VERSION "dbc-export 1 2025.20.8"

NS_ :

BS_:

BU_: APP BMS CC CMP CMPD CP DAS DI DIF DIR EPBL EPBR EVSE FC GTW HCML HCMR HVP ICR PCS PM PMF PMR PTC SCCM SCM SCS SDCR TAS UMC VC VCFRONT VCLEFT VCRIGHT VCSEC

BO_ 1444 PM_alertLog: 8 PM
 SG_ PM_alertID M : 0|7@1+ (1,0) [0|127] "" Vector__XXX
 SG_ PM_alertState : 15|1@1+ (1,0) [0|1] "" Vector__XXX
 SG_ PM_a001_w0 m1 : 16|16@1+ (1,0) [0|65535] "" Vector__XXX
 SG_ PM_a001_w1 m1 : 32|16@1+ (1,0) [0|65535] "" Vector__XXX
 SG_ PM_a001_w2 m1 : 48|16@1+ (1,0) [0|65535] "" Vector__XXX
 SG_ PM_a002_torqueAverage m2 : 16|1@1+ (1,0) [0|1] "" Vector__XXX
 SG_ PM_a002_torqueWindow m2 : 17|1@1+ (1,0) [0|1] "" Vector__XXX
 SG_ PM_a002_torqueMeasured m2 : 18|13@1- (2,0) [-8192|8190] "Nm" Vector__XXX
 SG_ PM_a002_torqueAccelAverage m2 : 32|13@1- (2,0) [-8192|8190] "Nm" Vector__XXX
 SG_ PM_a002_torqueAccelWindow m2 : 48|13@1- (2,0) [-8192|8190] "Nm" Vector__XXX
 SG_ PM_a003_reverseGear m3 : 16|1@1+ (1,0) [0|1] "" Vector__XXX
 SG_ PM_a003_pedalPos m3 : 24|8@1+ (0.4,0) [0|102] "%" Vector__XXX
 SG_ PM_a003_zeroPointPedal m3 : 32|8@1+ (0.4,0) [0|102] "%" Vector__XXX
 SG_ PM_a004_torqueAverage m4 : 16|1@1+ (1,0) [0|1] "" Vector__XXX
 SG_ PM_a004_torqueWindow m4 : 17|1@1+ (1,0) [0|1] "" Vector__XXX
 SG_ PM_a004_torqueMeasured m4 : 18|13@1- (2,0) [-8192|8190] "Nm" Vector__XXX
 SG_ PM_a004_torqueDecelAverage m4 : 32|13@1- (2,0) [-8192|8190] "Nm" Vector__XXX
 SG_ PM_a004_torqueDecelWindow m4 : 48|13@1- (2,0) [-8192|8190] "Nm" Vector__XXX
 SG_ PM_a005_torqueReason m5 : 16|2@1+ (1,0) [0|3] "" Vector__XXX
 SG_ PM_a005_torqueMeasured m5 : 18|13@1- (2,0) [-8192|8190] "Nm" Vector__XXX
 SG_ PM_a005_iDQmagnitude m5 : 32|16@1- (0.0939,0) [-3076.9152|3076.8213] "A" Vector__XXX
 SG_ PM_a006_unknownGearAllowed m6 : 16|1@1+ (1,0) [0|1] "" Vector__XXX
 SG_ PM_a006_parkGearAllowed m6 : 17|1@1+ (1,0) [0|1] "" Vector__XXX
 SG_ PM_a006_reverseGearAllowed m6 : 18|1@1+ (1,0) [0|1] "" Vector__XXX
 SG_ PM_a006_neutralGearAllowed m6 : 19|1@1+ (1,0) [0|1] "" Vector__XXX
 SG_ PM_a006_driveGearAllowed m6 : 20|1@1+ (1,0) [0|1] "" Vector__XXX
 SG_ PM_a006_shiftState m6 : 21|3@1+ (1,0) [0|6] "" Vector__XXX
 SG_ PM_a006_brakePedalPress m6 : 24|1@1+ (1,0) [0|1] "" Vector__XXX
 SG_ PM_a006_accelPedalBelowLimit m6 : 25|1@1+ (1,0) [0|1] "" Vector__XXX
 SG_ PM_a006_allowReverseShiftSpeed m6 : 26|1@1+ (1,0) [0|1] "" Vector__XXX
 SG_ PM_a006_allowDriveShiftSpeed m6 : 27|1@1+ (1,0) [0|1] "" Vector__XXX
 SG_ PM_a006_requireAccelPedalCheckSp m6 : 28|1@1+ (1,0) [0|1] "" Vector__XXX
 SG_ PM_a006_requireParkSpeed m6 : 29|1@1+ (1,0) [0|1] "" Vector__XXX
 SG_ PM_a006_stalkCommandP m6 : 30|1@1+ (1,0) [0|1] "" Vector__XXX
 SG_ PM_a006_stalkCommandR m6 : 31|1@1+ (1,0) [0|1] "" Vector__XXX
 SG_ PM_a006_stalkCommandN m6 : 32|1@1+ (1,0) [0|1] "" Vector__XXX
 SG_ PM_a006_stalkCommandD m6 : 33|1@1+ (1,0) [0|1] "" Vector__XXX
 SG_ PM_a006_unsecuredNeutralRequest m6 : 34|1@1+ (1,0) [0|1] "" Vector__XXX
 SG_ PM_a006_recentGearChange m6 : 35|1@1+ (1,0) [0|1] "" Vector__XXX
 SG_ PM_a006_smartShiftCommandD m6 : 36|1@1+ (1,0) [0|1] "" Vector__XXX
 SG_ PM_a006_smartShiftCommandR m6 : 37|1@1+ (1,0) [0|1] "" Vector__XXX
 SG_ PM_a006_driverSeatbeltBuckled m6 : 38|1@1+ (1,0) [0|1] "" Vector__XXX
 SG_ PM_a006_secGearSelRisingEdgeR m6 : 39|1@1+ (1,0) [0|1] "" Vector__XXX
 SG_ PM_a006_secGearSelRisingEdgeN m6 : 40|1@1+ (1,0) [0|1] "" Vector__XXX
 SG_ PM_a006_secGearSelRisingEdgeD m6 : 41|1@1+ (1,0) [0|1] "" Vector__XXX
 SG_ PM_a007_IBST_party1 m7 : 16|1@1+ (1,0) [0|1] "" Vector__XXX
 SG_ PM_a007_BUS1_IBST_status m7 : 17|1@1+ (1,0) [0|1] "" Vector__XXX
 SG_ PM_a007_BUS2_IBST_status m7 : 18|1@1+ (1,0) [0|1] "" Vector__XXX
 SG_ PM_a009_ESP_brakeTorque m9 : 16|1@1+ (1,0) [0|1] "" Vector__XXX
 SG_ PM_a009_ESP_motorLimits m9 : 17|1@1+ (1,0) [0|1] "" Vector__XXX
 SG_ PM_a009_ESP_offsets m9 : 18|1@1+ (1,0) [0|1] "" Vector__XXX
 SG_ PM_a009_ESP_party3 m9 : 19|1@1+ (1,0) [0|1] "" Vector__XXX
 SG_ PM_a009_ESP_status m9 : 20|1@1+ (1,0) [0|1] "" Vector__XXX
 SG_ PM_a009_ESP_wheelSpeeds m9 : 21|1@1+ (1,0) [0|1] "" Vector__XXX
 SG_ PM_a010_messageId m10 : 16|16@1+ (1,0) [0|65535] "" Vector__XXX
 SG_ PM_a010_DI_status m10 : 32|1@1+ (1,0) [0|1] "" Vector__XXX
 SG_ PM_a010_DI_torque m10 : 33|1@1+ (1,0) [0|1] "" Vector__XXX
 SG_ PM_a010_DI_slaveCommand m10 : 34|1@1+ (1,0) [0|1] "" Vector__XXX
 SG_ PM_a010_DI_locStatus m10 : 35|1@1+ (1,0) [0|1] "" Vector__XXX
 SG_ PM_a010_DI_speed m10 : 36|1@1+ (1,0) [0|1] "" Vector__XXX
 SG_ PM_a010_DI_systemStatus m10 : 37|1@1+ (1,0) [0|1] "" Vector__XXX
 SG_ PM_a010_DI_chassisControl m10 : 38|1@1+ (1,0) [0|1] "" Vector__XXX
 SG_ PM_a010_DI_chassisControl2 m10 : 39|1@1+ (1,0) [0|1] "" Vector__XXX
 SG_ PM_a010_vdcLeft m10 : 40|1@1+ (1,0) [0|1] "" Vector__XXX
 SG_ PM_a010_vdcRight m10 : 41|1@1+ (1,0) [0|1] "" Vector__XXX
 SG_ PM_a010_DI_vehicleEstimates m10 : 42|1@1+ (1,0) [0|1] "" Vector__XXX
 SG_ PM_a010_DI_brakeCommand m10 : 43|1@1+ (1,0) [0|1] "" Vector__XXX
 SG_ PM_a010_DI_difCommand m10 : 44|1@1+ (1,0) [0|1] "" Vector__XXX
 SG_ PM_a010_DI_dirCommand m10 : 45|1@1+ (1,0) [0|1] "" Vector__XXX
 SG_ PM_a010_DI_dirVehicle m10 : 46|1@1+ (1,0) [0|1] "" Vector__XXX
 SG_ PM_a010_DI_locStatus2 m10 : 47|1@1+ (1,0) [0|1] "" Vector__XXX
 SG_ PM_a010_stalklessInterfaces m10 : 48|1@1+ (1,0) [0|1] "" Vector__XXX
 SG_ PM_a011_pmfHvilStatus m11 : 16|2@1+ (1,0) [0|2] "" Vector__XXX
 SG_ PM_a011_pmfStatusValid m11 : 18|1@1+ (1,0) [0|1] "" Vector__XXX
 SG_ PM_a011_pmrHvilStatus m11 : 19|2@1+ (1,0) [0|2] "" Vector__XXX
 SG_ PM_a011_pmrStatusValid m11 : 21|1@1+ (1,0) [0|1] "" Vector__XXX
 SG_ PM_a011_vehiclePowerState m11 : 22|2@1+ (1,0) [0|3] "" Vector__XXX
 SG_ PM_a011_hvilSystemStatus m11 : 24|2@1+ (1,0) [0|2] "" Vector__XXX
 SG_ PM_a012_canID m12 : 16|12@1+ (1,0) [0|4095] "" Vector__XXX
 SG_ PM_a012_errorType m12 : 28|3@1+ (1,0) [0|7] "" Vector__XXX
 SG_ PM_a012_badValue1 m12 : 32|16@1+ (1,0) [0|65535] "" Vector__XXX
 SG_ PM_a012_badValue2 m12 : 48|16@1+ (1,0) [0|65535] "" Vector__XXX
 SG_ PM_a013_mailboxID m13 : 16|16@1+ (1,0) [0|65535] "" Vector__XXX
 SG_ PM_a013_canID m13 : 32|16@1+ (1,0) [0|65535] "" Vector__XXX
 SG_ PM_a013_errorType m13 : 48|3@1+ (1,0) [0|7] "" Vector__XXX
 SG_ PM_a014_track1Voltage m14 : 16|16@1+ (0.001,0) [0|65.535] "V" Vector__XXX
 SG_ PM_a014_track2Voltage m14 : 32|16@1+ (0.001,0) [0|65.535] "V" Vector__XXX
 SG_ PM_a014_accelErrorType m14 : 48|2@1+ (1,0) [1|3] "" Vector__XXX
 SG_ PM_a015_SCCM_rightStalk m15 : 16|1@1+ (1,0) [0|1] "" Vector__XXX
 SG_ PM_a016_BB_status m16 : 16|1@1+ (1,0) [0|1] "" Vector__XXX
 SG_ PM_a016_BB_brakeActuation m16 : 17|1@1+ (1,0) [0|1] "" Vector__XXX
 SG_ PM_a017_EPBL_status m17 : 16|1@1+ (1,0) [0|1] "" Vector__XXX
 SG_ PM_a017_EPBR_status m17 : 17|1@1+ (1,0) [0|1] "" Vector__XXX
 SG_ PM_a021_torque m21 : 16|1@1+ (1,0) [0|1] "" Vector__XXX
 SG_ PM_a021_capability m21 : 17|1@1+ (1,0) [0|1] "" Vector__XXX
 SG_ PM_a021_status m21 : 18|1@1+ (1,0) [0|1] "" Vector__XXX
 SG_ PM_a021_capability2 m21 : 19|1@1+ (1,0) [0|1] "" Vector__XXX
 SG_ PM_a021_power m21 : 20|1@1+ (1,0) [0|1] "" Vector__XXX
 SG_ PM_a022_torque m22 : 16|1@1+ (1,0) [0|1] "" Vector__XXX
 SG_ PM_a022_capability m22 : 17|1@1+ (1,0) [0|1] "" Vector__XXX
 SG_ PM_a022_status m22 : 18|1@1+ (1,0) [0|1] "" Vector__XXX
 SG_ PM_a022_capability2 m22 : 19|1@1+ (1,0) [0|1] "" Vector__XXX
 SG_ PM_a022_power m22 : 20|1@1+ (1,0) [0|1] "" Vector__XXX
 SG_ PM_a023_diCrsState m23 : 16|3@1+ (1,0) [0|7] "" Vector__XXX
 SG_ PM_a023_pmCrsState m23 : 19|3@1+ (1,0) [0|7] "" Vector__XXX
 SG_ PM_a023_crsFaultReason m23 : 24|5@1+ (1,0) [0|31] "" Vector__XXX
 SG_ PM_a023_crsCancelReason m23 : 29|4@1+ (1,0) [0|15] "" Vector__XXX
 SG_ PM_a023_cruiseTorquePed m23 : 33|11@1- (1,0) [-1024|1023] "Nm" Vector__XXX
 SG_ PM_a023_wheelSpdEstimateAbs m23 : 44|10@1+ (0.25,0) [0|255.75] "kph" Vector__XXX
 SG_ PM_a023_accelEstimateDis m23 : 54|10@1- (0.05,-4.7) [-30.3|20.85] "m/s^2" Vector__XXX
 SG_ PM_a025_powerOnReset m25 : 16|1@1+ (1,0) [0|1] "" Vector__XXX
 SG_ PM_a025_watchdogTimer0 m25 : 17|1@1+ (1,0) [0|1] "" Vector__XXX
 SG_ PM_a025_watchdogTimer1 m25 : 18|1@1+ (1,0) [0|1] "" Vector__XXX
 SG_ PM_a025_watchdogTimer2 m25 : 19|1@1+ (1,0) [0|1] "" Vector__XXX
 SG_ PM_a025_watchdogTimer3 m25 : 20|1@1+ (1,0) [0|1] "" Vector__XXX
 SG_ PM_a025_warmResetReq m25 : 21|1@1+ (1,0) [0|1] "" Vector__XXX
 SG_ PM_a025_externalPadReset m25 : 22|1@1+ (1,0) [0|1] "" Vector__XXX
 SG_ PM_a025_hwSecModuleWatchdogTimer m25 : 23|1@1+ (1,0) [0|1] "" Vector__XXX
 SG_ PM_a025_debugReset m25 : 24|1@1+ (1,0) [0|1] "" Vector__XXX
 SG_ PM_a025_tempSense0 m25 : 25|1@1+ (1,0) [0|1] "" Vector__XXX
 SG_ PM_a025_tempSense1 m25 : 26|1@1+ (1,0) [0|1] "" Vector__XXX
 SG_ PM_a026_reason m26 : 16|1@1+ (1,0) [0|1] "" Vector__XXX
 SG_ PM_a026_isrCount20kHz m26 : 17|5@1+ (1,0) [0|31] "" Vector__XXX
 SG_ PM_a026_isrCount1kHz m26 : 22|4@1+ (1,0) [0|15] "" Vector__XXX
 SG_ PM_a026_switchingActive m26 : 26|1@1+ (1,0) [0|1] "" Vector__XXX
 SG_ PM_a026_systemStackOvf m26 : 27|1@1+ (1,0) [0|1] "" Vector__XXX
 SG_ PM_a026_controlStackOvf m26 : 28|1@1+ (1,0) [0|1] "" Vector__XXX
 SG_ PM_a026_idleStackOvf m26 : 29|1@1+ (1,0) [0|1] "" Vector__XXX
 SG_ PM_a026_eepStackOvf m26 : 30|1@1+ (1,0) [0|1] "" Vector__XXX
 SG_ PM_a026_immStackOvf m26 : 31|1@1+ (1,0) [0|1] "" Vector__XXX
 SG_ PM_a026_xdcErrorIdMSW m26 : 32|10@1+ (1,0) [0|1023] "" Vector__XXX
 SG_ PM_a026_xdcErrorArg1 m26 : 42|22@1- (1,0) [-2097152|2097151] "" Vector__XXX
 SG_ PM_a030_diAebState m30 : 16|3@1+ (1,0) [0|6] "" Vector__XXX
 SG_ PM_a030_pmAebState m30 : 19|3@1+ (1,0) [0|6] "" Vector__XXX
 SG_ PM_a030_dasAebEvent m30 : 22|2@1+ (1,0) [0|2] "" Vector__XXX
 SG_ PM_a030_aebFaultReason m30 : 24|3@1+ (1,0) [0|7] "" Vector__XXX
 SG_ PM_a030_aebUnavailableReason m30 : 27|4@1+ (1,0) [0|15] "" Vector__XXX
 SG_ PM_a030_aebCancelReason m30 : 32|2@1+ (1,0) [0|3] "" Vector__XXX
 SG_ PM_a030_diBrakeTorqueCommand m30 : 34|13@1+ (2,0) [0|16382] "Nm" Vector__XXX
 SG_ PM_a032_w0 m32 : 16|16@1+ (1,0) [0|65535] "" Vector__XXX
 SG_ PM_a032_w1 m32 : 32|16@1+ (1,0) [0|65535] "" Vector__XXX
 SG_ PM_a032_w2 m32 : 48|16@1+ (1,0) [0|65535] "" Vector__XXX
 SG_ PM_a036_timeSinceTxHWI m36 : 16|6@1+ (64,0) [0|4032] "us" Vector__XXX
 SG_ PM_a036_timeSinceRxHWI m36 : 22|6@1+ (64,0) [0|4032] "us" Vector__XXX
 SG_ PM_a036_timeSince100HzTxSWI m36 : 28|6@1+ (0.32,0) [0|20.16] "ms" Vector__XXX
 SG_ PM_a036_timeSince1kHzCLK m36 : 34|6@1+ (32,0) [0|2016] "us" Vector__XXX
 SG_ PM_a036_timeSince1kHzSWI m36 : 40|6@1+ (32,0) [0|2016] "us" Vector__XXX
 SG_ PM_a036_timeSinceIdle m36 : 46|6@1+ (0.16,0) [0|10.08] "ms" Vector__XXX
 SG_ PM_a036_ovfStackId m36 : 52|4@1+ (1,0) [0|14] "" Vector__XXX
 SG_ PM_a036_inTxISR m36 : 56|1@1+ (1,0) [0|1] "" Vector__XXX
 SG_ PM_a036_inTxHWI m36 : 57|1@1+ (1,0) [0|1] "" Vector__XXX
 SG_ PM_a036_inRxHWI m36 : 58|1@1+ (1,0) [0|1] "" Vector__XXX
 SG_ PM_a036_in1kHzSWI m36 : 59|1@1+ (1,0) [0|1] "" Vector__XXX
 SG_ PM_a036_in1kHzCLK m36 : 60|1@1+ (1,0) [0|1] "" Vector__XXX
 SG_ PM_a036_in100HzCLK m36 : 61|1@1+ (1,0) [0|1] "" Vector__XXX
 SG_ PM_a036_in10HzCLK m36 : 62|1@1+ (1,0) [0|1] "" Vector__XXX
 SG_ PM_a036_in1HzCLK m36 : 63|1@1+ (1,0) [0|1] "" Vector__XXX
 SG_ PM_a038_masterTorque m38 : 16|13@1- (0.4,0) [-1638.4|1638] "Nm" Vector__XXX
 SG_ PM_a038_slaveTorque m38 : 32|13@1- (0.4,0) [-1638.4|1638] "Nm" Vector__XXX
 SG_ PM_a038_pedalPos m38 : 48|8@1- (0.4,50.4) [-0.8|101.2] "%" Vector__XXX
 SG_ PM_a039_DIS_status m39 : 16|1@1+ (1,0) [0|1] "" Vector__XXX
 SG_ PM_a039_DIS_torque m39 : 17|1@1+ (1,0) [0|1] "" Vector__XXX
 SG_ PM_a039_messageId m39 : 24|16@1+ (1,0) [0|65535] "" Vector__XXX
 SG_ PM_a041_DAS_control m41 : 16|1@1+ (1,0) [0|1] "" Vector__XXX
 SG_ PM_a041_DAS_longControl m41 : 17|1@1+ (1,0) [0|1] "" Vector__XXX
 SG_ PM_a041_DAS_longControlTuningPar m41 : 18|1@1+ (1,0) [0|1] "" Vector__XXX
 SG_ PM_a041_DAS_status m41 : 19|1@1+ (1,0) [0|1] "" Vector__XXX
 SG_ PM_a041_DAS_status2 m41 : 20|1@1+ (1,0) [0|1] "" Vector__XXX
 SG_ PM_a041_DAS_smartShift m41 : 21|1@1+ (1,0) [0|1] "" Vector__XXX
 SG_ PM_a042_GTW_carConfig m42 : 16|1@1+ (1,0) [0|1] "" Vector__XXX
 SG_ PM_a042_GTW_time m42 : 17|1@1+ (1,0) [0|1] "" Vector__XXX
 SG_ PM_a042_GTW_drivetrainType m42 : 18|2@1+ (1,0) [0|3] "" Vector__XXX
 SG_ PM_a042_expectedPerformanceCfg m42 : 20|2@1+ (1,0) [0|3] "" Vector__XXX
 SG_ PM_a042_gearControl m42 : 22|1@1+ (1,0) [0|1] "" Vector__XXX
 SG_ PM_a043_configInconsistent m43 : 16|1@1+ (1,0) [0|1] "" Vector__XXX
 SG_ PM_a043_GTW_autopilot m43 : 17|1@1+ (1,0) [0|1] "" Vector__XXX
 SG_ PM_a043_expectedAutopilot m43 : 18|1@1+ (1,0) [0|1] "" Vector__XXX
 SG_ PM_a043_GTW_drivetrainType m43 : 19|2@1+ (1,0) [0|3] "" Vector__XXX
 SG_ PM_a043_expectedDrivetrainType m43 : 21|2@1+ (1,0) [0|3] "" Vector__XXX
 SG_ PM_a043_GTW_chassisType m43 : 24|2@1+ (1,0) [0|3] "" Vector__XXX
 SG_ PM_a043_expectedChassisType m43 : 26|2@1+ (1,0) [0|3] "" Vector__XXX
 SG_ PM_a043_packEnergy m43 : 28|1@1+ (1,0) [0|1] "" Vector__XXX
 SG_ PM_a043_packPerformanceDeviation m43 : 29|1@1+ (1,0) [0|1] "" Vector__XXX
 SG_ PM_a043_performancePackage m43 : 30|1@1+ (1,0) [0|1] "" Vector__XXX
 SG_ PM_a043_GTW_vdcType m43 : 31|1@1+ (1,0) [0|1] "" Vector__XXX
 SG_ PM_a043_expectedVdcType m43 : 32|1@1+ (1,0) [0|1] "" Vector__XXX
 SG_ PM_a043_brakeHWType m43 : 33|1@1+ (1,0) [0|1] "" Vector__XXX
 SG_ PM_a043_cabinPTCHeaterType m43 : 34|1@1+ (1,0) [0|1] "" Vector__XXX
 SG_ PM_a043_softPerformanceLimit m43 : 35|1@1+ (1,0) [0|1] "" Vector__XXX
 SG_ PM_a043_GTW_dasHw m43 : 36|1@1+ (1,0) [0|1] "" Vector__XXX
 SG_ PM_a044_pmCruiseState m44 : 16|3@1+ (1,0) [0|7] "" Vector__XXX
 SG_ PM_a044_diCruiseState m44 : 19|3@1+ (1,0) [0|7] "" Vector__XXX
 SG_ PM_a044_pmAebState m44 : 24|3@1+ (1,0) [0|6] "" Vector__XXX
 SG_ PM_a044_diAebState m44 : 27|3@1+ (1,0) [0|6] "" Vector__XXX
 SG_ PM_a044_diBrakeTorqueCommand m44 : 30|13@1+ (2,0) [0|16382] "Nm" Vector__XXX
 SG_ PM_a044_pmBfillTorqueAllowed m44 : 43|13@1+ (2,0) [0|16382] "Nm" Vector__XXX
 SG_ PM_a044_pmVehicleHoldState m44 : 56|3@1+ (1,0) [0|7] "" Vector__XXX
 SG_ PM_a044_diVehicleHoldState m44 : 59|3@1+ (1,0) [0|7] "" Vector__XXX
 SG_ PM_a044_regenBackfillPmState m44 : 62|2@1+ (1,0) [0|3] "" Vector__XXX
 SG_ PM_a045_regenBackfillPmState m45 : 16|2@1+ (1,0) [0|3] "" Vector__XXX
 SG_ PM_a045_regenBackfillDiState m45 : 18|2@1+ (1,0) [0|3] "" Vector__XXX
 SG_ PM_a045_unavailableReason m45 : 24|5@1+ (1,0) [0|31] "" Vector__XXX
 SG_ PM_a045_diBrakeTorqueCommand m45 : 32|13@1+ (2,0) [0|16382] "Nm" Vector__XXX
 SG_ PM_a045_pmBrakeTorqueAllowed m45 : 48|13@1+ (2,0) [0|16382] "Nm" Vector__XXX
 SG_ PM_a046_diVhldState m46 : 16|3@1+ (1,0) [0|7] "" Vector__XXX
 SG_ PM_a046_pmVhldState m46 : 19|3@1+ (1,0) [0|7] "" Vector__XXX
 SG_ PM_a046_vhldFaultReason m46 : 24|3@1+ (1,0) [0|7] "" Vector__XXX
 SG_ PM_a046_vhldUnavailableReason m46 : 27|4@1+ (1,0) [0|15] "" Vector__XXX
 SG_ PM_a046_diBrakeTorqueCommand m46 : 32|13@1+ (2,0) [0|16382] "Nm" Vector__XXX
 SG_ PM_a046_diBrakeCommandType m46 : 45|3@1+ (1,0) [0|7] "" Vector__XXX
 SG_ PM_a047_pmAutoparkState m47 : 16|4@1+ (1,0) [0|14] "" Vector__XXX
 SG_ PM_a047_diAutoparkState m47 : 20|4@1+ (1,0) [0|14] "" Vector__XXX
 SG_ PM_a047_autoparkCancelReason m47 : 24|2@1+ (1,0) [0|3] "" Vector__XXX
 SG_ PM_a048_vdcFaultReason m48 : 16|4@1+ (1,0) [0|15] "" Vector__XXX
 SG_ PM_a053_LVPowerState m53 : 16|1@1+ (1,0) [0|1] "" Vector__XXX
 SG_ PM_a053_coolant m53 : 17|1@1+ (1,0) [0|1] "" Vector__XXX
 SG_ PM_a053_vcleftSwitchStatus m53 : 18|1@1+ (1,0) [0|1] "" Vector__XXX
 SG_ PM_a053_restraintStatus m53 : 19|1@1+ (1,0) [0|1] "" Vector__XXX
 SG_ PM_a053_sensors m53 : 20|1@1+ (1,0) [0|1] "" Vector__XXX
 SG_ PM_a054_uiPowertrainControl m54 : 16|1@1+ (1,0) [0|1] "" Vector__XXX
 SG_ PM_a054_uiChassisControl m54 : 17|1@1+ (1,0) [0|1] "" Vector__XXX
 SG_ PM_a054_uiCruiseControl m54 : 18|1@1+ (1,0) [0|1] "" Vector__XXX
 SG_ PM_a054_uiTrackModeSettings m54 : 19|1@1+ (1,0) [0|1] "" Vector__XXX
 SG_ PM_a054_uiTPMSRCPSetting m54 : 20|1@1+ (1,0) [0|1] "" Vector__XXX
 SG_ PM_a056_mailboxID m56 : 16|16@1+ (1,0) [0|65535] "" Vector__XXX
 SG_ PM_a056_canID m56 : 32|16@1+ (1,0) [0|65535] "" Vector__XXX
 SG_ PM_a056_errorType m56 : 48|3@1+ (1,0) [0|7] "" Vector__XXX
 SG_ PM_a057_canID m57 : 16|12@1+ (1,0) [0|4095] "" Vector__XXX
 SG_ PM_a057_errorType m57 : 28|3@1+ (1,0) [0|7] "" Vector__XXX
 SG_ PM_a057_badValue1 m57 : 32|16@1+ (1,0) [0|65535] "" Vector__XXX
 SG_ PM_a057_badValue2 m57 : 48|16@1+ (1,0) [0|65535] "" Vector__XXX
 SG_ PM_a058_CMP_HVStatus m58 : 16|1@1+ (1,0) [0|1] "" Vector__XXX
 SG_ PM_a058_CMPD_state m58 : 17|1@1+ (1,0) [0|1] "" Vector__XXX
 SG_ PM_a059_PTC_feedbackStatus m59 : 16|1@1+ (1,0) [0|1] "" Vector__XXX
 SG_ PM_a060_TorqueAccelWindow m60 : 16|16@1- (0.05,0) [-1638.4|1638.35] "NmS" Vector__XXX
 SG_ PM_a060_TorqueDecelWindow m60 : 32|16@1- (0.05,0) [-1638.4|1638.35] "NmS" Vector__XXX
 SG_ PM_a060_TorqueReversalWindow m60 : 48|16@1- (0.05,0) [-1638.4|1638.35] "NmS" Vector__XXX
 SG_ PM_a061_diIpcVersion m61 : 16|8@1+ (1,0) [0|255] "" Vector__XXX
 SG_ PM_a061_pmIpcVersion m61 : 24|8@1+ (1,0) [0|255] "" Vector__XXX
 SG_ PM_a062_address m62 : 16|32@1+ (1,0) [0|4294967295] "" Vector__XXX
 SG_ PM_a062_errorType m62 : 48|4@1+ (1,0) [0|15] "" Vector__XXX
 SG_ PM_a063_totalSystemTorqueCommand m63 : 16|13@1- (0.4,0) [-1638.4|1638] "Nm" Vector__XXX
 SG_ PM_a063_totalSystemTorqueMeasure m63 : 32|13@1- (0.4,0) [-1638.4|1638] "Nm" Vector__XXX
 SG_ PM_a064_interventionType m64 : 16|4@1+ (1,0) [0|15] "" Vector__XXX
 SG_ PM_a064_torqueCmdState m64 : 20|4@1+ (1,0) [1|15] "" Vector__XXX
 SG_ PM_a064_shortDetectedByDI m64 : 24|1@1+ (1,0) [0|1] "" Vector__XXX
 SG_ PM_a064_UI_stoppingMode m64 : 25|2@1+ (1,0) [0|3] "" Vector__XXX
 SG_ PM_a064_diCrsState m64 : 27|3@1+ (1,0) [0|7] "" Vector__XXX
 SG_ PM_a064_pmCrsState m64 : 32|3@1+ (1,0) [0|7] "" Vector__XXX
 SG_ PM_a066_state4 m66 : 16|1@1+ (1,0) [0|1] "" Vector__XXX
 SG_ PM_a067_state4 m67 : 16|1@1+ (1,0) [0|1] "" Vector__XXX
 SG_ PM_a073_canID m73 : 16|12@1+ (1,0) [0|4095] "" Vector__XXX
 SG_ PM_a073_errorType m73 : 28|3@1+ (1,0) [0|7] "" Vector__XXX
 SG_ PM_a073_badValue1 m73 : 32|16@1+ (1,0) [0|65535] "" Vector__XXX
 SG_ PM_a073_badValue2 m73 : 48|16@1+ (1,0) [0|65535] "" Vector__XXX
 SG_ PM_a074_mailboxID m74 : 16|16@1+ (1,0) [0|65535] "" Vector__XXX
 SG_ PM_a074_canID m74 : 32|16@1+ (1,0) [0|65535] "" Vector__XXX
 SG_ PM_a074_errorType m74 : 48|3@1+ (1,0) [0|7] "" Vector__XXX
 SG_ PM_a075_canID m75 : 16|12@1+ (1,0) [0|4095] "" Vector__XXX
 SG_ PM_a075_errorType m75 : 28|3@1+ (1,0) [0|7] "" Vector__XXX
 SG_ PM_a075_badValue1 m75 : 32|16@1+ (1,0) [0|65535] "" Vector__XXX
 SG_ PM_a075_badValue2 m75 : 48|16@1+ (1,0) [0|65535] "" Vector__XXX
 SG_ PM_a076_mailboxID m76 : 16|16@1+ (1,0) [0|65535] "" Vector__XXX
 SG_ PM_a076_canID m76 : 32|16@1+ (1,0) [0|65535] "" Vector__XXX
 SG_ PM_a076_errorType m76 : 48|3@1+ (1,0) [0|7] "" Vector__XXX
 SG_ PM_a077_canID m77 : 16|12@1+ (1,0) [0|4095] "" Vector__XXX
 SG_ PM_a077_errorType m77 : 28|3@1+ (1,0) [0|7] "" Vector__XXX
 SG_ PM_a077_badValue1 m77 : 32|16@1+ (1,0) [0|65535] "" Vector__XXX
 SG_ PM_a077_badValue2 m77 : 48|16@1+ (1,0) [0|65535] "" Vector__XXX
 SG_ PM_a078_mailboxID m78 : 16|16@1+ (1,0) [0|65535] "" Vector__XXX
 SG_ PM_a078_canID m78 : 32|16@1+ (1,0) [0|65535] "" Vector__XXX
 SG_ PM_a078_errorType m78 : 48|3@1+ (1,0) [0|7] "" Vector__XXX
 SG_ PM_a079_VEH_RCU_actuation m79 : 16|1@1+ (1,0) [0|1] "" Vector__XXX
 SG_ PM_a079_PARTY_RCU_actuation m79 : 17|1@1+ (1,0) [0|1] "" Vector__XXX
 SG_ PM_a082_faultAddress m82 : 16|32@1+ (1,0) [0|4294967295] "" Vector__XXX
 SG_ PM_a082_isWriteNotRead m82 : 48|1@1+ (1,0) [0|1] "" Vector__XXX
 SG_ PM_a084_faultAddress m84 : 16|32@1+ (1,0) [0|4294967295] "" Vector__XXX
 SG_ PM_a084_firewallId m84 : 48|5@1+ (1,0) [0|31] "" Vector__XXX
 SG_ PM_a084_privId m84 : 56|4@1+ (1,0) [0|15] "" Vector__XXX
 SG_ PM_a084_ns m84 : 60|1@1+ (1,0) [0|1] "" Vector__XXX
 SG_ PM_a084_faultType m84 : 61|3@1+ (1,0) [0|7] "" Vector__XXX
 SG_ PM_a085_DPB_actuator3 m85 : 16|1@1+ (1,0) [0|1] "" Vector__XXX
 SG_ PM_a087_mailboxID m87 : 16|16@1+ (1,0) [0|65535] "" Vector__XXX
 SG_ PM_a087_canID m87 : 32|16@1+ (1,0) [0|65535] "" Vector__XXX
 SG_ PM_a087_errorType m87 : 48|3@1+ (1,0) [0|7] "" Vector__XXX
 SG_ PM_a092_pllClockSource m92 : 16|2@1+ (1,0) [0|3] "" Vector__XXX
 SG_ PM_a100_index1kHzPeriodic m100 : 16|8@1+ (1,0) [0|255] "" Vector__XXX
 SG_ PM_a100_index100HzPeriodic m100 : 24|8@1+ (1,0) [0|255] "" Vector__XXX
 SG_ PM_a100_index10HzPeriodic m100 : 32|8@1+ (1,0) [0|255] "" Vector__XXX
 SG_ PM_a100_indexSWI m100 : 40|8@1+ (1,0) [0|255] "" Vector__XXX
 SG_ PM_a100_eepEvent m100 : 48|8@1+ (1,0) [0|255] "" Vector__XXX
 SG_ PM_a100_module500HzActive m100 : 56|1@1+ (1,0) [0|1] "" Vector__XXX
 SG_ PM_a100_module50HzActive m100 : 57|1@1+ (1,0) [0|1] "" Vector__XXX
 SG_ PM_a100_module1HzActive m100 : 58|1@1+ (1,0) [0|1] "" Vector__XXX
 SG_ PM_a100_task10HzActive m100 : 59|1@1+ (1,0) [0|1] "" Vector__XXX
 SG_ PM_a100_taskUdsActive m100 : 60|1@1+ (1,0) [0|1] "" Vector__XXX

BO_ 1551 PM_info: 8 PM
 SG_ PM_infoIndex M : 0|8@1+ (1,0) [0|255] "" Vector__XXX
 SG_ PM_buildType m10 : 8|8@1+ (1,0) [0|255] "" Vector__XXX
 SG_ PM_buildConfigurationId m10 : 16|16@1+ (1,0) [0|65535] "" Vector__XXX
 SG_ PM_hardwareId m10 : 32|8@1+ (1,0) [0|252] "" Vector__XXX
 SG_ PM_deviceFused m10 : 40|1@1+ (1,0) [0|1] "" Vector__XXX
 SG_ PM_componentId m10 : 48|16@1+ (1,0) [0|65535] "" Vector__XXX
 SG_ PM_pcbaId m11 : 16|8@1+ (1,0) [0|255] "" Vector__XXX
 SG_ PM_assemblyId m11 : 24|8@1+ (1,0) [0|255] "" Vector__XXX
 SG_ PM_usageId m11 : 32|16@1+ (1,0) [0|65535] "" Vector__XXX
 SG_ PM_subUsageId m11 : 48|16@1+ (1,0) [0|65535] "" Vector__XXX
 SG_ PM_applicationCrc m13 : 32|32@1+ (1,0) [0|4294967295] "" Vector__XXX
 SG_ PM_bootGitHash m18 : 8|56@1+ (1,0) [0|7.20575940379e+16] "" Vector__XXX

BO_ 1766 PNCD_IsoTpPipeToCp: 8 GTW
 SG_ PNCD_isoTpToCpData : 0|64@1+ (1,0) [0|1.84467440737e+19] "" Vector__XXX

BO_ 837 PTC_info: 8 PTC
 SG_ PTC_infoIndex M : 0|8@1+ (1,0) [0|255] "" Vector__XXX
 SG_ PTC_infoBuildType m10 : 8|3@1+ (1,0) [0|7] "" Vector__XXX
 SG_ PTC_infoBuildConfigId m10 : 16|16@1+ (1,0) [0|65535] "" Vector__XXX
 SG_ PTC_infoHardwareId m10 : 32|16@1+ (1,0) [0|65535] "" Vector__XXX
 SG_ PTC_infoComponentId m10 : 48|16@1+ (1,0) [0|65535] "" Vector__XXX
 SG_ PTC_infoPcbaId m11 : 16|8@1+ (1,0) [0|255] "" Vector__XXX
 SG_ PTC_infoAssemblyId m11 : 24|8@1+ (1,0) [0|254] "" Vector__XXX
 SG_ PTC_infoUsageId m11 : 32|16@1+ (1,0) [0|65535] "" Vector__XXX
 SG_ PTC_infoSubUsageId m11 : 48|16@1+ (1,0) [0|65535] "" Vector__XXX
 SG_ PTC_infoPlatformType m13 : 8|8@1+ (1,0) [0|255] "" Vector__XXX
 SG_ PTC_infoAppCrc m13 : 32|32@1+ (1,0) [0|4294967295] "" Vector__XXX
 SG_ PTC_infoBootUdsProtoVersion m20 : 8|8@1+ (1,0) [0|255] "" Vector__XXX
 SG_ PTC_infoBootCrc m20 : 32|32@1+ (1,0) [0|4294967295] "" Vector__XXX

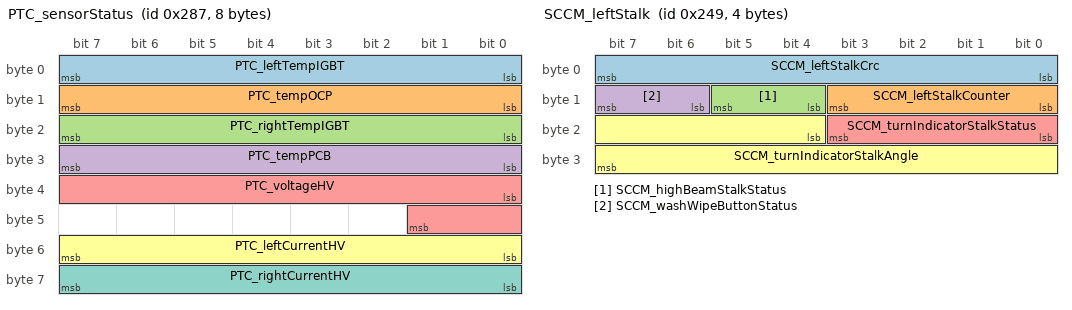
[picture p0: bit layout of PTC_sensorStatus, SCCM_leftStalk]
BO_ 647 PTC_sensorStatus: 8 PTC
 SG_ PTC_leftTempIGBT : 0|8@1+ (1,-40) [-40|200] "degC" Vector__XXX
 SG_ PTC_tempOCP : 8|8@1+ (1,-40) [-40|200] "degC" Vector__XXX
 SG_ PTC_rightTempIGBT : 16|8@1+ (1,-40) [-40|200] "degC" Vector__XXX
 SG_ PTC_tempPCB : 24|8@1+ (1,-40) [-40|200] "degC" Vector__XXX
 SG_ PTC_voltageHV : 32|10@1+ (0.5,0) [0|511.5] "V" Vector__XXX
 SG_ PTC_leftCurrentHV : 48|8@1+ (0.2,0) [0|50] "A" Vector__XXX
 SG_ PTC_rightCurrentHV : 56|8@1+ (0.2,0) [0|50] "A" Vector__XXX

BO_ 1344 SCCM_alertLog: 8 SCCM
 SG_ SCCM_alertID M : 0|15@1+ (1,0) [0|32767] "" Vector__XXX
 SG_ SCCM_alertState : 15|1@1+ (1,0) [0|1] "" Vector__XXX
 SG_ SCCM_a003_debouncePosition m3 : 16|8@1+ (1,0) [0|255] "-" Vector__XXX
 SG_ SCCM_a003_rawPosition m3 : 24|8@1+ (1,0) [0|255] "-" Vector__XXX
 SG_ SCCM_a003_errorPosition m3 : 32|8@1+ (1,0) [0|255] "-" Vector__XXX
 SG_ SCCM_a003_adcValue m3 : 40|8@1+ (1,0) [0|255] "-" Vector__XXX
 SG_ SCCM_a004_debouncePosition m4 : 16|8@1+ (1,0) [0|255] "-" Vector__XXX
 SG_ SCCM_a004_rawPosition m4 : 24|8@1+ (1,0) [0|255] "-" Vector__XXX
 SG_ SCCM_a004_errorPosition m4 : 32|8@1+ (1,0) [0|255] "-" Vector__XXX
 SG_ SCCM_a004_adcValue m4 : 40|8@1+ (1,0) [0|255] "-" Vector__XXX
 SG_ SCCM_a005_debouncePosition m5 : 16|8@1+ (1,0) [0|255] "-" Vector__XXX
 SG_ SCCM_a005_rawPosition m5 : 24|8@1+ (1,0) [0|255] "-" Vector__XXX
 SG_ SCCM_a005_errorPosition m5 : 32|8@1+ (1,0) [0|255] "-" Vector__XXX
 SG_ SCCM_a005_adcValue m5 : 40|8@1+ (1,0) [0|255] "-" Vector__XXX
 SG_ SCCM_a006_debouncePosition m6 : 16|8@1+ (1,0) [0|255] "-" Vector__XXX
 SG_ SCCM_a006_rawPosition m6 : 24|8@1+ (1,0) [0|255] "-" Vector__XXX
 SG_ SCCM_a006_errorPosition m6 : 32|8@1+ (1,0) [0|255] "-" Vector__XXX
 SG_ SCCM_a006_adcValue m6 : 40|8@1+ (1,0) [0|255] "-" Vector__XXX
 SG_ SCCM_a007_debouncePosition m7 : 16|8@1+ (1,0) [0|255] "-" Vector__XXX
 SG_ SCCM_a007_rawPosition m7 : 24|8@1+ (1,0) [0|255] "-" Vector__XXX
 SG_ SCCM_a007_errorPosition m7 : 32|8@1+ (1,0) [0|255] "-" Vector__XXX
 SG_ SCCM_a007_adcValue1 m7 : 40|8@1+ (1,0) [0|255] "-" Vector__XXX
 SG_ SCCM_a007_adcValue2 m7 : 48|8@1+ (1,0) [0|255] "-" Vector__XXX
 SG_ SCCM_a008_debouncePosition m8 : 16|8@1+ (1,0) [0|255] "-" Vector__XXX
 SG_ SCCM_a008_rawPosition m8 : 24|8@1+ (1,0) [0|255] "-" Vector__XXX
 SG_ SCCM_a008_errorPosition m8 : 32|8@1+ (1,0) [0|255] "-" Vector__XXX
 SG_ SCCM_a008_adcValue1 m8 : 40|8@1+ (1,0) [0|255] "-" Vector__XXX
 SG_ SCCM_a008_adcValue2 m8 : 48|8@1+ (1,0) [0|255] "-" Vector__XXX
 SG_ SCCM_a009_debouncePosition m9 : 16|8@1+ (1,0) [0|255] "-" Vector__XXX
 SG_ SCCM_a009_rawPosition m9 : 24|8@1+ (1,0) [0|255] "-" Vector__XXX
 SG_ SCCM_a009_errorPosition m9 : 32|8@1+ (1,0) [0|255] "-" Vector__XXX
 SG_ SCCM_a009_adcValue1 m9 : 40|8@1+ (1,0) [0|255] "-" Vector__XXX
 SG_ SCCM_a009_adcValue2 m9 : 48|8@1+ (1,0) [0|255] "-" Vector__XXX
 SG_ SCCM_a010_debouncePosition m10 : 16|8@1+ (1,0) [0|255] "-" Vector__XXX
 SG_ SCCM_a010_rawPosition m10 : 24|8@1+ (1,0) [0|255] "-" Vector__XXX
 SG_ SCCM_a010_errorPosition m10 : 32|8@1+ (1,0) [0|255] "-" Vector__XXX
 SG_ SCCM_a010_adcValue1 m10 : 40|8@1+ (1,0) [0|255] "-" Vector__XXX
 SG_ SCCM_a010_adcValue2 m10 : 48|8@1+ (1,0) [0|255] "-" Vector__XXX
 SG_ SCCM_a011_debouncePosition m11 : 16|8@1+ (1,0) [0|255] "-" Vector__XXX
 SG_ SCCM_a011_rawPosition m11 : 24|8@1+ (1,0) [0|255] "-" Vector__XXX
 SG_ SCCM_a011_errorPosition m11 : 32|8@1+ (1,0) [0|255] "-" Vector__XXX
 SG_ SCCM_a011_adcValue1 m11 : 40|8@1+ (1,0) [0|255] "-" Vector__XXX
 SG_ SCCM_a011_adcValue2 m11 : 48|8@1+ (1,0) [0|255] "-" Vector__XXX
 SG_ SCCM_a012_debouncePosition m12 : 16|8@1+ (1,0) [0|255] "-" Vector__XXX
 SG_ SCCM_a012_rawPosition m12 : 24|8@1+ (1,0) [0|255] "-" Vector__XXX
 SG_ SCCM_a012_errorPosition m12 : 32|8@1+ (1,0) [0|255] "-" Vector__XXX
 SG_ SCCM_a012_adcValue1 m12 : 40|8@1+ (1,0) [0|255] "-" Vector__XXX
 SG_ SCCM_a012_adcValue2 m12 : 48|8@1+ (1,0) [0|255] "-" Vector__XXX
 SG_ SCCM_a013_voltage m13 : 16|8@1+ (1,0) [0|255] "-" Vector__XXX
 SG_ SCCM_a014_voltage m14 : 16|8@1+ (1,0) [0|255] "-" Vector__XXX
 SG_ SCCM_a015_intMainIndex m15 : 16|8@1+ (1,0) [0|255] "-" Vector__XXX
 SG_ SCCM_a015_intSubIndex m15 : 24|8@1+ (1,0) [0|255] "-" Vector__XXX
 SG_ SCCM_a015_intMemIndex m15 : 32|8@1+ (1,0) [0|255] "-" Vector__XXX
 SG_ SCCM_a016_mainAdcTest m16 : 16|4@1+ (1,0) [0|15] "-" Vector__XXX
 SG_ SCCM_a016_mainCpuTest m16 : 20|4@1+ (1,0) [0|15] "-" Vector__XXX
 SG_ SCCM_a016_wdtTest m16 : 24|4@1+ (1,0) [0|15] "-" Vector__XXX
 SG_ SCCM_a016_subCpuTest m16 : 28|4@1+ (1,0) [0|15] "-" Vector__XXX
 SG_ SCCM_a016_subAdcTest m16 : 32|4@1+ (1,0) [0|15] "-" Vector__XXX
 SG_ SCCM_a017_mainRamTest m17 : 16|4@1+ (1,0) [0|15] "-" Vector__XXX
 SG_ SCCM_a017_mainRomTest m17 : 20|4@1+ (1,0) [0|15] "-" Vector__XXX
 SG_ SCCM_a017_stackHardLimitTest m17 : 24|4@1+ (1,0) [0|15] "-" Vector__XXX
 SG_ SCCM_a017_mainDataFlashTest m17 : 28|4@1+ (1,0) [0|15] "-" Vector__XXX
 SG_ SCCM_a017_subRamTest m17 : 32|4@1+ (1,0) [0|15] "-" Vector__XXX
 SG_ SCCM_a017_subRomTest m17 : 36|4@1+ (1,0) [0|15] "-" Vector__XXX
 SG_ SCCM_a017_subStackHardLimitTest m17 : 40|4@1+ (1,0) [0|15] "-" Vector__XXX
 SG_ SCCM_a017_svError m17 : 44|16@1+ (1,0) [0|65535] "-" Vector__XXX
 SG_ SCCM_a018_internalSASState m18 : 16|8@1+ (1,0) [0|255] "-" Vector__XXX
 SG_ SCCM_a019_internalSASState m19 : 16|8@1+ (1,0) [0|255] "-" Vector__XXX
 SG_ SCCM_a020_internalSASState m20 : 16|8@1+ (1,0) [0|255] "-" Vector__XXX
 SG_ SCCM_a021_adcValue1 m21 : 16|8@1+ (1,0) [0|255] "-" Vector__XXX
 SG_ SCCM_a021_adcValue2 m21 : 24|8@1+ (1,0) [0|255] "-" Vector__XXX
 SG_ SCCM_a021_adcValue3 m21 : 32|8@1+ (1,0) [0|255] "-" Vector__XXX
 SG_ SCCM_a021_adcValue4 m21 : 40|8@1+ (1,0) [0|255] "-" Vector__XXX
 SG_ SCCM_a021_adcValue5 m21 : 48|8@1+ (1,0) [0|255] "-" Vector__XXX
 SG_ SCCM_a021_adcValue6 m21 : 56|8@1+ (1,0) [0|255] "-" Vector__XXX
 SG_ SCCM_a022_adcValue1 m22 : 16|8@1+ (1,0) [0|255] "-" Vector__XXX
 SG_ SCCM_a022_adcValue2 m22 : 24|8@1+ (1,0) [0|255] "-" Vector__XXX
 SG_ SCCM_a022_adcValue3 m22 : 32|8@1+ (1,0) [0|255] "-" Vector__XXX
 SG_ SCCM_a022_adcValue4 m22 : 40|8@1+ (1,0) [0|255] "-" Vector__XXX
 SG_ SCCM_a022_adcValue5 m22 : 48|8@1+ (1,0) [0|255] "-" Vector__XXX
 SG_ SCCM_a022_adcValue6 m22 : 56|8@1+ (1,0) [0|255] "-" Vector__XXX
 SG_ SCCM_a023_adcValue1 m23 : 16|8@1+ (1,0) [0|255] "-" Vector__XXX
 SG_ SCCM_a023_adcValue2 m23 : 24|8@1+ (1,0) [0|255] "-" Vector__XXX
 SG_ SCCM_a023_adcValue3 m23 : 32|8@1+ (1,0) [0|255] "-" Vector__XXX
 SG_ SCCM_a023_adcValue4 m23 : 40|8@1+ (1,0) [0|255] "-" Vector__XXX
 SG_ SCCM_a023_adcValue5 m23 : 48|8@1+ (1,0) [0|255] "-" Vector__XXX
 SG_ SCCM_a023_adcValue6 m23 : 56|8@1+ (1,0) [0|255] "-" Vector__XXX
 SG_ SCCM_a024_adcValue1 m24 : 16|8@1+ (1,0) [0|255] "-" Vector__XXX
 SG_ SCCM_a024_adcValue2 m24 : 24|8@1+ (1,0) [0|255] "-" Vector__XXX
 SG_ SCCM_a024_adcValue3 m24 : 32|8@1+ (1,0) [0|255] "-" Vector__XXX
 SG_ SCCM_a024_adcValue4 m24 : 40|8@1+ (1,0) [0|255] "-" Vector__XXX
 SG_ SCCM_a024_adcValue5 m24 : 48|8@1+ (1,0) [0|255] "-" Vector__XXX
 SG_ SCCM_a024_adcValue6 m24 : 56|8@1+ (1,0) [0|255] "-" Vector__XXX
 SG_ SCCM_a025_taskState m25 : 16|16@1+ (1,0) [0|65535] "-" Vector__XXX
 SG_ SCCM_a026_debouncePosition m26 : 16|8@1+ (1,0) [0|255] "-" Vector__XXX
 SG_ SCCM_a026_rawPosition m26 : 24|8@1+ (1,0) [0|255] "-" Vector__XXX
 SG_ SCCM_a026_errorPosition m26 : 32|8@1+ (1,0) [0|255] "-" Vector__XXX
 SG_ SCCM_a026_adcValue1 m26 : 40|8@1+ (1,0) [0|255] "-" Vector__XXX
 SG_ SCCM_a026_adcValue2 m26 : 48|8@1+ (1,0) [0|255] "-" Vector__XXX
 SG_ SCCM_a027_debouncePosition m27 : 16|8@1+ (1,0) [0|255] "-" Vector__XXX
 SG_ SCCM_a027_rawPosition m27 : 24|8@1+ (1,0) [0|255] "-" Vector__XXX
 SG_ SCCM_a027_errorPosition m27 : 32|8@1+ (1,0) [0|255] "-" Vector__XXX
 SG_ SCCM_a027_adcValue1 m27 : 40|8@1+ (1,0) [0|255] "-" Vector__XXX
 SG_ SCCM_a027_adcValue2 m27 : 48|8@1+ (1,0) [0|255] "-" Vector__XXX
 SG_ SCCM_a028_debouncePosition m28 : 16|8@1+ (1,0) [0|255] "-" Vector__XXX
 SG_ SCCM_a028_rawPosition m28 : 24|8@1+ (1,0) [0|255] "-" Vector__XXX
 SG_ SCCM_a028_errorPosition m28 : 32|8@1+ (1,0) [0|255] "-" Vector__XXX
 SG_ SCCM_a028_adcValue1 m28 : 40|8@1+ (1,0) [0|255] "-" Vector__XXX
 SG_ SCCM_a028_adcValue2 m28 : 48|8@1+ (1,0) [0|255] "-" Vector__XXX
 SG_ SCCM_a029_debouncePosition m29 : 16|8@1+ (1,0) [0|255] "-" Vector__XXX
 SG_ SCCM_a029_rawPosition m29 : 24|8@1+ (1,0) [0|255] "-" Vector__XXX
 SG_ SCCM_a029_errorPosition m29 : 32|8@1+ (1,0) [0|255] "-" Vector__XXX
 SG_ SCCM_a029_adcValue1 m29 : 40|8@1+ (1,0) [0|255] "-" Vector__XXX
 SG_ SCCM_a029_adcValue2 m29 : 48|8@1+ (1,0) [0|255] "-" Vector__XXX
 SG_ SCCM_a061_voltage m61 : 16|8@1+ (0.1,0) [0|25.5] "V" Vector__XXX
 SG_ SCCM_a062_voltage m62 : 16|8@1+ (0.1,0) [0|25.5] "V" Vector__XXX
 SG_ SCCM_a063_UntrimmedAngle m63 : 16|16@1+ (0.1,-819.2) [-819.2|5734.3] "deg" Vector__XXX
 SG_ SCCM_a064_Speed m64 : 16|16@1+ (0.5,-4096) [-4096|28671.5] "deg/s" Vector__XXX
 SG_ SCCM_a065_M1RawAngleCurrent m65 : 16|12@1+ (0.08791209,0) [0|360.00000855] "deg" Vector__XXX
 SG_ SCCM_a065_M1RawAnglePrevious m65 : 28|12@1+ (0.08791209,0) [0|360.00000855] "deg" Vector__XXX
 SG_ SCCM_a065_M2RawAngleCurrent m65 : 40|12@1+ (0.08791209,0) [0|360.00000855] "deg" Vector__XXX
 SG_ SCCM_a065_M2RawAnglePrevious m65 : 52|12@1+ (0.08791209,0) [0|360.00000855] "deg" Vector__XXX
 SG_ SCCM_a066_M1RawAngleCurrent m66 : 16|12@1+ (0.08791209,0) [0|360.00000855] "deg" Vector__XXX
 SG_ SCCM_a066_M1RawAnglePrevious m66 : 28|12@1+ (0.08791209,0) [0|360.00000855] "deg" Vector__XXX
 SG_ SCCM_a066_M2RawAngleCurrent m66 : 40|12@1+ (0.08791209,0) [0|360.00000855] "deg" Vector__XXX
 SG_ SCCM_a066_M2RawAnglePrevious m66 : 52|12@1+ (0.08791209,0) [0|360.00000855] "deg" Vector__XXX
 SG_ SCCM_a071_M1LogicBISTFailed m71 : 16|1@1+ (1,0) [0|1] "" Vector__XXX
 SG_ SCCM_a071_M1PowerOnReset m71 : 17|1@1+ (1,0) [0|1] "" Vector__XXX
 SG_ SCCM_a071_M1UnderVoltage m71 : 18|1@1+ (1,0) [0|1] "" Vector__XXX
 SG_ SCCM_a071_M1OverVoltage m71 : 19|1@1+ (1,0) [0|1] "" Vector__XXX
 SG_ SCCM_a071_M1DualBitError m71 : 20|1@1+ (1,0) [0|1] "" Vector__XXX
 SG_ SCCM_a071_M1RefVoltageOutOfRange m71 : 21|1@1+ (1,0) [0|1] "" Vector__XXX
 SG_ SCCM_a071_M1RegisterParityError m71 : 22|1@1+ (1,0) [0|1] "" Vector__XXX
 SG_ SCCM_a071_M1OscillatorFreqError m71 : 23|1@1+ (1,0) [0|1] "" Vector__XXX
 SG_ SCCM_a071_M1SignalOutOfRange m71 : 24|1@1+ (1,0) [0|1] "" Vector__XXX
 SG_ SCCM_a071_M1TempOutOfRange m71 : 25|1@1+ (1,0) [0|1] "" Vector__XXX
 SG_ SCCM_a071_M1AngleMismatch m71 : 26|1@1+ (1,0) [0|1] "" Vector__XXX
 SG_ SCCM_a071_M1RadiusOutOfRange m71 : 27|1@1+ (1,0) [0|1] "" Vector__XXX
 SG_ SCCM_a071_M2LogicBISTFailed m71 : 28|1@1+ (1,0) [0|1] "" Vector__XXX
 SG_ SCCM_a071_M2PowerOnReset m71 : 29|1@1+ (1,0) [0|1] "" Vector__XXX
 SG_ SCCM_a071_M2UnderVoltage m71 : 30|1@1+ (1,0) [0|1] "" Vector__XXX
 SG_ SCCM_a071_M2OverVoltage m71 : 31|1@1+ (1,0) [0|1] "" Vector__XXX
 SG_ SCCM_a071_M2DualBitError m71 : 32|1@1+ (1,0) [0|1] "" Vector__XXX
 SG_ SCCM_a071_M2RefVoltageOutOfRange m71 : 33|1@1+ (1,0) [0|1] "" Vector__XXX
 SG_ SCCM_a071_M2RegisterParityError m71 : 34|1@1+ (1,0) [0|1] "" Vector__XXX
 SG_ SCCM_a071_M2OscillatorFreqError m71 : 35|1@1+ (1,0) [0|1] "" Vector__XXX
 SG_ SCCM_a071_M2SignalOutOfRange m71 : 36|1@1+ (1,0) [0|1] "" Vector__XXX
 SG_ SCCM_a071_M2TempOutOfRange m71 : 37|1@1+ (1,0) [0|1] "" Vector__XXX
 SG_ SCCM_a071_M2AngleMismatch m71 : 38|1@1+ (1,0) [0|1] "" Vector__XXX
 SG_ SCCM_a071_M2RadiusOutOfRange m71 : 39|1@1+ (1,0) [0|1] "" Vector__XXX
 SG_ SCCM_a071_M1ProcessLogicFailed m71 : 40|1@1+ (1,0) [0|1] "" Vector__XXX
 SG_ SCCM_a071_M2ProcessLogicFailed m71 : 41|1@1+ (1,0) [0|1] "" Vector__XXX
 SG_ SCCM_a071_TSOSCHighFreqError m71 : 42|1@1+ (1,0) [0|1] "" Vector__XXX
 SG_ SCCM_a071_TSOSCLowFreqError m71 : 43|1@1+ (1,0) [0|1] "" Vector__XXX
 SG_ SCCM_a071_TSOPRStatMismatch m71 : 44|1@1+ (1,0) [0|1] "" Vector__XXX
 SG_ SCCM_a071_TSCRCStatError m71 : 45|1@1+ (1,0) [0|1] "" Vector__XXX
 SG_ SCCM_a071_TSFrameStatError m71 : 46|1@1+ (1,0) [0|1] "" Vector__XXX
 SG_ SCCM_a071_TSOverVoltage m71 : 47|1@1+ (1,0) [0|1] "" Vector__XXX
 SG_ SCCM_a071_TSUnderVoltage m71 : 48|1@1+ (1,0) [0|1] "" Vector__XXX
 SG_ SCCM_a071_TSPowerOnReset m71 : 49|1@1+ (1,0) [0|1] "" Vector__XXX
 SG_ SCCM_a071_TSLDOStatError m71 : 50|1@1+ (1,0) [0|1] "" Vector__XXX
 SG_ SCCM_a071_TSTempOutOfRange m71 : 51|1@1+ (1,0) [0|1] "" Vector__XXX
 SG_ SCCM_a071_TSAlertIntegrityCheck m71 : 52|1@1+ (1,0) [0|1] "" Vector__XXX
 SG_ SCCM_a071_TSMemoryCRCError m71 : 53|1@1+ (1,0) [0|1] "" Vector__XXX
 SG_ SCCM_a071_TSAFECheck m71 : 54|1@1+ (1,0) [0|1] "" Vector__XXX
 SG_ SCCM_a071_TSADCCheck m71 : 55|1@1+ (1,0) [0|1] "" Vector__XXX
 SG_ SCCM_a071_TSConfigFault m71 : 56|1@1+ (1,0) [0|1] "" Vector__XXX
 SG_ SCCM_a072_M1CRCCalculated m72 : 16|4@1+ (1,0) [0|15] "" Vector__XXX
 SG_ SCCM_a072_M1CRCReceived m72 : 20|4@1+ (1,0) [0|15] "" Vector__XXX
 SG_ SCCM_a072_M2CRCCalculated m72 : 24|4@1+ (1,0) [0|15] "" Vector__XXX
 SG_ SCCM_a072_M2CRCReceived m72 : 28|4@1+ (1,0) [0|15] "" Vector__XXX
 SG_ SCCM_a072_TSCRCCalculated m72 : 32|4@1+ (1,0) [0|15] "" Vector__XXX
 SG_ SCCM_a072_TSCRCReceived m72 : 36|4@1+ (1,0) [0|15] "" Vector__XXX
 SG_ SCCM_a075_ClockOutOfRange m75 : 16|1@1+ (1,0) [0|1] "" Vector__XXX
 SG_ SCCM_a075_ExtWatchdogTestFailed m75 : 17|1@1+ (1,0) [0|1] "" Vector__XXX
 SG_ SCCM_a075_InterruptMonitorError m75 : 18|1@1+ (1,0) [0|1] "" Vector__XXX
 SG_ SCCM_a076_RAMTestFailed m76 : 16|1@1+ (1,0) [0|1] "" Vector__XXX
 SG_ SCCM_a076_NVMTestFailed m76 : 17|1@1+ (1,0) [0|1] "" Vector__XXX
 SG_ SCCM_a077_M1ExpectAngleCurrent m77 : 16|12@1+ (0.08791209,0) [0|360.00000855] "deg" Vector__XXX
 SG_ SCCM_a077_M1ExpectAnglePrevious m77 : 28|12@1+ (0.08791209,0) [0|360.00000855] "deg" Vector__XXX
 SG_ SCCM_a077_M1AngleCurrent m77 : 40|12@1+ (0.08791209,0) [0|360.00000855] "deg" Vector__XXX
 SG_ SCCM_a077_M1AnglePrevious m77 : 52|12@1+ (0.08791209,0) [0|360.00000855] "deg" Vector__XXX
 SG_ SCCM_a079_ChipTemperature m79 : 16|11@1+ (0.1,-50) [-50|154.7] "degC" Vector__XXX
 SG_ SCCM_a081_StartupTestStatus m81 : 16|3@1+ (1,0) [0|7] "" Vector__XXX
 SG_ SCCM_a081_sCheckTestFailedData m81 : 19|8@1+ (1,0) [0|255] "" Vector__XXX
 SG_ SCCM_a081_sBootTestFailedData m81 : 27|16@1+ (1,0) [0|65535] "" Vector__XXX
 SG_ SCCM_a081_BISTTestFailedData m81 : 43|16@1+ (1,0) [0|65535] "" Vector__XXX
 SG_ SCCM_a082_RuntimeTestStatus m82 : 16|2@1+ (1,0) [0|3] "" Vector__XXX
 SG_ SCCM_a082_sCheckTestFailedData m82 : 18|8@1+ (1,0) [0|255] "" Vector__XXX
 SG_ SCCM_a082_ArrayIntegrFailedData m82 : 26|8@1+ (1,0) [0|255] "" Vector__XXX
 SG_ SCCM_a121_turnIndicatorStalkAngl m121 : 16|12@1+ (0.1,-180) [-180|229.5] "deg" Vector__XXX
 SG_ SCCM_a121_turnIndicatorHallAngle m121 : 28|12@1+ (0.1,-180) [-180|229.5] "deg" Vector__XXX
 SG_ SCCM_a122_turnIndicatorSpeed m122 : 16|12@1+ (0.02,-36) [-36|45.9] "deg/ms" Vector__XXX
 SG_ SCCM_a123_turnIndicatorStalkAngl m123 : 16|12@1+ (0.1,-180) [-180|229.5] "deg" Vector__XXX
 SG_ SCCM_a124_turnIndicatorStalkAngl m124 : 16|12@1+ (0.1,-180) [-180|229.5] "deg" Vector__XXX
 SG_ SCCM_a125_turnIndicatorHallAngle m125 : 16|12@1+ (0.1,-180) [-180|229.5] "deg" Vector__XXX
 SG_ SCCM_a125_turnIndicatorVectorAng m125 : 28|12@1+ (0.1,-180) [-180|229.5] "deg" Vector__XXX
 SG_ SCCM_a126_turnIndicatorXVectorOu m126 : 16|1@1+ (1,0) [0|1] "" Vector__XXX
 SG_ SCCM_a126_turnIndicatorYVectorOu m126 : 17|1@1+ (1,0) [0|1] "" Vector__XXX
 SG_ SCCM_a126_turnIndicatorZVectorOu m126 : 18|1@1+ (1,0) [0|1] "" Vector__XXX
 SG_ SCCM_a126_turnIndicatorResu_0001 m126 : 19|1@1+ (1,0) [0|1] "" Vector__XXX
 SG_ SCCM_a126_turnIndicatorXMagnitud m126 : 24|8@1+ (1,0) [0|255] "mT" Vector__XXX
 SG_ SCCM_a126_turnIndicatorYMagnitud m126 : 32|8@1+ (1,0) [0|255] "mT" Vector__XXX
 SG_ SCCM_a126_turnIndicatorZMagnitud m126 : 40|8@1+ (1,0) [0|255] "mT" Vector__XXX
 SG_ SCCM_a126_turnIndicatorResultant m126 : 48|8@1+ (1,0) [0|255] "mT" Vector__XXX

BO_ 1359 SCCM_alertMatrix: 8 SCCM
 SG_ SCCM_matrixIndex M : 0|4@1+ (1,0) [0|15] "" Vector__XXX
 SG_ SCCM_a001_CANBusOff m0 : 4|1@1+ (1,0) [0|1] "" Vector__XXX
 SG_ SCCM_a002_CANTOut m0 : 5|1@1+ (1,0) [0|1] "" Vector__XXX
 SG_ SCCM_a003_highBeamOpen m0 : 6|1@1+ (1,0) [0|1] "" Vector__XXX
 SG_ SCCM_a004_highBeamShortToGND m0 : 7|1@1+ (1,0) [0|1] "" Vector__XXX
 SG_ SCCM_a005_tipWipeOpen m0 : 8|1@1+ (1,0) [0|1] "" Vector__XXX
 SG_ SCCM_a006_tipWipeShortToGND m0 : 9|1@1+ (1,0) [0|1] "" Vector__XXX
 SG_ SCCM_a007_turnIndComInfo m0 : 10|1@1+ (1,0) [0|1] "" Vector__XXX
 SG_ SCCM_a008_turnIndInvalidTrans m0 : 11|1@1+ (1,0) [0|1] "" Vector__XXX
 SG_ SCCM_a009_turnIndOpen m0 : 12|1@1+ (1,0) [0|1] "" Vector__XXX
 SG_ SCCM_a010_turnIndShortToGnd m0 : 13|1@1+ (1,0) [0|1] "" Vector__XXX
 SG_ SCCM_a011_turnIndHWErr m0 : 14|1@1+ (1,0) [0|1] "" Vector__XXX
 SG_ SCCM_a012_turnGenErr m0 : 15|1@1+ (1,0) [0|1] "" Vector__XXX
 SG_ SCCM_a013_voltageHigh m0 : 16|1@1+ (1,0) [0|1] "" Vector__XXX
 SG_ SCCM_a014_voltageLow m0 : 17|1@1+ (1,0) [0|1] "" Vector__XXX
 SG_ SCCM_a015_softwareError m0 : 18|1@1+ (1,0) [0|1] "" Vector__XXX
 SG_ SCCM_a016_hardwareError m0 : 19|1@1+ (1,0) [0|1] "" Vector__XXX
 SG_ SCCM_a017_memoryError m0 : 20|1@1+ (1,0) [0|1] "" Vector__XXX
 SG_ SCCM_a018_angleSpeedOutOfRange m0 : 21|1@1+ (1,0) [0|1] "" Vector__XXX
 SG_ SCCM_a019_angleOutOfRange m0 : 22|1@1+ (1,0) [0|1] "" Vector__XXX
 SG_ SCCM_a020_angleInternalError m0 : 23|1@1+ (1,0) [0|1] "" Vector__XXX
 SG_ SCCM_a021_gearStalkSignalInvalid m0 : 24|1@1+ (1,0) [0|1] "" Vector__XXX
 SG_ SCCM_a022_gearStalkOpenCircuit m0 : 25|1@1+ (1,0) [0|1] "" Vector__XXX
 SG_ SCCM_a023_gearStalkShortCircuit m0 : 26|1@1+ (1,0) [0|1] "" Vector__XXX
 SG_ SCCM_a024_gearStalkGenErr m0 : 27|1@1+ (1,0) [0|1] "" Vector__XXX
 SG_ SCCM_a025_runTimeError m0 : 28|1@1+ (1,0) [0|1] "" Vector__XXX
 SG_ SCCM_a026_parkButtonInvalidSigna m0 : 29|1@1+ (1,0) [0|1] "" Vector__XXX
 SG_ SCCM_a027_parkButtonOpenCircuit m0 : 30|1@1+ (1,0) [0|1] "" Vector__XXX
 SG_ SCCM_a028_parkButtonShortToGroun m0 : 31|1@1+ (1,0) [0|1] "" Vector__XXX
 SG_ SCCM_a029_parkButtonMalfunction m0 : 32|1@1+ (1,0) [0|1] "" Vector__XXX
 SG_ SCCM_a061_voltageHigh_2 m1 : 4|1@1+ (1,0) [0|1] "" Vector__XXX
 SG_ SCCM_a062_voltageLow_2 m1 : 5|1@1+ (1,0) [0|1] "" Vector__XXX
 SG_ SCCM_a063_angleOutOfRange_2 m1 : 6|1@1+ (1,0) [0|1] "" Vector__XXX
 SG_ SCCM_a064_angleSpeedOutOfRange_2 m1 : 7|1@1+ (1,0) [0|1] "" Vector__XXX
 SG_ SCCM_a065_angleNotPlausible m1 : 8|1@1+ (1,0) [0|1] "" Vector__XXX
 SG_ SCCM_a066_angleSpeedNotPlausible m1 : 9|1@1+ (1,0) [0|1] "" Vector__XXX
 SG_ SCCM_a067_CANBusOff_2 m1 : 10|1@1+ (1,0) [0|1] "" Vector__XXX
 SG_ SCCM_a068_CANLVPowerState_LOC m1 : 11|1@1+ (1,0) [0|1] "" Vector__XXX
 SG_ SCCM_a069_calibrationMismatch m1 : 12|1@1+ (1,0) [0|1] "" Vector__XXX
 SG_ SCCM_a070_angleTrimMismatch m1 : 13|1@1+ (1,0) [0|1] "" Vector__XXX
 SG_ SCCM_a071_angleHallSensorError m1 : 14|1@1+ (1,0) [0|1] "" Vector__XXX
 SG_ SCCM_a072_spiBitErrors m1 : 15|1@1+ (1,0) [0|1] "" Vector__XXX
 SG_ SCCM_a073_watchdogReset m1 : 16|1@1+ (1,0) [0|1] "" Vector__XXX
 SG_ SCCM_a074_PLLLossOfLock m1 : 17|1@1+ (1,0) [0|1] "" Vector__XXX
 SG_ SCCM_a075_hardwareError_2 m1 : 18|1@1+ (1,0) [0|1] "" Vector__XXX
 SG_ SCCM_a076_memoryError_2 m1 : 19|1@1+ (1,0) [0|1] "" Vector__XXX
 SG_ SCCM_a077_gearAngleNotPlausible m1 : 20|1@1+ (1,0) [0|1] "" Vector__XXX
 SG_ SCCM_a078_ADCCalibrationError m1 : 21|1@1+ (1,0) [0|1] "" Vector__XXX
 SG_ SCCM_a079_chipTempOutOfRange m1 : 22|1@1+ (1,0) [0|1] "" Vector__XXX
 SG_ SCCM_a080_ADCSelfTestFailed m1 : 23|1@1+ (1,0) [0|1] "" Vector__XXX
 SG_ SCCM_a081_startupTestFailed m1 : 24|1@1+ (1,0) [0|1] "" Vector__XXX
 SG_ SCCM_a082_runtimeTestFailed m1 : 25|1@1+ (1,0) [0|1] "" Vector__XXX
 SG_ SCCM_a121_turnIndicatorAngleInva m2 : 4|1@1+ (1,0) [0|1] "" Vector__XXX
 SG_ SCCM_a122_turnIndicatorSpeedInva m2 : 5|1@1+ (1,0) [0|1] "" Vector__XXX
 SG_ SCCM_a123_turnIndicatorStuckActi m2 : 6|1@1+ (1,0) [0|1] "" Vector__XXX
 SG_ SCCM_a124_turnIndicatorIdleInval m2 : 7|1@1+ (1,0) [0|1] "" Vector__XXX
 SG_ SCCM_a125_turnIndicatorHallAngle m2 : 8|1@1+ (1,0) [0|1] "" Vector__XXX
 SG_ SCCM_a126_turnIndicatorHallMagOu m2 : 9|1@1+ (1,0) [0|1] "" Vector__XXX

BO_ 816 SCCM_info: 8 SCCM
 SG_ SCCM_infoIndex M : 0|8@1+ (1,0) [0|255] "" Vector__XXX
 SG_ SCCM_infoBuildType m10 : 8|8@1+ (1,0) [0|255] "" Vector__XXX
 SG_ SCCM_infoBuildConfigId m10 : 16|16@1+ (1,0) [0|65535] "" Vector__XXX
 SG_ SCCM_infoHardwareId m10 : 32|16@1+ (1,0) [0|65535] "" Vector__XXX
 SG_ SCCM_infoComponentId m10 : 48|16@1+ (1,0) [0|65535] "" Vector__XXX
 SG_ SCCM_infoPcbaId m11 : 16|8@1+ (1,0) [0|255] "" Vector__XXX
 SG_ SCCM_infoAssemblyId m11 : 24|8@1+ (1,0) [0|255] "" Vector__XXX
 SG_ SCCM_infoUsageId m11 : 32|16@1+ (1,0) [0|65535] "" Vector__XXX
 SG_ SCCM_infoSubUsageId m11 : 48|16@1+ (1,0) [0|65535] "" Vector__XXX
 SG_ SCCM_infoPlatformType m13 : 8|8@1+ (1,0) [0|255] "" Vector__XXX
 SG_ SCCM_infoAppCrc m13 : 39|32@0+ (1,0) [0|4294967295] "" Vector__XXX
 SG_ SCCM_infoBootSvnRev m14 : 8|24@1+ (1,0) [0|16777215] "" Vector__XXX
 SG_ SCCM_infoBootSvnUrlHash m14 : 32|32@1+ (1,0) [0|4294967295] "" Vector__XXX
 SG_ SCCM_infoSubcomponent1Version m16 : 16|32@1+ (1,0) [0|4294967295] "" Vector__XXX
 SG_ SCCM_infoAppSvnHash m17 : 8|56@1+ (1,0) [0|7.20575940379e+16] "" Vector__XXX
 SG_ SCCM_infoBootSvnHash m18 : 8|56@1+ (1,0) [0|7.20575940379e+16] "" Vector__XXX
 SG_ SCCM_infoUdsProtoVersion m20 : 8|8@1+ (1,0) [0|255] "" Vector__XXX
 SG_ SCCM_infoBootCrc m20 : 32|32@1+ (1,0) [0|4294967295] "" Vector__XXX

BO_ 585 SCCM_leftStalk: 4 SCCM
 SG_ SCCM_leftStalkCrc : 0|8@1+ (1,0) [0|255] "" Vector__XXX
 SG_ SCCM_leftStalkCounter : 8|4@1+ (1,0) [0|15] "" Vector__XXX
 SG_ SCCM_highBeamStalkStatus : 12|2@1+ (1,0) [0|2] "" Vector__XXX
 SG_ SCCM_washWipeButtonStatus : 14|2@1+ (1,0) [0|2] "" Vector__XXX
 SG_ SCCM_turnIndicatorStalkStatus : 16|4@1+ (1,0) [0|15] "" Vector__XXX
 SG_ SCCM_turnIndicatorStalkAngle : 20|12@1+ (0.1,-180) [-180|180] "deg" Vector__XXX

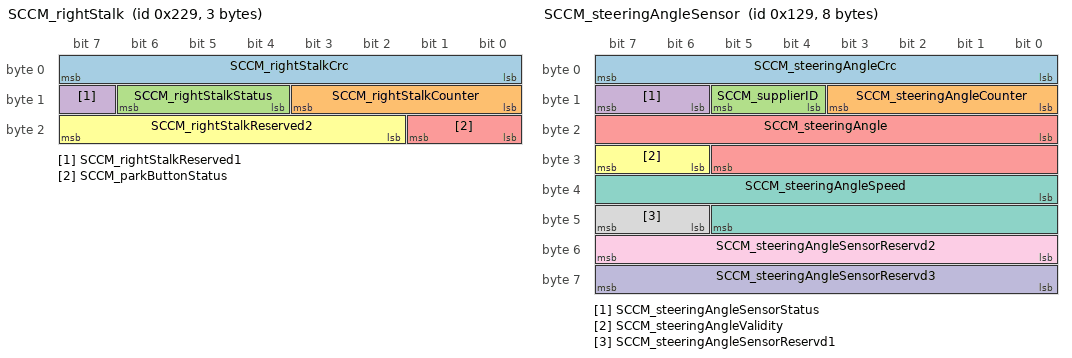
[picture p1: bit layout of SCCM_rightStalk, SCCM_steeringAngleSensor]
BO_ 553 SCCM_rightStalk: 3 SCCM
 SG_ SCCM_rightStalkCrc : 0|8@1+ (1,0) [0|255] "" Vector__XXX
 SG_ SCCM_rightStalkCounter : 8|4@1+ (1,0) [0|15] "" Vector__XXX
 SG_ SCCM_rightStalkStatus : 12|3@1+ (1,0) [0|7] "" Vector__XXX
 SG_ SCCM_rightStalkReserved1 : 15|1@1+ (1,0) [0|1] "" Vector__XXX
 SG_ SCCM_parkButtonStatus : 16|2@1+ (1,0) [0|2] "" Vector__XXX
 SG_ SCCM_rightStalkReserved2 : 18|6@1+ (1,0) [0|63] "" Vector__XXX

BO_ 297 SCCM_steeringAngleSensor: 8 SCCM
 SG_ SCCM_steeringAngleCrc : 0|8@1+ (1,0) [0|255] "" Vector__XXX
 SG_ SCCM_steeringAngleCounter : 8|4@1+ (1,0) [0|15] "" Vector__XXX
 SG_ SCCM_supplierID : 12|2@1+ (1,0) [0|3] "" Vector__XXX
 SG_ SCCM_steeringAngleSensorStatus : 14|2@1+ (1,0) [0|3] "" Vector__XXX
 SG_ SCCM_steeringAngle : 16|14@1+ (0.1,-819.2) [-819.2|819] "deg" Vector__XXX
 SG_ SCCM_steeringAngleValidity : 30|2@1+ (1,0) [0|2] "" Vector__XXX
 SG_ SCCM_steeringAngleSpeed : 32|14@1+ (0.5,-4096) [-4096|4095.5] "deg/s" Vector__XXX
 SG_ SCCM_steeringAngleSensorReservd1 : 46|2@1+ (1,0) [0|3] "" Vector__XXX
 SG_ SCCM_steeringAngleSensorReservd2 : 48|8@1+ (1,0) [0|255] "" Vector__XXX
 SG_ SCCM_steeringAngleSensorReservd3 : 56|8@1+ (1,0) [0|255] "" Vector__XXX

BO_ 1356 SCM_alertLog: 8 SCM
 SG_ SCM_alertID M : 0|15@1+ (1,0) [0|32767] "" Vector__XXX
 SG_ SCM_alertType : 15|1@1+ (1,0) [0|1] "" Vector__XXX
 SG_ SCM_a074_voltageWithRo m74 : 16|12@1+ (1,0) [0|4095] "" Vector__XXX
 SG_ SCM_a074_voltageWithoutRo m74 : 28|12@1+ (1,0) [0|4095] "" Vector__XXX

BO_ 815 SCM_alertMatrix1: 8 SCM
 SG_ SCM_a027_externalIsolationLow : 26|1@1+ (1,0) [0|1] "" Vector__XXX
 SG_ SCM_a044_proximityRationality : 43|1@1+ (1,0) [0|1] "" Vector__XXX

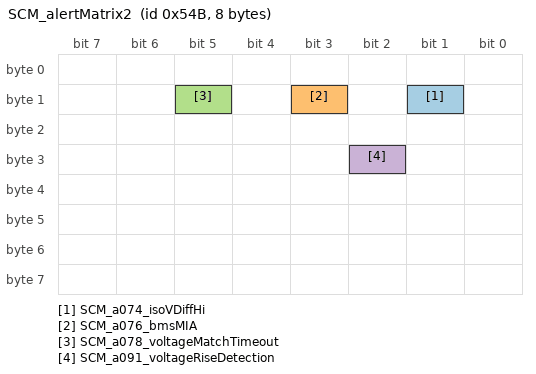
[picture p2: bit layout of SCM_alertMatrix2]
BO_ 1355 SCM_alertMatrix2: 8 SCM
 SG_ SCM_a074_isoVDiffHi : 9|1@1+ (1,0) [0|1] "" Vector__XXX
 SG_ SCM_a076_bmsMIA : 11|1@1+ (1,0) [0|1] "" Vector__XXX
 SG_ SCM_a078_voltageMatchTimeout : 13|1@1+ (1,0) [0|1] "" Vector__XXX
 SG_ SCM_a091_voltageRiseDetection : 26|1@1+ (1,0) [0|1] "" Vector__XXX

BO_ 1354 SCS_alertLog: 8 SCS
 SG_ SCS_alertID M : 0|15@1+ (1,0) [0|32767] "" Vector__XXX
 SG_ SCS_alertType : 15|1@1+ (1,0) [0|1] "" Vector__XXX
 SG_ SCS_a044_proximityV m44 : 16|16@1+ (0.0001,0) [0|6.5535] "V" Vector__XXX
 SG_ SCS_a074_voltageWithRo m74 : 16|12@1+ (0.146520152688,0) [0|600.000025257] "V" Vector__XXX
 SG_ SCS_a074_voltageWithoutRo m74 : 28|12@1+ (0.146520152688,0) [0|600.000025257] "V" Vector__XXX

BO_ 869 SCS_alertMatrix1: 8 SCS
 SG_ SCS_a001_hwDSPfault : 0|1@1+ (1,0) [0|1] "" Vector__XXX
 SG_ SCS_a002_hwIbatOC : 1|1@1+ (1,0) [0|1] "" Vector__XXX
 SG_ SCS_a003_hwCordOT : 2|1@1+ (1,0) [0|1] "" Vector__XXX
 SG_ SCS_a004_hwVbusOV : 3|1@1+ (1,0) [0|1] "" Vector__XXX
 SG_ SCS_a005_hwHVIL : 4|1@1+ (1,0) [0|1] "" Vector__XXX
 SG_ SCS_a006_hwWeld_V1 : 5|1@1+ (1,0) [0|1] "" Vector__XXX
 SG_ SCS_a007_hwWeld_V2 : 6|1@1+ (1,0) [0|1] "" Vector__XXX
 SG_ SCS_a008_hwIllegalCntrShoot : 7|1@1+ (1,0) [0|1] "" Vector__XXX
 SG_ SCS_a009_hwOpen_V1 : 8|1@1+ (1,0) [0|1] "" Vector__XXX
 SG_ SCS_a010_hwOpen_V2 : 9|1@1+ (1,0) [0|1] "" Vector__XXX
 SG_ SCS_a011_hwIllegalCntrCmdV1 : 10|1@1+ (1,0) [0|1] "" Vector__XXX
 SG_ SCS_a012_hwIllegalCntrCmdV2 : 11|1@1+ (1,0) [0|1] "" Vector__XXX
 SG_ SCS_a013_cordTempHiFoldBk : 12|1@1+ (1,0) [0|1] "" Vector__XXX
 SG_ SCS_a014_coolantTempHiFoldBk : 13|1@1+ (1,0) [0|1] "" Vector__XXX
 SG_ SCS_a015_cpldRationality : 14|1@1+ (1,0) [0|1] "" Vector__XXX
 SG_ SCS_a016_unusedHW16 : 15|1@1+ (1,0) [0|1] "" Vector__XXX
 SG_ SCS_a017_unusedHW17 : 16|1@1+ (1,0) [0|1] "" Vector__XXX
 SG_ SCS_a018_unusedHW18 : 17|1@1+ (1,0) [0|1] "" Vector__XXX
 SG_ SCS_a019_unusedHW19 : 18|1@1+ (1,0) [0|1] "" Vector__XXX
 SG_ SCS_a020_unusedHW20 : 19|1@1+ (1,0) [0|1] "" Vector__XXX
 SG_ SCS_a021_unusedHW21 : 20|1@1+ (1,0) [0|1] "" Vector__XXX
 SG_ SCS_a024_emergencyShutdown : 23|1@1+ (1,0) [0|1] "" Vector__XXX
 SG_ SCS_a025_internalIsolationFault : 24|1@1+ (1,0) [0|1] "" Vector__XXX
 SG_ SCS_a026_internalIsolationLow : 25|1@1+ (1,0) [0|1] "" Vector__XXX
 SG_ SCS_a027_externalIsolationLow : 26|1@1+ (1,0) [0|1] "" Vector__XXX
 SG_ SCS_a028_isolationRationality : 27|1@1+ (1,0) [0|1] "" Vector__XXX
 SG_ SCS_a029_VbatOV : 28|1@1+ (1,0) [0|1] "" Vector__XXX
 SG_ SCS_a030_VbusOV : 29|1@1+ (1,0) [0|1] "" Vector__XXX
 SG_ SCS_a031_IbatOC : 30|1@1+ (1,0) [0|1] "" Vector__XXX
 SG_ SCS_a032_VBatRationality : 31|1@1+ (1,0) [0|1] "" Vector__XXX
 SG_ SCS_a033_VBusRationality : 32|1@1+ (1,0) [0|1] "" Vector__XXX
 SG_ SCS_a034_IBatRationality : 33|1@1+ (1,0) [0|1] "" Vector__XXX
 SG_ SCS_a035_unexpectedVbusBehavior : 34|1@1+ (1,0) [0|1] "" Vector__XXX
 SG_ SCS_a036_internalContactorWelded : 35|1@1+ (1,0) [0|1] "" Vector__XXX
 SG_ SCS_a037_outputContactorWelded : 36|1@1+ (1,0) [0|1] "" Vector__XXX
 SG_ SCS_a038_contactorFailedOpen : 37|1@1+ (1,0) [0|1] "" Vector__XXX
 SG_ SCS_a039_ibatRegulation : 38|1@1+ (1,0) [0|1] "" Vector__XXX
 SG_ SCS_a040_plus12VOutOfRange : 39|1@1+ (1,0) [0|1] "" Vector__XXX
 SG_ SCS_a041_minus12VOutOfRange : 40|1@1+ (1,0) [0|1] "" Vector__XXX
 SG_ SCS_a042_pilotOutOfRange : 41|1@1+ (1,0) [0|1] "" Vector__XXX
 SG_ SCS_a043_pilotRationality : 42|1@1+ (1,0) [0|1] "" Vector__XXX
 SG_ SCS_a044_proximityRationality : 43|1@1+ (1,0) [0|1] "" Vector__XXX
 SG_ SCS_a045_pcbaOT : 44|1@1+ (1,0) [0|1] "" Vector__XXX
 SG_ SCS_a046_coolantOT : 45|1@1+ (1,0) [0|1] "" Vector__XXX
 SG_ SCS_a047_cordOT : 46|1@1+ (1,0) [0|1] "" Vector__XXX
 SG_ SCS_a048_ambientOT : 47|1@1+ (1,0) [0|1] "" Vector__XXX
 SG_ SCS_a049_pcbaTempRationality : 48|1@1+ (1,0) [0|1] "" Vector__XXX
 SG_ SCS_a050_coolantTempRationality : 49|1@1+ (1,0) [0|1] "" Vector__XXX
 SG_ SCS_a051_cordTempRationality : 50|1@1+ (1,0) [0|1] "" Vector__XXX
 SG_ SCS_a052_ambientTempRationality : 51|1@1+ (1,0) [0|1] "" Vector__XXX
 SG_ SCS_a053_unexpectedThermalBehavi : 52|1@1+ (1,0) [0|1] "" Vector__XXX
 SG_ SCS_a054_pumpRegulation : 53|1@1+ (1,0) [0|1] "" Vector__XXX
 SG_ SCS_a055_coolantLevelLow : 54|1@1+ (1,0) [0|1] "" Vector__XXX
 SG_ SCS_a056_stateTransitionDenied : 55|1@1+ (1,0) [0|1] "" Vector__XXX
 SG_ SCS_a057_watchdogReset : 56|1@1+ (1,0) [0|1] "" Vector__XXX
 SG_ SCS_a058_adcRef : 57|1@1+ (1,0) [0|1] "" Vector__XXX
 SG_ SCS_a059_memoryError : 58|1@1+ (1,0) [0|1] "" Vector__XXX
 SG_ SCS_a060_swHVIL : 59|1@1+ (1,0) [0|1] "" Vector__XXX
 SG_ SCS_a061_postOutOfService : 60|1@1+ (1,0) [0|1] "" Vector__XXX
 SG_ SCS_a062_unused : 61|1@1+ (1,0) [0|1] "" Vector__XXX
 SG_ SCS_a063_canRationality : 62|1@1+ (1,0) [0|1] "" Vector__XXX
 SG_ SCS_a064_vehicleCommandTimeout : 63|1@1+ (1,0) [0|1] "" Vector__XXX

BO_ 880 SCS_alertMatrix2: 8 SCS
 SG_ SCS_a065_vBatRationalityStage1 : 0|1@1+ (1,0) [0|1] "" Vector__XXX
 SG_ SCS_a066_vBatRationalityStage2 : 1|1@1+ (1,0) [0|1] "" Vector__XXX
 SG_ SCS_a067_vBatRationalityStage3 : 2|1@1+ (1,0) [0|1] "" Vector__XXX
 SG_ SCS_a068_vBatRationalityStage4 : 3|1@1+ (1,0) [0|1] "" Vector__XXX
 SG_ SCS_a069_vStageRationalityV1 : 4|1@1+ (1,0) [0|1] "" Vector__XXX
 SG_ SCS_a070_vStageRationalityV2 : 5|1@1+ (1,0) [0|1] "" Vector__XXX
 SG_ SCS_a071_chargerMIA : 6|1@1+ (1,0) [0|1] "" Vector__XXX
 SG_ SCS_a072_gtwMIA : 7|1@1+ (1,0) [0|1] "" Vector__XXX
 SG_ SCS_a073_lccMIA : 8|1@1+ (1,0) [0|1] "" Vector__XXX
 SG_ SCS_a074_isoVDiffHi : 9|1@1+ (1,0) [0|1] "" Vector__XXX
 SG_ SCS_a075_unused75 : 10|1@1+ (1,0) [0|1] "" Vector__XXX
 SG_ SCS_a076_bmsMIA : 11|1@1+ (1,0) [0|1] "" Vector__XXX
 SG_ SCS_a077_unexpectedVbatBehavior : 12|1@1+ (1,0) [0|1] "" Vector__XXX
 SG_ SCS_a078_voltageMatchTimeout : 13|1@1+ (1,0) [0|1] "" Vector__XXX
 SG_ SCS_a079_unexpectedVbat : 14|1@1+ (1,0) [0|1] "" Vector__XXX
 SG_ SCS_a080_lccFaulted : 15|1@1+ (1,0) [0|1] "" Vector__XXX
 SG_ SCS_a081_rmsInputVoltageHigh : 16|1@1+ (1,0) [0|1] "" Vector__XXX
 SG_ SCS_a082_VbatUV : 17|1@1+ (1,0) [0|1] "" Vector__XXX
 SG_ SCS_a083_chargeCurrentLimited : 18|1@1+ (1,0) [0|1] "" Vector__XXX
 SG_ SCS_a084_unused84 : 19|1@1+ (1,0) [0|1] "" Vector__XXX
 SG_ SCS_a085_unused85 : 20|1@1+ (1,0) [0|1] "" Vector__XXX
 SG_ SCS_a086_lccResetDetected : 21|1@1+ (1,0) [0|1] "" Vector__XXX
 SG_ SCS_a087_posCordTempRationality : 22|1@1+ (1,0) [0|1] "" Vector__XXX
 SG_ SCS_a088_negCordTempRationality : 23|1@1+ (1,0) [0|1] "" Vector__XXX
 SG_ SCS_a089_posCordOT : 24|1@1+ (1,0) [0|1] "" Vector__XXX
 SG_ SCS_a090_negCordOT : 25|1@1+ (1,0) [0|1] "" Vector__XXX
 SG_ SCS_a091_voltageRiseDetection : 26|1@1+ (1,0) [0|1] "" Vector__XXX
 SG_ SCS_a092_cabEnableDeasserted : 27|1@1+ (1,0) [0|1] "" Vector__XXX
 SG_ SCS_a093_unused93 : 28|1@1+ (1,0) [0|1] "" Vector__XXX
 SG_ SCS_a094_unused94 : 29|1@1+ (1,0) [0|1] "" Vector__XXX
 SG_ SCS_a095_unused95 : 30|1@1+ (1,0) [0|1] "" Vector__XXX
 SG_ SCS_a096_unused96 : 31|1@1+ (1,0) [0|1] "" Vector__XXX
 SG_ SCS_a097_unused97 : 32|1@1+ (1,0) [0|1] "" Vector__XXX
 SG_ SCS_a098_unused98 : 33|1@1+ (1,0) [0|1] "" Vector__XXX
 SG_ SCS_a099_unused99 : 34|1@1+ (1,0) [0|1] "" Vector__XXX
 SG_ SCS_a100_unused100 : 35|1@1+ (1,0) [0|1] "" Vector__XXX
 SG_ SCS_a101_unused101 : 36|1@1+ (1,0) [0|1] "" Vector__XXX
 SG_ SCS_a102_unused102 : 37|1@1+ (1,0) [0|1] "" Vector__XXX
 SG_ SCS_a103_unused103 : 38|1@1+ (1,0) [0|1] "" Vector__XXX
 SG_ SCS_a104_unused104 : 39|1@1+ (1,0) [0|1] "" Vector__XXX
 SG_ SCS_a105_unused105 : 40|1@1+ (1,0) [0|1] "" Vector__XXX
 SG_ SCS_a106_unused106 : 41|1@1+ (1,0) [0|1] "" Vector__XXX
 SG_ SCS_a107_unused107 : 42|1@1+ (1,0) [0|1] "" Vector__XXX
 SG_ SCS_a108_unused108 : 43|1@1+ (1,0) [0|1] "" Vector__XXX
 SG_ SCS_a109_unused109 : 44|1@1+ (1,0) [0|1] "" Vector__XXX
 SG_ SCS_a110_unused110 : 45|1@1+ (1,0) [0|1] "" Vector__XXX
 SG_ SCS_a111_unused111 : 46|1@1+ (1,0) [0|1] "" Vector__XXX
 SG_ SCS_a112_unused112 : 47|1@1+ (1,0) [0|1] "" Vector__XXX
 SG_ SCS_a113_unused113 : 48|1@1+ (1,0) [0|1] "" Vector__XXX
 SG_ SCS_a114_unused114 : 49|1@1+ (1,0) [0|1] "" Vector__XXX
 SG_ SCS_a115_unused115 : 50|1@1+ (1,0) [0|1] "" Vector__XXX
 SG_ SCS_a116_unused116 : 51|1@1+ (1,0) [0|1] "" Vector__XXX
 SG_ SCS_a117_unused117 : 52|1@1+ (1,0) [0|1] "" Vector__XXX
 SG_ SCS_a118_unused118 : 53|1@1+ (1,0) [0|1] "" Vector__XXX
 SG_ SCS_a119_unused119 : 54|1@1+ (1,0) [0|1] "" Vector__XXX
 SG_ SCS_a120_unused120 : 55|1@1+ (1,0) [0|1] "" Vector__XXX
 SG_ SCS_a121_unused121 : 56|1@1+ (1,0) [0|1] "" Vector__XXX
 SG_ SCS_a122_unused122 : 57|1@1+ (1,0) [0|1] "" Vector__XXX
 SG_ SCS_a123_unused123 : 58|1@1+ (1,0) [0|1] "" Vector__XXX
 SG_ SCS_a124_unused124 : 59|1@1+ (1,0) [0|1] "" Vector__XXX
 SG_ SCS_a125_unused125 : 60|1@1+ (1,0) [0|1] "" Vector__XXX
 SG_ SCS_a126_unused126 : 61|1@1+ (1,0) [0|1] "" Vector__XXX
 SG_ SCS_a127_unused127 : 62|1@1+ (1,0) [0|1] "" Vector__XXX
 SG_ SCS_a128_unused128 : 63|1@1+ (1,0) [0|1] "" Vector__XXX

BO_ 1531 SDCR_alertLog: 8 SDCR
 SG_ SDCR_alertID M : 0|6@1+ (1,0) [0|63] "" Vector__XXX
 SG_ SDCR_alertState : 15|1@1+ (1,0) [0|1] "" Vector__XXX
 SG_ SDCR_a001_pyroSenseV m1 : 16|8@1+ (0.02,0) [0|5.1] "V" Vector__XXX
 SG_ SDCR_a001_HVBackupSupplyV m1 : 24|8@1+ (0.15,0) [0|38.25] "V" Vector__XXX
 SG_ SDCR_a001_boostRailV m1 : 32|8@1+ (0.15,0) [0|38.25] "V" Vector__XXX
 SG_ SDCR_a001_expectedPyroV_max m1 : 40|8@1+ (0.02,0) [0|5.1] "V" Vector__XXX
 SG_ SDCR_a001_expectedPyroV_min m1 : 48|8@1+ (0.02,0) [0|5.1] "V" Vector__XXX
 SG_ SDCR_a001_fromState m1 : 56|3@1+ (1,0) [0|7] "" Vector__XXX
 SG_ SDCR_a004_HVBackupSupplyV m4 : 16|8@1+ (0.15,0) [0|38.25] "V" Vector__XXX
 SG_ SDCR_a004_boostRailV m4 : 24|8@1+ (0.15,0) [0|38.25] "V" Vector__XXX
 SG_ SDCR_a004_diPresent m4 : 32|1@1+ (1,0) [0|1] "" Vector__XXX
 SG_ SDCR_a004_pmRunningPin m4 : 33|1@1+ (1,0) [0|1] "" Vector__XXX
 SG_ SDCR_a006_pyroArmed m6 : 16|1@1+ (1,0) [0|1] "" Vector__XXX
 SG_ SDCR_a006_triggerReason_faultCur m6 : 17|1@1+ (1,0) [0|1] "" Vector__XXX
 SG_ SDCR_a006_triggerReason_hvBadAtS m6 : 18|1@1+ (1,0) [0|1] "" Vector__XXX
 SG_ SDCR_a006_triggerReason_highBack m6 : 19|1@1+ (1,0) [0|1] "" Vector__XXX
 SG_ SDCR_a006_faultCurrentsDetected m6 : 20|1@1+ (1,0) [0|1] "" Vector__XXX
 SG_ SDCR_a006_diUartMIA m6 : 21|1@1+ (1,0) [0|1] "" Vector__XXX
 SG_ SDCR_a006_pmRunningPin m6 : 22|1@1+ (1,0) [0|1] "" Vector__XXX
 SG_ SDCR_a006_hvPowerGood m6 : 23|1@1+ (1,0) [0|1] "" Vector__XXX
 SG_ SDCR_a006_hvbkupPGoodPin m6 : 24|1@1+ (1,0) [0|1] "" Vector__XXX
 SG_ SDCR_a006_hvPowerNotGoodQualifie m6 : 25|1@1+ (1,0) [0|1] "" Vector__XXX
 SG_ SDCR_a006_speedValid m6 : 26|1@1+ (1,0) [0|1] "" Vector__XXX
 SG_ SDCR_a006_speedFromVoltage m6 : 27|1@1+ (1,0) [0|1] "" Vector__XXX
 SG_ SDCR_a006_HVBackupSupplyV m6 : 28|7@1+ (0.3,0) [0|38.1] "V" Vector__XXX
 SG_ SDCR_a006_boostRailV m6 : 35|7@1+ (0.3,0) [0|38.1] "V" Vector__XXX
 SG_ SDCR_a006_maxAbsSpeed m6 : 42|12@1- (1,0) [-2048|2047] "Hz" Vector__XXX
 SG_ SDCR_a006_vBat m6 : 54|7@1+ (8,0) [0|1016] "V" Vector__XXX
 SG_ SDCR_a007_faultReason_faultCurre m7 : 16|1@1+ (1,0) [0|1] "" Vector__XXX
 SG_ SDCR_a007_faultReason_unmitigate m7 : 17|1@1+ (1,0) [0|1] "" Vector__XXX
 SG_ SDCR_a007_faultReason_propagatin m7 : 18|1@1+ (1,0) [0|1] "" Vector__XXX
 SG_ SDCR_a007_speedWasValid m7 : 19|1@1+ (1,0) [0|1] "" Vector__XXX
 SG_ SDCR_a007_imbalanceSeen m7 : 20|1@1+ (1,0) [0|1] "" Vector__XXX
 SG_ SDCR_a007_ucrSeen m7 : 21|1@1+ (1,0) [0|1] "" Vector__XXX
 SG_ SDCR_a007_phaseVoltagePresent m7 : 22|1@1+ (1,0) [0|1] "" Vector__XXX
 SG_ SDCR_a007_speedFromVoltage m7 : 23|1@1+ (1,0) [0|1] "" Vector__XXX
 SG_ SDCR_a007_transientHandling m7 : 24|2@1+ (1,0) [0|3] "" Vector__XXX
 SG_ SDCR_a007_maxAbsElcSpeed m7 : 26|9@1+ (4,0) [0|2044] "Hz" Vector__XXX
 SG_ SDCR_a007_avgIa m7 : 35|10@1- (4,0) [-2048|2044] "A" Vector__XXX
 SG_ SDCR_a007_avgIb m7 : 45|10@1- (4,0) [-2048|2044] "A" Vector__XXX
 SG_ SDCR_a007_maxAbsCurrents m7 : 55|9@1+ (4,0) [0|2044] "A" Vector__XXX
 SG_ SDCR_a008_dcLinkInfo m8 : 16|1@1+ (1,0) [0|1] "" Vector__XXX
 SG_ SDCR_a009_diVersion m9 : 16|2@1+ (1,0) [0|3] "" Vector__XXX
 SG_ SDCR_a009_sdcVersion m9 : 18|2@1+ (1,0) [0|3] "" Vector__XXX
 SG_ SDCR_a010_pgood m10 : 16|1@1+ (1,0) [0|1] "" Vector__XXX
 SG_ SDCR_a010_boostRailV m10 : 24|8@1+ (0.15,0) [0|38.25] "V" Vector__XXX
 SG_ SDCR_a010_Vref m10 : 32|8@1+ (0.02,0) [0|5.1] "V" Vector__XXX
 SG_ SDCR_a011_IaAvg m11 : 16|16@1- (0.1,0) [-3276.8|3276.7] "A" Vector__XXX
 SG_ SDCR_a011_IbAvg m11 : 32|16@1- (0.1,0) [-3276.8|3276.7] "A" Vector__XXX
 SG_ SDCR_a012_boostRailV m12 : 16|8@1+ (0.15,0) [0|38.25] "V" Vector__XXX
 SG_ SDCR_a012_HVBackupSupplyV m12 : 24|8@1+ (0.15,0) [0|38.25] "V" Vector__XXX
 SG_ SDCR_a012_vBat m12 : 32|10@1+ (2,0) [0|2046] "V" Vector__XXX
 SG_ SDCR_a012_vbkupGoodFdbk m12 : 42|1@1+ (1,0) [0|1] "" Vector__XXX
 SG_ SDCR_a013_boostRailV m13 : 16|8@1+ (0.15,0) [0|38.25] "V" Vector__XXX
 SG_ SDCR_a013_HVBackupSupplyV m13 : 24|8@1+ (0.15,0) [0|38.25] "V" Vector__XXX
 SG_ SDCR_a013_vBat m13 : 32|10@1+ (2,0) [0|2046] "V" Vector__XXX
 SG_ SDCR_a013_vbkupGoodFdbk m13 : 42|1@1+ (1,0) [0|1] "" Vector__XXX
 SG_ SDCR_a014_reason_vBusShortedLow m14 : 16|1@1+ (1,0) [0|1] "" Vector__XXX
 SG_ SDCR_a014_reason_vBusShortedHigh m14 : 17|1@1+ (1,0) [0|1] "" Vector__XXX
 SG_ SDCR_a014_boostRailV m14 : 24|8@1+ (0.15,0) [0|38.25] "V" Vector__XXX
 SG_ SDCR_a014_HVBackupSupplyV m14 : 32|8@1+ (0.15,0) [0|38.25] "V" Vector__XXX
 SG_ SDCR_a014_vBat m14 : 40|10@1+ (2,0) [0|2046] "V" Vector__XXX
 SG_ SDCR_a014_vbkupGoodFdbk m14 : 50|1@1+ (1,0) [0|1] "" Vector__XXX
 SG_ SDCR_a015_reason_vPhaseShortedLo m15 : 16|1@1+ (1,0) [0|1] "" Vector__XXX
 SG_ SDCR_a015_reason_vPhaseShortedHi m15 : 17|1@1+ (1,0) [0|1] "" Vector__XXX
 SG_ SDCR_a015_diSwitchingPin m15 : 18|1@1+ (1,0) [0|1] "" Vector__XXX
 SG_ SDCR_a015_vBat m15 : 19|10@1+ (2,0) [0|2046] "V" Vector__XXX
 SG_ SDCR_a015_va m15 : 29|10@1+ (2,0) [0|2046] "V" Vector__XXX
 SG_ SDCR_a015_vb m15 : 40|10@1+ (2,0) [0|2046] "V" Vector__XXX
 SG_ SDCR_a015_vc m15 : 50|10@1+ (2,0) [0|2046] "V" Vector__XXX
 SG_ SDCR_a017_expectedConfigWord m17 : 16|16@1+ (1,0) [0|65535] "" Vector__XXX
 SG_ SDCR_a017_receivedConfigWord m17 : 32|16@1+ (1,0) [0|65535] "" Vector__XXX
 SG_ SDCR_a018_pyroArmed m18 : 16|1@1+ (1,0) [0|1] "" Vector__XXX
 SG_ SDCR_a018_triggerReason_faultCur m18 : 17|1@1+ (1,0) [0|1] "" Vector__XXX
 SG_ SDCR_a018_triggerReason_hvBadAtS m18 : 18|1@1+ (1,0) [0|1] "" Vector__XXX
 SG_ SDCR_a018_triggerReason_highBack m18 : 19|1@1+ (1,0) [0|1] "" Vector__XXX
 SG_ SDCR_a018_faultCurrentsDetected m18 : 20|1@1+ (1,0) [0|1] "" Vector__XXX
 SG_ SDCR_a018_diUartMIA m18 : 21|1@1+ (1,0) [0|1] "" Vector__XXX
 SG_ SDCR_a018_pmRunningPin m18 : 22|1@1+ (1,0) [0|1] "" Vector__XXX
 SG_ SDCR_a018_hvPowerGood m18 : 23|1@1+ (1,0) [0|1] "" Vector__XXX
 SG_ SDCR_a018_hvbkupPGoodPin m18 : 24|1@1+ (1,0) [0|1] "" Vector__XXX
 SG_ SDCR_a018_hvPowerNotGoodQualifie m18 : 25|1@1+ (1,0) [0|1] "" Vector__XXX
 SG_ SDCR_a018_speedValid m18 : 26|1@1+ (1,0) [0|1] "" Vector__XXX
 SG_ SDCR_a018_speedFromVoltage m18 : 27|1@1+ (1,0) [0|1] "" Vector__XXX
 SG_ SDCR_a018_HVBackupSupplyV m18 : 28|7@1+ (0.3,0) [0|38.1] "V" Vector__XXX
 SG_ SDCR_a018_boostRailV m18 : 35|7@1+ (0.3,0) [0|38.1] "V" Vector__XXX
 SG_ SDCR_a018_maxAbsSpeed m18 : 42|12@1- (1,0) [-2048|2047] "Hz" Vector__XXX
 SG_ SDCR_a018_vBat m18 : 54|7@1+ (8,0) [0|1016] "V" Vector__XXX
 SG_ SDCR_a019_faultReason_faultCurre m19 : 16|1@1+ (1,0) [0|1] "" Vector__XXX
 SG_ SDCR_a019_faultReason_unmitigate m19 : 17|1@1+ (1,0) [0|1] "" Vector__XXX
 SG_ SDCR_a019_faultReason_propagatin m19 : 18|1@1+ (1,0) [0|1] "" Vector__XXX
 SG_ SDCR_a019_speedWasValid m19 : 19|1@1+ (1,0) [0|1] "" Vector__XXX
 SG_ SDCR_a019_imbalanceSeen m19 : 20|1@1+ (1,0) [0|1] "" Vector__XXX
 SG_ SDCR_a019_ucrSeen m19 : 21|1@1+ (1,0) [0|1] "" Vector__XXX
 SG_ SDCR_a019_phaseVoltagePresent m19 : 22|1@1+ (1,0) [0|1] "" Vector__XXX
 SG_ SDCR_a019_speedFromVoltage m19 : 23|1@1+ (1,0) [0|1] "" Vector__XXX
 SG_ SDCR_a019_transientHandling m19 : 24|2@1+ (1,0) [0|3] "" Vector__XXX
 SG_ SDCR_a019_maxAbsElcSpeed m19 : 26|9@1+ (4,0) [0|2044] "Hz" Vector__XXX
 SG_ SDCR_a019_avgIa m19 : 35|10@1- (4,0) [-2048|2044] "A" Vector__XXX
 SG_ SDCR_a019_avgIb m19 : 45|10@1- (4,0) [-2048|2044] "A" Vector__XXX
 SG_ SDCR_a019_maxAbsCurrents m19 : 55|9@1+ (4,0) [0|2044] "A" Vector__XXX
 SG_ SDCR_a020_errorCode m20 : 16|8@1+ (1,0) [0|255] "" Vector__XXX
 SG_ SDCR_a020_rxData0 m20 : 24|8@1+ (1,0) [0|255] "" Vector__XXX
 SG_ SDCR_a020_rxData1 m20 : 32|8@1+ (1,0) [0|255] "" Vector__XXX
 SG_ SDCR_a020_rxData2 m20 : 40|8@1+ (1,0) [0|255] "" Vector__XXX
 SG_ SDCR_a020_rxData3 m20 : 48|8@1+ (1,0) [0|255] "" Vector__XXX
 SG_ SDCR_a020_rxData4 m20 : 56|8@1+ (1,0) [0|255] "" Vector__XXX
 SG_ SDCR_a021_busBarTempC m21 : 16|8@1+ (1,-40) [-39|215] "DegC" Vector__XXX
 SG_ SDCR_a021_busBarTempA m21 : 24|8@1+ (1,-40) [-39|215] "DegC" Vector__XXX
 SG_ SDCR_a021_tempCVoltage m21 : 32|8@1+ (0.02,0) [0|5.1] "V" Vector__XXX
 SG_ SDCR_a021_tempAVoltage m21 : 40|8@1+ (0.02,0) [0|5.1] "V" Vector__XXX
 SG_ SDCR_a024_time m24 : 16|1@1+ (1,0) [0|1] "" Vector__XXX
 SG_ SDCR_a025_diSwitchingFromUart m25 : 16|1@1+ (1,0) [0|1] "" Vector__XXX
 SG_ SDCR_a025_diSwitchingPin m25 : 17|1@1+ (1,0) [0|1] "" Vector__XXX
 SG_ SDCR_a025_pmRunningPin m25 : 18|1@1+ (1,0) [0|1] "" Vector__XXX
 SG_ SDCR_a025_diUartMIA m25 : 19|1@1+ (1,0) [0|1] "" Vector__XXX
 SG_ SDCR_a025_HVBackupSupplyV m25 : 24|8@1+ (0.15,0) [0|38.25] "V" Vector__XXX
 SG_ SDCR_a025_boostRailV m25 : 32|8@1+ (0.15,0) [0|38.25] "V" Vector__XXX
 SG_ SDCR_a028_LVPowerState m28 : 16|1@1+ (1,0) [0|1] "" Vector__XXX
 SG_ SDCR_a029_uartCommsMissing m29 : 16|1@1+ (1,0) [0|1] "" Vector__XXX
 SG_ SDCR_a029_canCommsMissing m29 : 17|1@1+ (1,0) [0|1] "" Vector__XXX
 SG_ SDCR_a029_lvState m29 : 18|2@1+ (1,0) [0|3] "" Vector__XXX
 SG_ SDCR_a034_Ia m34 : 16|16@1- (0.1,0) [-3276.8|3276.7] "A" Vector__XXX
 SG_ SDCR_a034_Ib m34 : 32|16@1- (0.1,0) [-3276.8|3276.7] "A" Vector__XXX

BO_ 1467 SDCR_alertMatrix: 8 SDCR
 SG_ SDCR_matrixIndex M : 0|4@1+ (1,0) [0|15] "" Vector__XXX
 SG_ SDCR_a001_powerOnSelfTestFailed m0 : 4|1@1+ (1,0) [0|1] "" Vector__XXX
 SG_ SDCR_a002_diPstSkipped m0 : 5|1@1+ (1,0) [0|1] "" Vector__XXX
 SG_ SDCR_a003_diUartMIA m0 : 6|1@1+ (1,0) [0|1] "" Vector__XXX
 SG_ SDCR_a004_pmRunningFdbkIrrationa m0 : 7|1@1+ (1,0) [0|1] "" Vector__XXX
 SG_ SDCR_a005_motorSpeedIrrational m0 : 8|1@1+ (1,0) [0|1] "" Vector__XXX
 SG_ SDCR_a006_pyroTriggered m0 : 9|1@1+ (1,0) [0|1] "" Vector__XXX
 SG_ SDCR_a007_faultCurrentsDetected m0 : 10|1@1+ (1,0) [0|1] "" Vector__XXX
 SG_ SDCR_a008_hvlinkMIA m0 : 11|1@1+ (1,0) [0|1] "" Vector__XXX
 SG_ SDCR_a009_uartVersionMismatch m0 : 12|1@1+ (1,0) [0|1] "" Vector__XXX
 SG_ SDCR_a010_vrefIrrational m0 : 13|1@1+ (1,0) [0|1] "" Vector__XXX
 SG_ SDCR_a011_phaseCurrentOffset m0 : 14|1@1+ (1,0) [0|1] "" Vector__XXX
 SG_ SDCR_a012_vBoostSecIrrational m0 : 15|1@1+ (1,0) [0|1] "" Vector__XXX
 SG_ SDCR_a013_vBkupIrrational m0 : 16|1@1+ (1,0) [0|1] "" Vector__XXX
 SG_ SDCR_a014_vBusIrrational m0 : 17|1@1+ (1,0) [0|1] "" Vector__XXX
 SG_ SDCR_a015_phaseVIrrational m0 : 18|1@1+ (1,0) [0|1] "" Vector__XXX
 SG_ SDCR_a016_systemReset m0 : 19|1@1+ (1,0) [0|1] "" Vector__XXX
 SG_ SDCR_a017_adcSPIError m0 : 20|1@1+ (1,0) [0|1] "" Vector__XXX
 SG_ SDCR_a018_historicalPyroTrigger m0 : 21|1@1+ (1,0) [0|1] "" Vector__XXX
 SG_ SDCR_a019_historicalFaultCurrent m0 : 22|1@1+ (1,0) [0|1] "" Vector__XXX
 SG_ SDCR_a020_eepromSPIError m0 : 23|1@1+ (1,0) [0|1] "" Vector__XXX
 SG_ SDCR_a021_busBarTempIrrational m0 : 24|1@1+ (1,0) [0|1] "" Vector__XXX
 SG_ SDCR_a022_TaskInitError m0 : 25|1@1+ (1,0) [0|1] "" Vector__XXX
 SG_ SDCR_a023_ecuLogAvailable m0 : 26|1@1+ (1,0) [0|1] "" Vector__XXX
 SG_ SDCR_a024_gtwMIA m0 : 27|1@1+ (1,0) [0|1] "" Vector__XXX
 SG_ SDCR_a025_diSwitchingFdbkIrratio m0 : 28|1@1+ (1,0) [0|1] "" Vector__XXX
 SG_ SDCR_a026_faultCurrentMonitoring m0 : 29|1@1+ (1,0) [0|1] "" Vector__XXX
 SG_ SDCR_a027_diCanMIA m0 : 30|1@1+ (1,0) [0|1] "" Vector__XXX
 SG_ SDCR_a028_vcLVStateMIA m0 : 31|1@1+ (1,0) [0|1] "" Vector__XXX
 SG_ SDCR_a029_diMIA m0 : 32|1@1+ (1,0) [0|1] "" Vector__XXX
 SG_ SDCR_a030_placeholder30 m0 : 33|1@1+ (1,0) [0|1] "" Vector__XXX
 SG_ SDCR_a031_placeholder31 m0 : 34|1@1+ (1,0) [0|1] "" Vector__XXX
 SG_ SDCR_a032_placeholder32 m0 : 35|1@1+ (1,0) [0|1] "" Vector__XXX
 SG_ SDCR_a033_placeholder33 m0 : 36|1@1+ (1,0) [0|1] "" Vector__XXX
 SG_ SDCR_a034_phaseCurrentIrrational m0 : 37|1@1+ (1,0) [0|1] "" Vector__XXX

BO_ 1597 SDCR_info: 8 SDCR
 SG_ SDCR_infoIndex M : 0|8@1+ (1,0) [0|255] "" Vector__XXX
 SG_ SDCR_infoBuildType m10 : 13|3@1+ (1,0) [0|7] "" Vector__XXX
 SG_ SDCR_infoBuildConfigId m10 : 16|16@1+ (1,0) [0|65535] "" Vector__XXX
 SG_ SDCR_infoHardwareId m10 : 32|16@1+ (1,0) [0|65535] "" Vector__XXX
 SG_ SDCR_infoComponentId m10 : 55|16@0+ (1,0) [0|65535] "" Vector__XXX
 SG_ SDCR_infoPcbaId m11 : 8|8@1+ (1,0) [0|255] "" Vector__XXX
 SG_ SDCR_infoAssemblyId m11 : 16|8@1+ (1,0) [0|255] "" Vector__XXX
 SG_ SDCR_infoUsageId m11 : 31|16@0+ (1,0) [0|65535] "" Vector__XXX
 SG_ SDCR_infoSubUsageId m11 : 40|16@1+ (1,0) [0|65535] "" Vector__XXX
 SG_ SDCR_infoAppCrc m13 : 15|32@0+ (1,0) [0|4294967295] "" Vector__XXX
 SG_ SDCR_infoBootGitHash m18 : 8|56@1+ (1,0) [0|7.20575940379e+16] "" Vector__XXX

BO_TX_BU_ 1444 : PM;
BO_TX_BU_ 1551 : PM;
BO_TX_BU_ 1766 : GTW;
BO_TX_BU_ 837 : PTC;
BO_TX_BU_ 647 : PTC;
BO_TX_BU_ 1344 : SCCM;
BO_TX_BU_ 1359 : SCCM;
BO_TX_BU_ 816 : SCCM;
BO_TX_BU_ 585 : SCCM;
BO_TX_BU_ 553 : SCCM;
BO_TX_BU_ 297 : SCCM;
BO_TX_BU_ 1356 : SCM;
BO_TX_BU_ 815 : SCM;
BO_TX_BU_ 1355 : SCM;
BO_TX_BU_ 1354 : SCS;
BO_TX_BU_ 869 : SCS;
BO_TX_BU_ 880 : SCS;
BO_TX_BU_ 1531 : SDCR;
BO_TX_BU_ 1467 : SDCR;
BO_TX_BU_ 1597 : SDCR;
CM_ BO_ 1444 "PM ECU message: alert log";
CM_ SG_ 1444 PM_alertID "PM ECU: alert ID";
CM_ SG_ 1444 PM_alertState "PM ECU: alert state";
CM_ SG_ 1444 PM_a001_w0 "PM ECU: a001 w0";
CM_ SG_ 1444 PM_a001_w1 "PM ECU: a001 w1";
CM_ SG_ 1444 PM_a001_w2 "PM ECU: a001 w2";
CM_ SG_ 1444 PM_a002_torqueAverage "PM ECU: a002 torque average";
CM_ SG_ 1444 PM_a002_torqueWindow "PM ECU: a002 torque window";
CM_ SG_ 1444 PM_a002_torqueMeasured "PM ECU: a002 torque measured; raw 4096 = signal not available (SNA)";
CM_ SG_ 1444 PM_a002_torqueAccelAverage "PM ECU: a002 torque accel average; raw 4096 = signal not available (SNA)";
CM_ SG_ 1444 PM_a002_torqueAccelWindow "PM ECU: a002 torque accel window; raw 4096 = signal not available (SNA)";
CM_ SG_ 1444 PM_a003_reverseGear "PM ECU: a003 reverse gear";
CM_ SG_ 1444 PM_a003_pedalPos "PM ECU: a003 pedal pos";
CM_ SG_ 1444 PM_a003_zeroPointPedal "PM ECU: a003 zero point pedal";
CM_ SG_ 1444 PM_a004_torqueAverage "PM ECU: a004 torque average";
CM_ SG_ 1444 PM_a004_torqueWindow "PM ECU: a004 torque window";
CM_ SG_ 1444 PM_a004_torqueMeasured "PM ECU: a004 torque measured; raw 4096 = signal not available (SNA)";
CM_ SG_ 1444 PM_a004_torqueDecelAverage "PM ECU: a004 torque decel average; raw 4096 = signal not available (SNA)";
CM_ SG_ 1444 PM_a004_torqueDecelWindow "PM ECU: a004 torque decel window; raw 4096 = signal not available (SNA)";
CM_ SG_ 1444 PM_a005_torqueReason "PM ECU: a005 torque reason";
CM_ SG_ 1444 PM_a005_torqueMeasured "PM ECU: a005 torque measured; raw 4096 = signal not available (SNA)";
CM_ SG_ 1444 PM_a005_iDQmagnitude "PM ECU: a005 i d qmagnitude";
CM_ SG_ 1444 PM_a006_unknownGearAllowed "PM ECU: a006 unknown gear allowed";
CM_ SG_ 1444 PM_a006_parkGearAllowed "PM ECU: a006 park gear allowed";
CM_ SG_ 1444 PM_a006_reverseGearAllowed "PM ECU: a006 reverse gear allowed";
CM_ SG_ 1444 PM_a006_neutralGearAllowed "PM ECU: a006 neutral gear allowed";
CM_ SG_ 1444 PM_a006_driveGearAllowed "PM ECU: a006 drive gear allowed";
CM_ SG_ 1444 PM_a006_shiftState "PM ECU: a006 shift state; raw 7 = signal not available (SNA)";
CM_ SG_ 1444 PM_a006_brakePedalPress "PM ECU: a006 brake pedal press";
CM_ SG_ 1444 PM_a006_accelPedalBelowLimit "PM ECU: a006 accel pedal below limit";
CM_ SG_ 1444 PM_a006_allowReverseShiftSpeed "PM ECU: a006 allow reverse shift speed";
CM_ SG_ 1444 PM_a006_allowDriveShiftSpeed "PM ECU: a006 allow drive shift speed";
CM_ SG_ 1444 PM_a006_requireAccelPedalCheckSp "PM ECU: a006 require accel pedal check speed";
CM_ SG_ 1444 PM_a006_requireParkSpeed "PM ECU: a006 require park speed";
CM_ SG_ 1444 PM_a006_stalkCommandP "PM ECU: a006 stalk command p";
CM_ SG_ 1444 PM_a006_stalkCommandR "PM ECU: a006 stalk command r";
CM_ SG_ 1444 PM_a006_stalkCommandN "PM ECU: a006 stalk command n";
CM_ SG_ 1444 PM_a006_stalkCommandD "PM ECU: a006 stalk command d";
CM_ SG_ 1444 PM_a006_unsecuredNeutralRequest "PM ECU: a006 unsecured neutral request";
CM_ SG_ 1444 PM_a006_recentGearChange "PM ECU: a006 recent gear change";
CM_ SG_ 1444 PM_a006_smartShiftCommandD "PM ECU: a006 smart shift command d";
CM_ SG_ 1444 PM_a006_smartShiftCommandR "PM ECU: a006 smart shift command r";
CM_ SG_ 1444 PM_a006_driverSeatbeltBuckled "PM ECU: a006 driver seatbelt buckled";
CM_ SG_ 1444 PM_a006_secGearSelRisingEdgeR "PM ECU: a006 sec gear sel rising edge r";
CM_ SG_ 1444 PM_a006_secGearSelRisingEdgeN "PM ECU: a006 sec gear sel rising edge n";
CM_ SG_ 1444 PM_a006_secGearSelRisingEdgeD "PM ECU: a006 sec gear sel rising edge d";
CM_ SG_ 1444 PM_a007_IBST_party1 "PM ECU: a007 IBST party1";
CM_ SG_ 1444 PM_a007_BUS1_IBST_status "PM ECU: a007 BUS1 IBST status";
CM_ SG_ 1444 PM_a007_BUS2_IBST_status "PM ECU: a007 BUS2 IBST status";
CM_ SG_ 1444 PM_a009_ESP_brakeTorque "PM ECU: a009 ESP brake torque";
CM_ SG_ 1444 PM_a009_ESP_motorLimits "PM ECU: a009 ESP motor limits";
CM_ SG_ 1444 PM_a009_ESP_offsets "PM ECU: a009 ESP offsets";
CM_ SG_ 1444 PM_a009_ESP_party3 "PM ECU: a009 ESP party3";
CM_ SG_ 1444 PM_a009_ESP_status "PM ECU: a009 ESP status";
CM_ SG_ 1444 PM_a009_ESP_wheelSpeeds "PM ECU: a009 ESP wheel speeds";
CM_ SG_ 1444 PM_a010_messageId "PM ECU: a010 message id";
CM_ SG_ 1444 PM_a010_DI_status "PM ECU: a010 DI status";
CM_ SG_ 1444 PM_a010_DI_torque "PM ECU: a010 DI torque";
CM_ SG_ 1444 PM_a010_DI_slaveCommand "PM ECU: a010 DI slave command";
CM_ SG_ 1444 PM_a010_DI_locStatus "PM ECU: a010 DI loc status";
CM_ SG_ 1444 PM_a010_DI_speed "PM ECU: a010 DI speed";
CM_ SG_ 1444 PM_a010_DI_systemStatus "PM ECU: a010 DI system status";
CM_ SG_ 1444 PM_a010_DI_chassisControl "PM ECU: a010 DI chassis control";
CM_ SG_ 1444 PM_a010_DI_chassisControl2 "PM ECU: a010 DI chassis control2";
CM_ SG_ 1444 PM_a010_vdcLeft "PM ECU: a010 vdc left";
CM_ SG_ 1444 PM_a010_vdcRight "PM ECU: a010 vdc right";
CM_ SG_ 1444 PM_a010_DI_vehicleEstimates "PM ECU: a010 DI vehicle estimates";
CM_ SG_ 1444 PM_a010_DI_brakeCommand "PM ECU: a010 DI brake command";
CM_ SG_ 1444 PM_a010_DI_difCommand "PM ECU: a010 DI dif command";
CM_ SG_ 1444 PM_a010_DI_dirCommand "PM ECU: a010 DI dir command";
CM_ SG_ 1444 PM_a010_DI_dirVehicle "PM ECU: a010 DI dir vehicle";
CM_ SG_ 1444 PM_a010_DI_locStatus2 "PM ECU: a010 DI loc status2";
CM_ SG_ 1444 PM_a010_stalklessInterfaces "PM ECU: a010 stalkless interfaces";
CM_ SG_ 1444 PM_a011_pmfHvilStatus "PM ECU: a011 pmf hvil status; raw 3 = signal not available (SNA)";
CM_ SG_ 1444 PM_a011_pmfStatusValid "PM ECU: a011 pmf status valid";
CM_ SG_ 1444 PM_a011_pmrHvilStatus "PM ECU: a011 pmr hvil status; raw 3 = signal not available (SNA)";
CM_ SG_ 1444 PM_a011_pmrStatusValid "PM ECU: a011 pmr status valid";
CM_ SG_ 1444 PM_a011_vehiclePowerState "PM ECU: a011 vehicle power state";
CM_ SG_ 1444 PM_a011_hvilSystemStatus "PM ECU: a011 hvil system status; raw 3 = signal not available (SNA)";
CM_ SG_ 1444 PM_a012_canID "PM ECU: a012 can ID";
CM_ SG_ 1444 PM_a012_errorType "PM ECU: a012 error type";
CM_ SG_ 1444 PM_a012_badValue1 "PM ECU: a012 bad value1";
CM_ SG_ 1444 PM_a012_badValue2 "PM ECU: a012 bad value2";
CM_ SG_ 1444 PM_a013_mailboxID "PM ECU: a013 mailbox ID";
CM_ SG_ 1444 PM_a013_canID "PM ECU: a013 can ID";
CM_ SG_ 1444 PM_a013_errorType "PM ECU: a013 error type";
CM_ SG_ 1444 PM_a014_track1Voltage "PM ECU: a014 track1 voltage";
CM_ SG_ 1444 PM_a014_track2Voltage "PM ECU: a014 track2 voltage";
CM_ SG_ 1444 PM_a014_accelErrorType "PM ECU: a014 accel error type; raw 0 = signal not available (SNA)";
CM_ SG_ 1444 PM_a015_SCCM_rightStalk "PM ECU: a015 SCCM right stalk";
CM_ SG_ 1444 PM_a016_BB_status "PM ECU: a016 BB status";
CM_ SG_ 1444 PM_a016_BB_brakeActuation "PM ECU: a016 BB brake actuation";
CM_ SG_ 1444 PM_a017_EPBL_status "PM ECU: a017 EPBL status";
CM_ SG_ 1444 PM_a017_EPBR_status "PM ECU: a017 EPBR status";
CM_ SG_ 1444 PM_a021_torque "PM ECU: a021 torque";
CM_ SG_ 1444 PM_a021_capability "PM ECU: a021 capability";
CM_ SG_ 1444 PM_a021_status "PM ECU: a021 status";
CM_ SG_ 1444 PM_a021_capability2 "PM ECU: a021 capability2";
CM_ SG_ 1444 PM_a021_power "PM ECU: a021 power";
CM_ SG_ 1444 PM_a022_torque "PM ECU: a022 torque";
CM_ SG_ 1444 PM_a022_capability "PM ECU: a022 capability";
CM_ SG_ 1444 PM_a022_status "PM ECU: a022 status";
CM_ SG_ 1444 PM_a022_capability2 "PM ECU: a022 capability2";
CM_ SG_ 1444 PM_a022_power "PM ECU: a022 power";
CM_ SG_ 1444 PM_a023_diCrsState "PM ECU: a023 di crs state";
CM_ SG_ 1444 PM_a023_pmCrsState "PM ECU: a023 pm crs state";
CM_ SG_ 1444 PM_a023_crsFaultReason "PM ECU: a023 crs fault reason";
CM_ SG_ 1444 PM_a023_crsCancelReason "PM ECU: a023 crs cancel reason";
CM_ SG_ 1444 PM_a023_cruiseTorquePed "PM ECU: a023 cruise torque ped";
CM_ SG_ 1444 PM_a023_wheelSpdEstimateAbs "PM ECU: a023 wheel spd estimate abs";
CM_ SG_ 1444 PM_a023_accelEstimateDis "PM ECU: a023 accel estimate dis";
CM_ SG_ 1444 PM_a025_powerOnReset "PM ECU: a025 power on reset";
CM_ SG_ 1444 PM_a025_watchdogTimer0 "PM ECU: a025 watchdog timer0";
CM_ SG_ 1444 PM_a025_watchdogTimer1 "PM ECU: a025 watchdog timer1";
CM_ SG_ 1444 PM_a025_watchdogTimer2 "PM ECU: a025 watchdog timer2";
CM_ SG_ 1444 PM_a025_watchdogTimer3 "PM ECU: a025 watchdog timer3";
CM_ SG_ 1444 PM_a025_warmResetReq "PM ECU: a025 warm reset req";
CM_ SG_ 1444 PM_a025_externalPadReset "PM ECU: a025 external pad reset";
CM_ SG_ 1444 PM_a025_hwSecModuleWatchdogTimer "PM ECU: a025 hw sec module watchdog timer";
CM_ SG_ 1444 PM_a025_debugReset "PM ECU: a025 debug reset";
CM_ SG_ 1444 PM_a025_tempSense0 "PM ECU: a025 temp sense0";
CM_ SG_ 1444 PM_a025_tempSense1 "PM ECU: a025 temp sense1";
CM_ SG_ 1444 PM_a026_reason "PM ECU: a026 reason";
CM_ SG_ 1444 PM_a026_isrCount20kHz "PM ECU: a026 isr count20k hz";
CM_ SG_ 1444 PM_a026_isrCount1kHz "PM ECU: a026 isr count1k hz";
CM_ SG_ 1444 PM_a026_switchingActive "PM ECU: a026 switching active";
CM_ SG_ 1444 PM_a026_systemStackOvf "PM ECU: a026 system stack ovf";
CM_ SG_ 1444 PM_a026_controlStackOvf "PM ECU: a026 control stack ovf";
CM_ SG_ 1444 PM_a026_idleStackOvf "PM ECU: a026 idle stack ovf";
CM_ SG_ 1444 PM_a026_eepStackOvf "PM ECU: a026 eep stack ovf";
CM_ SG_ 1444 PM_a026_immStackOvf "PM ECU: a026 imm stack ovf";
CM_ SG_ 1444 PM_a026_xdcErrorIdMSW "PM ECU: a026 xdc error id MSW";
CM_ SG_ 1444 PM_a026_xdcErrorArg1 "PM ECU: a026 xdc error arg1";
CM_ SG_ 1444 PM_a030_diAebState "PM ECU: a030 di aeb state; raw 7 = signal not available (SNA)";
CM_ SG_ 1444 PM_a030_pmAebState "PM ECU: a030 pm aeb state; raw 7 = signal not available (SNA)";
CM_ SG_ 1444 PM_a030_dasAebEvent "PM ECU: a030 das aeb event; raw 3 = signal not available (SNA)";
CM_ SG_ 1444 PM_a030_aebFaultReason "PM ECU: a030 aeb fault reason";
CM_ SG_ 1444 PM_a030_aebUnavailableReason "PM ECU: a030 aeb unavailable reason";
CM_ SG_ 1444 PM_a030_aebCancelReason "PM ECU: a030 aeb cancel reason";
CM_ SG_ 1444 PM_a030_diBrakeTorqueCommand "PM ECU: a030 di brake torque command";
CM_ SG_ 1444 PM_a032_w0 "PM ECU: a032 w0";
CM_ SG_ 1444 PM_a032_w1 "PM ECU: a032 w1";
CM_ SG_ 1444 PM_a032_w2 "PM ECU: a032 w2";
CM_ SG_ 1444 PM_a036_timeSinceTxHWI "PM ECU: a036 time since tx HWI";
CM_ SG_ 1444 PM_a036_timeSinceRxHWI "PM ECU: a036 time since rx HWI";
CM_ SG_ 1444 PM_a036_timeSince100HzTxSWI "PM ECU: a036 time since100 hz tx SWI";
CM_ SG_ 1444 PM_a036_timeSince1kHzCLK "PM ECU: a036 time since1k hz CLK";
CM_ SG_ 1444 PM_a036_timeSince1kHzSWI "PM ECU: a036 time since1k hz SWI";
CM_ SG_ 1444 PM_a036_timeSinceIdle "PM ECU: a036 time since idle";
CM_ SG_ 1444 PM_a036_ovfStackId "PM ECU: a036 ovf stack id; raw 15 = signal not available (SNA)";
CM_ SG_ 1444 PM_a036_inTxISR "PM ECU: a036 in tx ISR";
CM_ SG_ 1444 PM_a036_inTxHWI "PM ECU: a036 in tx HWI";
CM_ SG_ 1444 PM_a036_inRxHWI "PM ECU: a036 in rx HWI";
CM_ SG_ 1444 PM_a036_in1kHzSWI "PM ECU: a036 in1k hz SWI";
CM_ SG_ 1444 PM_a036_in1kHzCLK "PM ECU: a036 in1k hz CLK";
CM_ SG_ 1444 PM_a036_in100HzCLK "PM ECU: a036 in100 hz CLK";
CM_ SG_ 1444 PM_a036_in10HzCLK "PM ECU: a036 in10 hz CLK";
CM_ SG_ 1444 PM_a036_in1HzCLK "PM ECU: a036 in1 hz CLK";
CM_ SG_ 1444 PM_a038_masterTorque "PM ECU: a038 master torque";
CM_ SG_ 1444 PM_a038_slaveTorque "PM ECU: a038 slave torque";
CM_ SG_ 1444 PM_a038_pedalPos "PM ECU: a038 pedal pos";
CM_ SG_ 1444 PM_a039_DIS_status "PM ECU: a039 DIS status";
CM_ SG_ 1444 PM_a039_DIS_torque "PM ECU: a039 DIS torque";
CM_ SG_ 1444 PM_a039_messageId "PM ECU: a039 message id";
CM_ SG_ 1444 PM_a041_DAS_control "PM ECU: a041 DAS control";
CM_ SG_ 1444 PM_a041_DAS_longControl "PM ECU: a041 DAS long control";
CM_ SG_ 1444 PM_a041_DAS_longControlTuningPar "PM ECU: a041 DAS long control tuning parameters";
CM_ SG_ 1444 PM_a041_DAS_status "PM ECU: a041 DAS status";
CM_ SG_ 1444 PM_a041_DAS_status2 "PM ECU: a041 DAS status2";
CM_ SG_ 1444 PM_a041_DAS_smartShift "PM ECU: a041 DAS smart shift";
CM_ SG_ 1444 PM_a042_GTW_carConfig "PM ECU: a042 GTW car config";
CM_ SG_ 1444 PM_a042_GTW_time "PM ECU: a042 GTW time";
CM_ SG_ 1444 PM_a042_GTW_drivetrainType "PM ECU: a042 GTW drivetrain type";
CM_ SG_ 1444 PM_a042_expectedPerformanceCfg "PM ECU: a042 expected performance cfg";
CM_ SG_ 1444 PM_a042_gearControl "PM ECU: a042 gear control";
CM_ SG_ 1444 PM_a043_configInconsistent "PM ECU: a043 config inconsistent";
CM_ SG_ 1444 PM_a043_GTW_autopilot "PM ECU: a043 GTW autopilot";
CM_ SG_ 1444 PM_a043_expectedAutopilot "PM ECU: a043 expected autopilot";
CM_ SG_ 1444 PM_a043_GTW_drivetrainType "PM ECU: a043 GTW drivetrain type";
CM_ SG_ 1444 PM_a043_expectedDrivetrainType "PM ECU: a043 expected drivetrain type";
CM_ SG_ 1444 PM_a043_GTW_chassisType "PM ECU: a043 GTW chassis type";
CM_ SG_ 1444 PM_a043_expectedChassisType "PM ECU: a043 expected chassis type";
CM_ SG_ 1444 PM_a043_packEnergy "PM ECU: a043 pack energy";
CM_ SG_ 1444 PM_a043_packPerformanceDeviation "PM ECU: a043 pack performance deviation";
CM_ SG_ 1444 PM_a043_performancePackage "PM ECU: a043 performance package";
CM_ SG_ 1444 PM_a043_GTW_vdcType "PM ECU: a043 GTW vdc type";
CM_ SG_ 1444 PM_a043_expectedVdcType "PM ECU: a043 expected vdc type";
CM_ SG_ 1444 PM_a043_brakeHWType "PM ECU: a043 brake HW type";
CM_ SG_ 1444 PM_a043_cabinPTCHeaterType "PM ECU: a043 cabin PTC heater type";
CM_ SG_ 1444 PM_a043_softPerformanceLimit "PM ECU: a043 soft performance limit";
CM_ SG_ 1444 PM_a043_GTW_dasHw "PM ECU: a043 GTW das hw";
CM_ SG_ 1444 PM_a044_pmCruiseState "PM ECU: a044 pm cruise state";
CM_ SG_ 1444 PM_a044_diCruiseState "PM ECU: a044 di cruise state";
CM_ SG_ 1444 PM_a044_pmAebState "PM ECU: a044 pm aeb state; raw 7 = signal not available (SNA)";
CM_ SG_ 1444 PM_a044_diAebState "PM ECU: a044 di aeb state; raw 7 = signal not available (SNA)";
CM_ SG_ 1444 PM_a044_diBrakeTorqueCommand "PM ECU: a044 di brake torque command";
CM_ SG_ 1444 PM_a044_pmBfillTorqueAllowed "PM ECU: a044 pm bfill torque allowed";
CM_ SG_ 1444 PM_a044_pmVehicleHoldState "PM ECU: a044 pm vehicle hold state";
CM_ SG_ 1444 PM_a044_diVehicleHoldState "PM ECU: a044 di vehicle hold state";
CM_ SG_ 1444 PM_a044_regenBackfillPmState "PM ECU: a044 regen backfill pm state";
CM_ SG_ 1444 PM_a045_regenBackfillPmState "PM ECU: a045 regen backfill pm state";
CM_ SG_ 1444 PM_a045_regenBackfillDiState "PM ECU: a045 regen backfill di state";
CM_ SG_ 1444 PM_a045_unavailableReason "PM ECU: a045 unavailable reason";
CM_ SG_ 1444 PM_a045_diBrakeTorqueCommand "PM ECU: a045 di brake torque command";
CM_ SG_ 1444 PM_a045_pmBrakeTorqueAllowed "PM ECU: a045 pm brake torque allowed";
CM_ SG_ 1444 PM_a046_diVhldState "PM ECU: a046 di vhld state";
CM_ SG_ 1444 PM_a046_pmVhldState "PM ECU: a046 pm vhld state";
CM_ SG_ 1444 PM_a046_vhldFaultReason "PM ECU: a046 vhld fault reason";
CM_ SG_ 1444 PM_a046_vhldUnavailableReason "PM ECU: a046 vhld unavailable reason";
CM_ SG_ 1444 PM_a046_diBrakeTorqueCommand "PM ECU: a046 di brake torque command";
CM_ SG_ 1444 PM_a046_diBrakeCommandType "PM ECU: a046 di brake command type";
CM_ SG_ 1444 PM_a047_pmAutoparkState "PM ECU: a047 pm autopark state; raw 15 = signal not available (SNA)";
CM_ SG_ 1444 PM_a047_diAutoparkState "PM ECU: a047 di autopark state; raw 15 = signal not available (SNA)";
CM_ SG_ 1444 PM_a047_autoparkCancelReason "PM ECU: a047 autopark cancel reason";
CM_ SG_ 1444 PM_a048_vdcFaultReason "PM ECU: a048 vdc fault reason";
CM_ SG_ 1444 PM_a053_LVPowerState "PM ECU: a053 LV power state";
CM_ SG_ 1444 PM_a053_coolant "PM ECU: a053 coolant";
CM_ SG_ 1444 PM_a053_vcleftSwitchStatus "PM ECU: a053 vcleft switch status";
CM_ SG_ 1444 PM_a053_restraintStatus "PM ECU: a053 restraint status";
CM_ SG_ 1444 PM_a053_sensors "PM ECU: a053 sensors";
CM_ SG_ 1444 PM_a054_uiPowertrainControl "PM ECU: a054 ui powertrain control";
CM_ SG_ 1444 PM_a054_uiChassisControl "PM ECU: a054 ui chassis control";
CM_ SG_ 1444 PM_a054_uiCruiseControl "PM ECU: a054 ui cruise control";
CM_ SG_ 1444 PM_a054_uiTrackModeSettings "PM ECU: a054 ui track mode settings";
CM_ SG_ 1444 PM_a054_uiTPMSRCPSetting "PM ECU: a054 ui TPMSRCP setting";
CM_ SG_ 1444 PM_a056_mailboxID "PM ECU: a056 mailbox ID";
CM_ SG_ 1444 PM_a056_canID "PM ECU: a056 can ID";
CM_ SG_ 1444 PM_a056_errorType "PM ECU: a056 error type";
CM_ SG_ 1444 PM_a057_canID "PM ECU: a057 can ID";
CM_ SG_ 1444 PM_a057_errorType "PM ECU: a057 error type";
CM_ SG_ 1444 PM_a057_badValue1 "PM ECU: a057 bad value1";
CM_ SG_ 1444 PM_a057_badValue2 "PM ECU: a057 bad value2";
CM_ SG_ 1444 PM_a058_CMP_HVStatus "PM ECU: a058 CMP HV status";
CM_ SG_ 1444 PM_a058_CMPD_state "PM ECU: a058 CMPD state";
CM_ SG_ 1444 PM_a059_PTC_feedbackStatus "PM ECU: a059 PTC feedback status";
CM_ SG_ 1444 PM_a060_TorqueAccelWindow "PM ECU: a060 torque accel window";
CM_ SG_ 1444 PM_a060_TorqueDecelWindow "PM ECU: a060 torque decel window";
CM_ SG_ 1444 PM_a060_TorqueReversalWindow "PM ECU: a060 torque reversal window";
CM_ SG_ 1444 PM_a061_diIpcVersion "PM ECU: a061 di ipc version";
CM_ SG_ 1444 PM_a061_pmIpcVersion "PM ECU: a061 pm ipc version";
CM_ SG_ 1444 PM_a062_address "PM ECU: a062 address";
CM_ SG_ 1444 PM_a062_errorType "PM ECU: a062 error type";
CM_ SG_ 1444 PM_a063_totalSystemTorqueCommand "PM ECU: a063 total system torque command";
CM_ SG_ 1444 PM_a063_totalSystemTorqueMeasure "PM ECU: a063 total system torque measured";
CM_ SG_ 1444 PM_a064_interventionType "PM ECU: a064 intervention type";
CM_ SG_ 1444 PM_a064_torqueCmdState "PM ECU: a064 torque cmd state; raw 0 = signal not available (SNA)";
CM_ SG_ 1444 PM_a064_shortDetectedByDI "PM ECU: a064 short detected by DI";
CM_ SG_ 1444 PM_a064_UI_stoppingMode "PM ECU: a064 UI stopping mode";
CM_ SG_ 1444 PM_a064_diCrsState "PM ECU: a064 di crs state";
CM_ SG_ 1444 PM_a064_pmCrsState "PM ECU: a064 pm crs state";
CM_ SG_ 1444 PM_a066_state4 "PM ECU: a066 state4";
CM_ SG_ 1444 PM_a067_state4 "PM ECU: a067 state4";
CM_ SG_ 1444 PM_a073_canID "PM ECU: a073 can ID";
CM_ SG_ 1444 PM_a073_errorType "PM ECU: a073 error type";
CM_ SG_ 1444 PM_a073_badValue1 "PM ECU: a073 bad value1";
CM_ SG_ 1444 PM_a073_badValue2 "PM ECU: a073 bad value2";
CM_ SG_ 1444 PM_a074_mailboxID "PM ECU: a074 mailbox ID";
CM_ SG_ 1444 PM_a074_canID "PM ECU: a074 can ID";
CM_ SG_ 1444 PM_a074_errorType "PM ECU: a074 error type";
CM_ SG_ 1444 PM_a075_canID "PM ECU: a075 can ID";
CM_ SG_ 1444 PM_a075_errorType "PM ECU: a075 error type";
CM_ SG_ 1444 PM_a075_badValue1 "PM ECU: a075 bad value1";
CM_ SG_ 1444 PM_a075_badValue2 "PM ECU: a075 bad value2";
CM_ SG_ 1444 PM_a076_mailboxID "PM ECU: a076 mailbox ID";
CM_ SG_ 1444 PM_a076_canID "PM ECU: a076 can ID";
CM_ SG_ 1444 PM_a076_errorType "PM ECU: a076 error type";
CM_ SG_ 1444 PM_a077_canID "PM ECU: a077 can ID";
CM_ SG_ 1444 PM_a077_errorType "PM ECU: a077 error type";
CM_ SG_ 1444 PM_a077_badValue1 "PM ECU: a077 bad value1";
CM_ SG_ 1444 PM_a077_badValue2 "PM ECU: a077 bad value2";
CM_ SG_ 1444 PM_a078_mailboxID "PM ECU: a078 mailbox ID";
CM_ SG_ 1444 PM_a078_canID "PM ECU: a078 can ID";
CM_ SG_ 1444 PM_a078_errorType "PM ECU: a078 error type";
CM_ SG_ 1444 PM_a079_VEH_RCU_actuation "PM ECU: a079 VEH RCU actuation";
CM_ SG_ 1444 PM_a079_PARTY_RCU_actuation "PM ECU: a079 PARTY RCU actuation";
CM_ SG_ 1444 PM_a082_faultAddress "PM ECU: a082 fault address";
CM_ SG_ 1444 PM_a082_isWriteNotRead "PM ECU: a082 is write not read";
CM_ SG_ 1444 PM_a084_faultAddress "PM ECU: a084 fault address";
CM_ SG_ 1444 PM_a084_firewallId "PM ECU: a084 firewall id";
CM_ SG_ 1444 PM_a084_privId "PM ECU: a084 priv id";
CM_ SG_ 1444 PM_a084_ns "PM ECU: a084 ns";
CM_ SG_ 1444 PM_a084_faultType "PM ECU: a084 fault type";
CM_ SG_ 1444 PM_a085_DPB_actuator3 "PM ECU: a085 DPB actuator3";
CM_ SG_ 1444 PM_a087_mailboxID "PM ECU: a087 mailbox ID";
CM_ SG_ 1444 PM_a087_canID "PM ECU: a087 can ID";
CM_ SG_ 1444 PM_a087_errorType "PM ECU: a087 error type";
CM_ SG_ 1444 PM_a092_pllClockSource "PM ECU: a092 pll clock source";
CM_ SG_ 1444 PM_a100_index1kHzPeriodic "PM ECU: a100 index1k hz periodic";
CM_ SG_ 1444 PM_a100_index100HzPeriodic "PM ECU: a100 index100 hz periodic";
CM_ SG_ 1444 PM_a100_index10HzPeriodic "PM ECU: a100 index10 hz periodic";
CM_ SG_ 1444 PM_a100_indexSWI "PM ECU: a100 index SWI";
CM_ SG_ 1444 PM_a100_eepEvent "PM ECU: a100 eep event";
CM_ SG_ 1444 PM_a100_module500HzActive "PM ECU: a100 module500 hz active";
CM_ SG_ 1444 PM_a100_module50HzActive "PM ECU: a100 module50 hz active";
CM_ SG_ 1444 PM_a100_module1HzActive "PM ECU: a100 module1 hz active";
CM_ SG_ 1444 PM_a100_task10HzActive "PM ECU: a100 task10 hz active";
CM_ SG_ 1444 PM_a100_taskUdsActive "PM ECU: a100 task uds active";
CM_ BO_ 1551 "PM ECU message: info";
CM_ SG_ 1551 PM_infoIndex "PM ECU: info index";
CM_ SG_ 1551 PM_buildType "PM ECU: build type";
CM_ SG_ 1551 PM_buildConfigurationId "PM ECU: build configuration id";
CM_ SG_ 1551 PM_hardwareId "PM ECU: hardware id";
CM_ SG_ 1551 PM_deviceFused "PM ECU: device fused";
CM_ SG_ 1551 PM_componentId "PM ECU: component id";
CM_ SG_ 1551 PM_pcbaId "PM ECU: pcba id";
CM_ SG_ 1551 PM_assemblyId "PM ECU: assembly id";
CM_ SG_ 1551 PM_usageId "PM ECU: usage id";
CM_ SG_ 1551 PM_subUsageId "PM ECU: sub usage id";
CM_ SG_ 1551 PM_applicationCrc "PM ECU: application crc";
CM_ SG_ 1551 PM_bootGitHash "PM ECU: boot git hash";
CM_ BO_ 1766 "PNCD ECU message: iso tp pipe to cp; forwarded onto this bus by the gateway";
CM_ SG_ 1766 PNCD_isoTpToCpData "PNCD ECU: iso tp to cp data";
CM_ BO_ 837 "Cabin heater message: info";
CM_ SG_ 837 PTC_infoIndex "Cabin heater: info index";
CM_ SG_ 837 PTC_infoBuildType "Cabin heater: info build type";
CM_ SG_ 837 PTC_infoBuildConfigId "Cabin heater: info build config id";
CM_ SG_ 837 PTC_infoHardwareId "Cabin heater: info hardware id";
CM_ SG_ 837 PTC_infoComponentId "Cabin heater: info component id";
CM_ SG_ 837 PTC_infoPcbaId "Cabin heater: info pcba id";
CM_ SG_ 837 PTC_infoAssemblyId "Cabin heater: info assembly id; raw 255 = signal not available (SNA)";
CM_ SG_ 837 PTC_infoUsageId "Cabin heater: info usage id";
CM_ SG_ 837 PTC_infoSubUsageId "Cabin heater: info sub usage id";
CM_ SG_ 837 PTC_infoPlatformType "Cabin heater: info platform type";
CM_ SG_ 837 PTC_infoAppCrc "Cabin heater: info app crc";
CM_ SG_ 837 PTC_infoBootUdsProtoVersion "Cabin heater: info boot uds proto version";
CM_ SG_ 837 PTC_infoBootCrc "Cabin heater: info boot crc";
CM_ BO_ 647 "Cabin heater message: sensor status";
CM_ SG_ 647 PTC_leftTempIGBT "Heater left bank IGBT temperature";
CM_ SG_ 647 PTC_tempOCP "Temperature measured near the over current protection circuit";
CM_ SG_ 647 PTC_rightTempIGBT "Heater right bank IGBT temperature";
CM_ SG_ 647 PTC_tempPCB "Heater printed circuit board temperature";
CM_ SG_ 647 PTC_voltageHV "Heater high voltage input voltage";
CM_ SG_ 647 PTC_leftCurrentHV "Cabin heater: left current HV";
CM_ SG_ 647 PTC_rightCurrentHV "Cabin heater: right current HV";
CM_ BO_ 1344 "Steering column control module message: alert log";
CM_ SG_ 1344 SCCM_alertID "Steering column control module: alert ID";
CM_ SG_ 1344 SCCM_alertState "Steering column control module: alert state";
CM_ SG_ 1344 SCCM_a003_debouncePosition "Steering column control module: a003 debounce position";
CM_ SG_ 1344 SCCM_a003_rawPosition "Steering column control module: a003 raw position";
CM_ SG_ 1344 SCCM_a003_errorPosition "Steering column control module: a003 error position";
CM_ SG_ 1344 SCCM_a003_adcValue "Steering column control module: a003 adc value";
CM_ SG_ 1344 SCCM_a004_debouncePosition "Steering column control module: a004 debounce position";
CM_ SG_ 1344 SCCM_a004_rawPosition "Steering column control module: a004 raw position";
CM_ SG_ 1344 SCCM_a004_errorPosition "Steering column control module: a004 error position";
CM_ SG_ 1344 SCCM_a004_adcValue "Steering column control module: a004 adc value";
CM_ SG_ 1344 SCCM_a005_debouncePosition "Steering column control module: a005 debounce position";
CM_ SG_ 1344 SCCM_a005_rawPosition "Steering column control module: a005 raw position";
CM_ SG_ 1344 SCCM_a005_errorPosition "Steering column control module: a005 error position";
CM_ SG_ 1344 SCCM_a005_adcValue "Steering column control module: a005 adc value";
CM_ SG_ 1344 SCCM_a006_debouncePosition "Steering column control module: a006 debounce position";
CM_ SG_ 1344 SCCM_a006_rawPosition "Steering column control module: a006 raw position";
CM_ SG_ 1344 SCCM_a006_errorPosition "Steering column control module: a006 error position";
CM_ SG_ 1344 SCCM_a006_adcValue "Steering column control module: a006 adc value";
CM_ SG_ 1344 SCCM_a007_debouncePosition "Steering column control module: a007 debounce position";
CM_ SG_ 1344 SCCM_a007_rawPosition "Steering column control module: a007 raw position";
CM_ SG_ 1344 SCCM_a007_errorPosition "Steering column control module: a007 error position";
CM_ SG_ 1344 SCCM_a007_adcValue1 "Steering column control module: a007 adc value1";
CM_ SG_ 1344 SCCM_a007_adcValue2 "Steering column control module: a007 adc value2";
CM_ SG_ 1344 SCCM_a008_debouncePosition "Steering column control module: a008 debounce position";
CM_ SG_ 1344 SCCM_a008_rawPosition "Steering column control module: a008 raw position";
CM_ SG_ 1344 SCCM_a008_errorPosition "Steering column control module: a008 error position";
CM_ SG_ 1344 SCCM_a008_adcValue1 "Steering column control module: a008 adc value1";
CM_ SG_ 1344 SCCM_a008_adcValue2 "Steering column control module: a008 adc value2";
CM_ SG_ 1344 SCCM_a009_debouncePosition "Steering column control module: a009 debounce position";
CM_ SG_ 1344 SCCM_a009_rawPosition "Steering column control module: a009 raw position";
CM_ SG_ 1344 SCCM_a009_errorPosition "Steering column control module: a009 error position";
CM_ SG_ 1344 SCCM_a009_adcValue1 "Steering column control module: a009 adc value1";
CM_ SG_ 1344 SCCM_a009_adcValue2 "Steering column control module: a009 adc value2";
CM_ SG_ 1344 SCCM_a010_debouncePosition "Steering column control module: a010 debounce position";
CM_ SG_ 1344 SCCM_a010_rawPosition "Steering column control module: a010 raw position";
CM_ SG_ 1344 SCCM_a010_errorPosition "Steering column control module: a010 error position";
CM_ SG_ 1344 SCCM_a010_adcValue1 "Steering column control module: a010 adc value1";
CM_ SG_ 1344 SCCM_a010_adcValue2 "Steering column control module: a010 adc value2";
CM_ SG_ 1344 SCCM_a011_debouncePosition "Steering column control module: a011 debounce position";
CM_ SG_ 1344 SCCM_a011_rawPosition "Steering column control module: a011 raw position";
CM_ SG_ 1344 SCCM_a011_errorPosition "Steering column control module: a011 error position";
CM_ SG_ 1344 SCCM_a011_adcValue1 "Steering column control module: a011 adc value1";
CM_ SG_ 1344 SCCM_a011_adcValue2 "Steering column control module: a011 adc value2";
CM_ SG_ 1344 SCCM_a012_debouncePosition "Steering column control module: a012 debounce position";
CM_ SG_ 1344 SCCM_a012_rawPosition "Steering column control module: a012 raw position";
CM_ SG_ 1344 SCCM_a012_errorPosition "Steering column control module: a012 error position";
CM_ SG_ 1344 SCCM_a012_adcValue1 "Steering column control module: a012 adc value1";
CM_ SG_ 1344 SCCM_a012_adcValue2 "Steering column control module: a012 adc value2";
CM_ SG_ 1344 SCCM_a013_voltage "Steering column control module: a013 voltage";
CM_ SG_ 1344 SCCM_a014_voltage "Steering column control module: a014 voltage";
CM_ SG_ 1344 SCCM_a015_intMainIndex "Steering column control module: a015 int main index";
CM_ SG_ 1344 SCCM_a015_intSubIndex "Steering column control module: a015 int sub index";
CM_ SG_ 1344 SCCM_a015_intMemIndex "Steering column control module: a015 int mem index";
CM_ SG_ 1344 SCCM_a016_mainAdcTest "Steering column control module: a016 main adc test";
CM_ SG_ 1344 SCCM_a016_mainCpuTest "Steering column control module: a016 main cpu test";
CM_ SG_ 1344 SCCM_a016_wdtTest "Steering column control module: a016 wdt test";
CM_ SG_ 1344 SCCM_a016_subCpuTest "Steering column control module: a016 sub cpu test";
CM_ SG_ 1344 SCCM_a016_subAdcTest "Steering column control module: a016 sub adc test";
CM_ SG_ 1344 SCCM_a017_mainRamTest "Steering column control module: a017 main ram test";
CM_ SG_ 1344 SCCM_a017_mainRomTest "Steering column control module: a017 main rom test";
CM_ SG_ 1344 SCCM_a017_stackHardLimitTest "Steering column control module: a017 stack hard limit test";
CM_ SG_ 1344 SCCM_a017_mainDataFlashTest "Steering column control module: a017 main data flash test";
CM_ SG_ 1344 SCCM_a017_subRamTest "Steering column control module: a017 sub ram test";
CM_ SG_ 1344 SCCM_a017_subRomTest "Steering column control module: a017 sub rom test";
CM_ SG_ 1344 SCCM_a017_subStackHardLimitTest "Steering column control module: a017 sub stack hard limit test";
CM_ SG_ 1344 SCCM_a017_svError "Steering column control module: a017 sv error";
CM_ SG_ 1344 SCCM_a018_internalSASState "Steering column control module: a018 internal SAS state";
CM_ SG_ 1344 SCCM_a019_internalSASState "Steering column control module: a019 internal SAS state";
CM_ SG_ 1344 SCCM_a020_internalSASState "Steering column control module: a020 internal SAS state";
CM_ SG_ 1344 SCCM_a021_adcValue1 "Steering column control module: a021 adc value1";
CM_ SG_ 1344 SCCM_a021_adcValue2 "Steering column control module: a021 adc value2";
CM_ SG_ 1344 SCCM_a021_adcValue3 "Steering column control module: a021 adc value3";
CM_ SG_ 1344 SCCM_a021_adcValue4 "Steering column control module: a021 adc value4";
CM_ SG_ 1344 SCCM_a021_adcValue5 "Steering column control module: a021 adc value5";
CM_ SG_ 1344 SCCM_a021_adcValue6 "Steering column control module: a021 adc value6";
CM_ SG_ 1344 SCCM_a022_adcValue1 "Steering column control module: a022 adc value1";
CM_ SG_ 1344 SCCM_a022_adcValue2 "Steering column control module: a022 adc value2";
CM_ SG_ 1344 SCCM_a022_adcValue3 "Steering column control module: a022 adc value3";
CM_ SG_ 1344 SCCM_a022_adcValue4 "Steering column control module: a022 adc value4";
CM_ SG_ 1344 SCCM_a022_adcValue5 "Steering column control module: a022 adc value5";
CM_ SG_ 1344 SCCM_a022_adcValue6 "Steering column control module: a022 adc value6";
CM_ SG_ 1344 SCCM_a023_adcValue1 "Steering column control module: a023 adc value1";
CM_ SG_ 1344 SCCM_a023_adcValue2 "Steering column control module: a023 adc value2";
CM_ SG_ 1344 SCCM_a023_adcValue3 "Steering column control module: a023 adc value3";
CM_ SG_ 1344 SCCM_a023_adcValue4 "Steering column control module: a023 adc value4";
CM_ SG_ 1344 SCCM_a023_adcValue5 "Steering column control module: a023 adc value5";
CM_ SG_ 1344 SCCM_a023_adcValue6 "Steering column control module: a023 adc value6";
CM_ SG_ 1344 SCCM_a024_adcValue1 "Steering column control module: a024 adc value1";
CM_ SG_ 1344 SCCM_a024_adcValue2 "Steering column control module: a024 adc value2";
CM_ SG_ 1344 SCCM_a024_adcValue3 "Steering column control module: a024 adc value3";
CM_ SG_ 1344 SCCM_a024_adcValue4 "Steering column control module: a024 adc value4";
CM_ SG_ 1344 SCCM_a024_adcValue5 "Steering column control module: a024 adc value5";
CM_ SG_ 1344 SCCM_a024_adcValue6 "Steering column control module: a024 adc value6";
CM_ SG_ 1344 SCCM_a025_taskState "Steering column control module: a025 task state";
CM_ SG_ 1344 SCCM_a026_debouncePosition "Steering column control module: a026 debounce position";
CM_ SG_ 1344 SCCM_a026_rawPosition "Steering column control module: a026 raw position";
CM_ SG_ 1344 SCCM_a026_errorPosition "Steering column control module: a026 error position";
CM_ SG_ 1344 SCCM_a026_adcValue1 "Steering column control module: a026 adc value1";
CM_ SG_ 1344 SCCM_a026_adcValue2 "Steering column control module: a026 adc value2";
CM_ SG_ 1344 SCCM_a027_debouncePosition "Steering column control module: a027 debounce position";
CM_ SG_ 1344 SCCM_a027_rawPosition "Steering column control module: a027 raw position";
CM_ SG_ 1344 SCCM_a027_errorPosition "Steering column control module: a027 error position";
CM_ SG_ 1344 SCCM_a027_adcValue1 "Steering column control module: a027 adc value1";
CM_ SG_ 1344 SCCM_a027_adcValue2 "Steering column control module: a027 adc value2";
CM_ SG_ 1344 SCCM_a028_debouncePosition "Steering column control module: a028 debounce position";
CM_ SG_ 1344 SCCM_a028_rawPosition "Steering column control module: a028 raw position";
CM_ SG_ 1344 SCCM_a028_errorPosition "Steering column control module: a028 error position";
CM_ SG_ 1344 SCCM_a028_adcValue1 "Steering column control module: a028 adc value1";
CM_ SG_ 1344 SCCM_a028_adcValue2 "Steering column control module: a028 adc value2";
CM_ SG_ 1344 SCCM_a029_debouncePosition "Steering column control module: a029 debounce position";
CM_ SG_ 1344 SCCM_a029_rawPosition "Steering column control module: a029 raw position";
CM_ SG_ 1344 SCCM_a029_errorPosition "Steering column control module: a029 error position";
CM_ SG_ 1344 SCCM_a029_adcValue1 "Steering column control module: a029 adc value1";
CM_ SG_ 1344 SCCM_a029_adcValue2 "Steering column control module: a029 adc value2";
CM_ SG_ 1344 SCCM_a061_voltage "Steering column control module: a061 voltage";
CM_ SG_ 1344 SCCM_a062_voltage "Steering column control module: a062 voltage";
CM_ SG_ 1344 SCCM_a063_UntrimmedAngle "Steering column control module: a063 untrimmed angle; raw 16383 = signal not available (SNA)";
CM_ SG_ 1344 SCCM_a064_Speed "Steering column control module: a064 speed; raw 16383 = signal not available (SNA)";
CM_ SG_ 1344 SCCM_a065_M1RawAngleCurrent "Steering column control module: a065 M1 raw angle current";
CM_ SG_ 1344 SCCM_a065_M1RawAnglePrevious "Steering column control module: a065 M1 raw angle previous";
CM_ SG_ 1344 SCCM_a065_M2RawAngleCurrent "Steering column control module: a065 M2 raw angle current";
CM_ SG_ 1344 SCCM_a065_M2RawAnglePrevious "Steering column control module: a065 M2 raw angle previous";
CM_ SG_ 1344 SCCM_a066_M1RawAngleCurrent "Steering column control module: a066 M1 raw angle current";
CM_ SG_ 1344 SCCM_a066_M1RawAnglePrevious "Steering column control module: a066 M1 raw angle previous";
CM_ SG_ 1344 SCCM_a066_M2RawAngleCurrent "Steering column control module: a066 M2 raw angle current";
CM_ SG_ 1344 SCCM_a066_M2RawAnglePrevious "Steering column control module: a066 M2 raw angle previous";
CM_ SG_ 1344 SCCM_a071_M1LogicBISTFailed "Steering column control module: a071 M1 logic BIST failed";
CM_ SG_ 1344 SCCM_a071_M1PowerOnReset "Steering column control module: a071 M1 power on reset";
CM_ SG_ 1344 SCCM_a071_M1UnderVoltage "Steering column control module: a071 M1 under voltage";
CM_ SG_ 1344 SCCM_a071_M1OverVoltage "Steering column control module: a071 M1 over voltage";
CM_ SG_ 1344 SCCM_a071_M1DualBitError "Steering column control module: a071 M1 dual bit error";
CM_ SG_ 1344 SCCM_a071_M1RefVoltageOutOfRange "Steering column control module: a071 M1 ref voltage out of range";
CM_ SG_ 1344 SCCM_a071_M1RegisterParityError "Steering column control module: a071 M1 register parity error";
CM_ SG_ 1344 SCCM_a071_M1OscillatorFreqError "Steering column control module: a071 M1 oscillator freq error";
CM_ SG_ 1344 SCCM_a071_M1SignalOutOfRange "Steering column control module: a071 M1 signal out of range";
CM_ SG_ 1344 SCCM_a071_M1TempOutOfRange "Steering column control module: a071 M1 temp out of range";
CM_ SG_ 1344 SCCM_a071_M1AngleMismatch "Steering column control module: a071 M1 angle mismatch";
CM_ SG_ 1344 SCCM_a071_M1RadiusOutOfRange "Steering column control module: a071 M1 radius out of range";
CM_ SG_ 1344 SCCM_a071_M2LogicBISTFailed "Steering column control module: a071 M2 logic BIST failed";
CM_ SG_ 1344 SCCM_a071_M2PowerOnReset "Steering column control module: a071 M2 power on reset";
CM_ SG_ 1344 SCCM_a071_M2UnderVoltage "Steering column control module: a071 M2 under voltage";
CM_ SG_ 1344 SCCM_a071_M2OverVoltage "Steering column control module: a071 M2 over voltage";
CM_ SG_ 1344 SCCM_a071_M2DualBitError "Steering column control module: a071 M2 dual bit error";
CM_ SG_ 1344 SCCM_a071_M2RefVoltageOutOfRange "Steering column control module: a071 M2 ref voltage out of range";
CM_ SG_ 1344 SCCM_a071_M2RegisterParityError "Steering column control module: a071 M2 register parity error";
CM_ SG_ 1344 SCCM_a071_M2OscillatorFreqError "Steering column control module: a071 M2 oscillator freq error";
CM_ SG_ 1344 SCCM_a071_M2SignalOutOfRange "Steering column control module: a071 M2 signal out of range";
CM_ SG_ 1344 SCCM_a071_M2TempOutOfRange "Steering column control module: a071 M2 temp out of range";
CM_ SG_ 1344 SCCM_a071_M2AngleMismatch "Steering column control module: a071 M2 angle mismatch";
CM_ SG_ 1344 SCCM_a071_M2RadiusOutOfRange "Steering column control module: a071 M2 radius out of range";
CM_ SG_ 1344 SCCM_a071_M1ProcessLogicFailed "Steering column control module: a071 M1 process logic failed";
CM_ SG_ 1344 SCCM_a071_M2ProcessLogicFailed "Steering column control module: a071 M2 process logic failed";
CM_ SG_ 1344 SCCM_a071_TSOSCHighFreqError "Steering column control module: a071 TSOSC high freq error";
CM_ SG_ 1344 SCCM_a071_TSOSCLowFreqError "Steering column control module: a071 TSOSC low freq error";
CM_ SG_ 1344 SCCM_a071_TSOPRStatMismatch "Steering column control module: a071 TSOPR stat mismatch";
CM_ SG_ 1344 SCCM_a071_TSCRCStatError "Steering column control module: a071 TSCRC stat error";
CM_ SG_ 1344 SCCM_a071_TSFrameStatError "Steering column control module: a071 TS frame stat error";
CM_ SG_ 1344 SCCM_a071_TSOverVoltage "Steering column control module: a071 TS over voltage";
CM_ SG_ 1344 SCCM_a071_TSUnderVoltage "Steering column control module: a071 TS under voltage";
CM_ SG_ 1344 SCCM_a071_TSPowerOnReset "Steering column control module: a071 TS power on reset";
CM_ SG_ 1344 SCCM_a071_TSLDOStatError "Steering column control module: a071 TSLDO stat error";
CM_ SG_ 1344 SCCM_a071_TSTempOutOfRange "Steering column control module: a071 TS temp out of range";
CM_ SG_ 1344 SCCM_a071_TSAlertIntegrityCheck "Steering column control module: a071 TS alert integrity check";
CM_ SG_ 1344 SCCM_a071_TSMemoryCRCError "Steering column control module: a071 TS memory CRC error";
CM_ SG_ 1344 SCCM_a071_TSAFECheck "Steering column control module: a071 TSAFE check";
CM_ SG_ 1344 SCCM_a071_TSADCCheck "Steering column control module: a071 TSADC check";
CM_ SG_ 1344 SCCM_a071_TSConfigFault "Steering column control module: a071 TS config fault";
CM_ SG_ 1344 SCCM_a072_M1CRCCalculated "Steering column control module: a072 M1 CRC calculated";
CM_ SG_ 1344 SCCM_a072_M1CRCReceived "Steering column control module: a072 M1 CRC received";
CM_ SG_ 1344 SCCM_a072_M2CRCCalculated "Steering column control module: a072 M2 CRC calculated";
CM_ SG_ 1344 SCCM_a072_M2CRCReceived "Steering column control module: a072 M2 CRC received";
CM_ SG_ 1344 SCCM_a072_TSCRCCalculated "Steering column control module: a072 TSCRC calculated";
CM_ SG_ 1344 SCCM_a072_TSCRCReceived "Steering column control module: a072 TSCRC received";
CM_ SG_ 1344 SCCM_a075_ClockOutOfRange "Steering column control module: a075 clock out of range";
CM_ SG_ 1344 SCCM_a075_ExtWatchdogTestFailed "Steering column control module: a075 ext watchdog test failed";
CM_ SG_ 1344 SCCM_a075_InterruptMonitorError "Steering column control module: a075 interrupt monitor error";
CM_ SG_ 1344 SCCM_a076_RAMTestFailed "Steering column control module: a076 RAM test failed";
CM_ SG_ 1344 SCCM_a076_NVMTestFailed "Steering column control module: a076 NVM test failed";
CM_ SG_ 1344 SCCM_a077_M1ExpectAngleCurrent "Steering column control module: a077 M1 expect angle current";
CM_ SG_ 1344 SCCM_a077_M1ExpectAnglePrevious "Steering column control module: a077 M1 expect angle previous";
CM_ SG_ 1344 SCCM_a077_M1AngleCurrent "Steering column control module: a077 M1 angle current";
CM_ SG_ 1344 SCCM_a077_M1AnglePrevious "Steering column control module: a077 M1 angle previous";
CM_ SG_ 1344 SCCM_a079_ChipTemperature "Steering column control module: a079 chip temperature";
CM_ SG_ 1344 SCCM_a081_StartupTestStatus "Steering column control module: a081 startup test status";
CM_ SG_ 1344 SCCM_a081_sCheckTestFailedData "Steering column control module: a081 s check test failed data";
CM_ SG_ 1344 SCCM_a081_sBootTestFailedData "Steering column control module: a081 s boot test failed data";
CM_ SG_ 1344 SCCM_a081_BISTTestFailedData "Steering column control module: a081 BIST test failed data";
CM_ SG_ 1344 SCCM_a082_RuntimeTestStatus "Steering column control module: a082 runtime test status";
CM_ SG_ 1344 SCCM_a082_sCheckTestFailedData "Steering column control module: a082 s check test failed data";
CM_ SG_ 1344 SCCM_a082_ArrayIntegrFailedData "Steering column control module: a082 array integr failed data";
CM_ SG_ 1344 SCCM_a121_turnIndicatorStalkAngl "Steering column control module: a121 turn indicator stalk angle";
CM_ SG_ 1344 SCCM_a121_turnIndicatorHallAngle "Steering column control module: a121 turn indicator hall angle";
CM_ SG_ 1344 SCCM_a122_turnIndicatorSpeed "Steering column control module: a122 turn indicator speed";
CM_ SG_ 1344 SCCM_a123_turnIndicatorStalkAngl "Steering column control module: a123 turn indicator stalk angle";
CM_ SG_ 1344 SCCM_a124_turnIndicatorStalkAngl "Steering column control module: a124 turn indicator stalk angle";
CM_ SG_ 1344 SCCM_a125_turnIndicatorHallAngle "Steering column control module: a125 turn indicator hall angle";
CM_ SG_ 1344 SCCM_a125_turnIndicatorVectorAng "Steering column control module: a125 turn indicator vector angle";
CM_ SG_ 1344 SCCM_a126_turnIndicatorXVectorOu "Steering column control module: a126 turn indicator x vector out of range";
CM_ SG_ 1344 SCCM_a126_turnIndicatorYVectorOu "Steering column control module: a126 turn indicator y vector out of range";
CM_ SG_ 1344 SCCM_a126_turnIndicatorZVectorOu "Steering column control module: a126 turn indicator z vector out of range";
CM_ SG_ 1344 SCCM_a126_turnIndicatorResu_0001 "Steering column control module: a126 turn indicator resultant out of range";
CM_ SG_ 1344 SCCM_a126_turnIndicatorXMagnitud "Steering column control module: a126 turn indicator x magnitude";
CM_ SG_ 1344 SCCM_a126_turnIndicatorYMagnitud "Steering column control module: a126 turn indicator y magnitude";
CM_ SG_ 1344 SCCM_a126_turnIndicatorZMagnitud "Steering column control module: a126 turn indicator z magnitude";
CM_ SG_ 1344 SCCM_a126_turnIndicatorResultant "Steering column control module: a126 turn indicator resultant magnitude";
CM_ BO_ 1359 "Steering column control module message: alert matrix";
CM_ SG_ 1359 SCCM_matrixIndex "Steering column control module: matrix index";
CM_ SG_ 1359 SCCM_a001_CANBusOff "Steering column control module: a001 CAN bus off";
CM_ SG_ 1359 SCCM_a002_CANTOut "Steering column control module: a002 CANT out";
CM_ SG_ 1359 SCCM_a003_highBeamOpen "Steering column control module: a003 high beam open";
CM_ SG_ 1359 SCCM_a004_highBeamShortToGND "Steering column control module: a004 high beam short to GND";
CM_ SG_ 1359 SCCM_a005_tipWipeOpen "Steering column control module: a005 tip wipe open";
CM_ SG_ 1359 SCCM_a006_tipWipeShortToGND "Steering column control module: a006 tip wipe short to GND";
CM_ SG_ 1359 SCCM_a007_turnIndComInfo "Steering column control module: a007 turn ind com info";
CM_ SG_ 1359 SCCM_a008_turnIndInvalidTrans "Steering column control module: a008 turn ind invalid trans";
CM_ SG_ 1359 SCCM_a009_turnIndOpen "Steering column control module: a009 turn ind open";
CM_ SG_ 1359 SCCM_a010_turnIndShortToGnd "Steering column control module: a010 turn ind short to gnd";
CM_ SG_ 1359 SCCM_a011_turnIndHWErr "Steering column control module: a011 turn ind HW err";
CM_ SG_ 1359 SCCM_a012_turnGenErr "Steering column control module: a012 turn gen err";
CM_ SG_ 1359 SCCM_a013_voltageHigh "Steering column control module: a013 voltage high";
CM_ SG_ 1359 SCCM_a014_voltageLow "Steering column control module: a014 voltage low";
CM_ SG_ 1359 SCCM_a015_softwareError "Steering column control module: a015 software error";
CM_ SG_ 1359 SCCM_a016_hardwareError "Steering column control module: a016 hardware error";
CM_ SG_ 1359 SCCM_a017_memoryError "Steering column control module: a017 memory error";
CM_ SG_ 1359 SCCM_a018_angleSpeedOutOfRange "Steering column control module: a018 angle speed out of range";
CM_ SG_ 1359 SCCM_a019_angleOutOfRange "Steering column control module: a019 angle out of range";
CM_ SG_ 1359 SCCM_a020_angleInternalError "Steering column control module: a020 angle internal error";
CM_ SG_ 1359 SCCM_a021_gearStalkSignalInvalid "Steering column control module: a021 gear stalk signal invalid";
CM_ SG_ 1359 SCCM_a022_gearStalkOpenCircuit "Steering column control module: a022 gear stalk open circuit";
CM_ SG_ 1359 SCCM_a023_gearStalkShortCircuit "Steering column control module: a023 gear stalk short circuit";
CM_ SG_ 1359 SCCM_a024_gearStalkGenErr "Steering column control module: a024 gear stalk gen err";
CM_ SG_ 1359 SCCM_a025_runTimeError "Steering column control module: a025 run time error";
CM_ SG_ 1359 SCCM_a026_parkButtonInvalidSigna "Steering column control module: a026 park button invalid signal";
CM_ SG_ 1359 SCCM_a027_parkButtonOpenCircuit "Steering column control module: a027 park button open circuit";
CM_ SG_ 1359 SCCM_a028_parkButtonShortToGroun "Steering column control module: a028 park button short to ground";
CM_ SG_ 1359 SCCM_a029_parkButtonMalfunction "Steering column control module: a029 park button malfunction";
CM_ SG_ 1359 SCCM_a061_voltageHigh_2 "Steering column control module: a061 voltage high 2";
CM_ SG_ 1359 SCCM_a062_voltageLow_2 "Steering column control module: a062 voltage low 2";
CM_ SG_ 1359 SCCM_a063_angleOutOfRange_2 "Steering column control module: a063 angle out of range 2";
CM_ SG_ 1359 SCCM_a064_angleSpeedOutOfRange_2 "Steering column control module: a064 angle speed out of range 2";
CM_ SG_ 1359 SCCM_a065_angleNotPlausible "Steering column control module: a065 angle not plausible";
CM_ SG_ 1359 SCCM_a066_angleSpeedNotPlausible "Steering column control module: a066 angle speed not plausible";
CM_ SG_ 1359 SCCM_a067_CANBusOff_2 "Steering column control module: a067 CAN bus off 2";
CM_ SG_ 1359 SCCM_a068_CANLVPowerState_LOC "Steering column control module: a068 CANLV power state LOC";
CM_ SG_ 1359 SCCM_a069_calibrationMismatch "Steering column control module: a069 calibration mismatch";
CM_ SG_ 1359 SCCM_a070_angleTrimMismatch "Steering column control module: a070 angle trim mismatch";
CM_ SG_ 1359 SCCM_a071_angleHallSensorError "Steering column control module: a071 angle hall sensor error";
CM_ SG_ 1359 SCCM_a072_spiBitErrors "Steering column control module: a072 spi bit errors";
CM_ SG_ 1359 SCCM_a073_watchdogReset "Steering column control module: a073 watchdog reset";
CM_ SG_ 1359 SCCM_a074_PLLLossOfLock "Steering column control module: a074 PLL loss of lock";
CM_ SG_ 1359 SCCM_a075_hardwareError_2 "Steering column control module: a075 hardware error 2";
CM_ SG_ 1359 SCCM_a076_memoryError_2 "Steering column control module: a076 memory error 2";
CM_ SG_ 1359 SCCM_a077_gearAngleNotPlausible "Steering column control module: a077 gear angle not plausible";
CM_ SG_ 1359 SCCM_a078_ADCCalibrationError "Steering column control module: a078 ADC calibration error";
CM_ SG_ 1359 SCCM_a079_chipTempOutOfRange "Steering column control module: a079 chip temp out of range";
CM_ SG_ 1359 SCCM_a080_ADCSelfTestFailed "Steering column control module: a080 ADC self test failed";
CM_ SG_ 1359 SCCM_a081_startupTestFailed "Steering column control module: a081 startup test failed";
CM_ SG_ 1359 SCCM_a082_runtimeTestFailed "Steering column control module: a082 runtime test failed";
CM_ SG_ 1359 SCCM_a121_turnIndicatorAngleInva "Steering column control module: a121 turn indicator angle invalid";
CM_ SG_ 1359 SCCM_a122_turnIndicatorSpeedInva "Steering column control module: a122 turn indicator speed invalid";
CM_ SG_ 1359 SCCM_a123_turnIndicatorStuckActi "Steering column control module: a123 turn indicator stuck active";
CM_ SG_ 1359 SCCM_a124_turnIndicatorIdleInval "Steering column control module: a124 turn indicator idle invalid";
CM_ SG_ 1359 SCCM_a125_turnIndicatorHallAngle "Steering column control module: a125 turn indicator hall angle mismatch";
CM_ SG_ 1359 SCCM_a126_turnIndicatorHallMagOu "Steering column control module: a126 turn indicator hall mag out of range";
CM_ BO_ 816 "Steering column control module message: info";
CM_ SG_ 816 SCCM_infoIndex "Steering column control module: info index";
CM_ SG_ 816 SCCM_infoBuildType "Steering column control module: info build type";
CM_ SG_ 816 SCCM_infoBuildConfigId "Steering column control module: info build config id";
CM_ SG_ 816 SCCM_infoHardwareId "Steering column control module: info hardware id";
CM_ SG_ 816 SCCM_infoComponentId "Steering column control module: info component id";
CM_ SG_ 816 SCCM_infoPcbaId "Steering column control module: info pcba id";
CM_ SG_ 816 SCCM_infoAssemblyId "Steering column control module: info assembly id";
CM_ SG_ 816 SCCM_infoUsageId "Steering column control module: info usage id";
CM_ SG_ 816 SCCM_infoSubUsageId "Steering column control module: info sub usage id";
CM_ SG_ 816 SCCM_infoPlatformType "Steering column control module: info platform type";
CM_ SG_ 816 SCCM_infoAppCrc "Steering column control module: info app crc";
CM_ SG_ 816 SCCM_infoBootSvnRev "Steering column control module: info boot svn rev";
CM_ SG_ 816 SCCM_infoBootSvnUrlHash "Steering column control module: info boot svn url hash";
CM_ SG_ 816 SCCM_infoSubcomponent1Version "Steering column control module: info subcomponent1 version";
CM_ SG_ 816 SCCM_infoAppSvnHash "Steering column control module: info app svn hash";
CM_ SG_ 816 SCCM_infoBootSvnHash "Steering column control module: info boot svn hash";
CM_ SG_ 816 SCCM_infoUdsProtoVersion "Steering column control module: info uds proto version";
CM_ SG_ 816 SCCM_infoBootCrc "Steering column control module: info boot crc";
CM_ BO_ 585 "Steering column control module message: left stalk";
CM_ SG_ 585 SCCM_leftStalkCrc "Steering column control module: left stalk crc";
CM_ SG_ 585 SCCM_leftStalkCounter "Steering column control module: left stalk counter";
CM_ SG_ 585 SCCM_highBeamStalkStatus "Active state of high beam push/pull stalk position; raw 3 = signal not available (SNA)";
CM_ SG_ 585 SCCM_washWipeButtonStatus "Active state of wash/wipe button on the turn signal stalk; raw 3 = signal not available (SNA)";
CM_ SG_ 585 SCCM_turnIndicatorStalkStatus "Active state of turn indicator stalk position; raw 9 = signal not available (SNA)";
CM_ SG_ 585 SCCM_turnIndicatorStalkAngle "Measured angle of the turn signal stalk; raw 4095 = signal not available (SNA)";
CM_ BO_ 553 "Steering column control module message: right stalk";
CM_ SG_ 553 SCCM_rightStalkCrc "Steering column control module: right stalk crc";
CM_ SG_ 553 SCCM_rightStalkCounter "Steering column control module: right stalk counter";
CM_ SG_ 553 SCCM_rightStalkStatus "Active state of drive stalk position, does not indicate active drive gear; raw 6 = signal not available (SNA)";
CM_ SG_ 553 SCCM_rightStalkReserved1 "Steering column control module: right stalk reserved1";
CM_ SG_ 553 SCCM_parkButtonStatus "Active state of park button on the drive stalk; raw 3 = signal not available (SNA)";
CM_ SG_ 553 SCCM_rightStalkReserved2 "Steering column control module: right stalk reserved2";
CM_ BO_ 297 "Steering column control module message: steering angle sensor";
CM_ SG_ 297 SCCM_steeringAngleCrc "Steering column control module: steering angle crc";
CM_ SG_ 297 SCCM_steeringAngleCounter "Message counter";
CM_ SG_ 297 SCCM_supplierID "Steering column control module: supplier ID";
CM_ SG_ 297 SCCM_steeringAngleSensorStatus "Reports steering angle sensor status and validity based on bootup checks";
CM_ SG_ 297 SCCM_steeringAngle "Measured ASAS sensor angle; raw 16383 = signal not available (SNA)";
CM_ SG_ 297 SCCM_steeringAngleValidity "Transitions to VALID when rotation of over 4 deg has occurred; raw 3 = signal not available (SNA)";
CM_ SG_ 297 SCCM_steeringAngleSpeed "Speed of steering angle rotation";
CM_ SG_ 297 SCCM_steeringAngleSensorReservd1 "Steering column control module: steering angle sensor reservd1";
CM_ SG_ 297 SCCM_steeringAngleSensorReservd2 "Steering column control module: steering angle sensor reservd2";
CM_ SG_ 297 SCCM_steeringAngleSensorReservd3 "Steering column control module: steering angle sensor reservd3";
CM_ BO_ 1356 "SCM ECU message: alert log";
CM_ SG_ 1356 SCM_alertID "SCM ECU: alert ID";
CM_ SG_ 1356 SCM_alertType "SCM ECU: alert type";
CM_ SG_ 1356 SCM_a074_voltageWithRo "SCM ECU: a074 voltage with ro";
CM_ SG_ 1356 SCM_a074_voltageWithoutRo "SCM ECU: a074 voltage without ro";
CM_ BO_ 815 "SCM ECU message: alert matrix1";
CM_ SG_ 815 SCM_a027_externalIsolationLow "SCM ECU: a027 external isolation low";
CM_ SG_ 815 SCM_a044_proximityRationality "SCM ECU: a044 proximity rationality";
CM_ BO_ 1355 "SCM ECU message: alert matrix2";
CM_ SG_ 1355 SCM_a074_isoVDiffHi "SCM ECU: a074 iso v diff hi";
CM_ SG_ 1355 SCM_a076_bmsMIA "SCM ECU: a076 bms MIA";
CM_ SG_ 1355 SCM_a078_voltageMatchTimeout "SCM ECU: a078 voltage match timeout";
CM_ SG_ 1355 SCM_a091_voltageRiseDetection "SCM ECU: a091 voltage rise detection";
CM_ BO_ 1354 "SCS ECU message: alert log";
CM_ SG_ 1354 SCS_alertID "SCS ECU: alert ID";
CM_ SG_ 1354 SCS_alertType "SCS ECU: alert type";
CM_ SG_ 1354 SCS_a044_proximityV "SCS ECU: a044 proximity v";
CM_ SG_ 1354 SCS_a074_voltageWithRo "SCS ECU: a074 voltage with ro";
CM_ SG_ 1354 SCS_a074_voltageWithoutRo "SCS ECU: a074 voltage without ro";
CM_ BO_ 869 "SCS ECU message: alert matrix1";
CM_ SG_ 869 SCS_a001_hwDSPfault "SCS ECU: a001 hw DS pfault";
CM_ SG_ 869 SCS_a002_hwIbatOC "SCS ECU: a002 hw ibat OC";
CM_ SG_ 869 SCS_a003_hwCordOT "SCS ECU: a003 hw cord OT";
CM_ SG_ 869 SCS_a004_hwVbusOV "SCS ECU: a004 hw vbus OV";
CM_ SG_ 869 SCS_a005_hwHVIL "SCS ECU: a005 hw HVIL";
CM_ SG_ 869 SCS_a006_hwWeld_V1 "SCS ECU: a006 hw weld V1";
CM_ SG_ 869 SCS_a007_hwWeld_V2 "SCS ECU: a007 hw weld V2";
CM_ SG_ 869 SCS_a008_hwIllegalCntrShoot "SCS ECU: a008 hw illegal cntr shoot";
CM_ SG_ 869 SCS_a009_hwOpen_V1 "SCS ECU: a009 hw open V1";
CM_ SG_ 869 SCS_a010_hwOpen_V2 "SCS ECU: a010 hw open V2";
CM_ SG_ 869 SCS_a011_hwIllegalCntrCmdV1 "SCS ECU: a011 hw illegal cntr cmd V1";
CM_ SG_ 869 SCS_a012_hwIllegalCntrCmdV2 "SCS ECU: a012 hw illegal cntr cmd V2";
CM_ SG_ 869 SCS_a013_cordTempHiFoldBk "SCS ECU: a013 cord temp hi fold bk";
CM_ SG_ 869 SCS_a014_coolantTempHiFoldBk "SCS ECU: a014 coolant temp hi fold bk";
CM_ SG_ 869 SCS_a015_cpldRationality "SCS ECU: a015 cpld rationality";
CM_ SG_ 869 SCS_a016_unusedHW16 "SCS ECU: a016 unused HW16";
CM_ SG_ 869 SCS_a017_unusedHW17 "SCS ECU: a017 unused HW17";
CM_ SG_ 869 SCS_a018_unusedHW18 "SCS ECU: a018 unused HW18";
CM_ SG_ 869 SCS_a019_unusedHW19 "SCS ECU: a019 unused HW19";
CM_ SG_ 869 SCS_a020_unusedHW20 "SCS ECU: a020 unused HW20";
CM_ SG_ 869 SCS_a021_unusedHW21 "SCS ECU: a021 unused HW21";
CM_ SG_ 869 SCS_a024_emergencyShutdown "SCS ECU: a024 emergency shutdown";
CM_ SG_ 869 SCS_a025_internalIsolationFault "SCS ECU: a025 internal isolation fault";
CM_ SG_ 869 SCS_a026_internalIsolationLow "SCS ECU: a026 internal isolation low";
CM_ SG_ 869 SCS_a027_externalIsolationLow "SCS ECU: a027 external isolation low";
CM_ SG_ 869 SCS_a028_isolationRationality "SCS ECU: a028 isolation rationality";
CM_ SG_ 869 SCS_a029_VbatOV "SCS ECU: a029 vbat OV";
CM_ SG_ 869 SCS_a030_VbusOV "SCS ECU: a030 vbus OV";
CM_ SG_ 869 SCS_a031_IbatOC "SCS ECU: a031 ibat OC";
CM_ SG_ 869 SCS_a032_VBatRationality "SCS ECU: a032 v bat rationality";
CM_ SG_ 869 SCS_a033_VBusRationality "SCS ECU: a033 v bus rationality";
CM_ SG_ 869 SCS_a034_IBatRationality "SCS ECU: a034 i bat rationality";
CM_ SG_ 869 SCS_a035_unexpectedVbusBehavior "SCS ECU: a035 unexpected vbus behavior";
CM_ SG_ 869 SCS_a036_internalContactorWelded "SCS ECU: a036 internal contactor welded";
CM_ SG_ 869 SCS_a037_outputContactorWelded "SCS ECU: a037 output contactor welded";
CM_ SG_ 869 SCS_a038_contactorFailedOpen "SCS ECU: a038 contactor failed open";
CM_ SG_ 869 SCS_a039_ibatRegulation "SCS ECU: a039 ibat regulation";
CM_ SG_ 869 SCS_a040_plus12VOutOfRange "SCS ECU: a040 plus12 v out of range";
CM_ SG_ 869 SCS_a041_minus12VOutOfRange "SCS ECU: a041 minus12 v out of range";
CM_ SG_ 869 SCS_a042_pilotOutOfRange "SCS ECU: a042 pilot out of range";
CM_ SG_ 869 SCS_a043_pilotRationality "SCS ECU: a043 pilot rationality";
CM_ SG_ 869 SCS_a044_proximityRationality "SCS ECU: a044 proximity rationality";
CM_ SG_ 869 SCS_a045_pcbaOT "SCS ECU: a045 pcba OT";
CM_ SG_ 869 SCS_a046_coolantOT "SCS ECU: a046 coolant OT";
CM_ SG_ 869 SCS_a047_cordOT "SCS ECU: a047 cord OT";
CM_ SG_ 869 SCS_a048_ambientOT "SCS ECU: a048 ambient OT";
CM_ SG_ 869 SCS_a049_pcbaTempRationality "SCS ECU: a049 pcba temp rationality";
CM_ SG_ 869 SCS_a050_coolantTempRationality "SCS ECU: a050 coolant temp rationality";
CM_ SG_ 869 SCS_a051_cordTempRationality "SCS ECU: a051 cord temp rationality";
CM_ SG_ 869 SCS_a052_ambientTempRationality "SCS ECU: a052 ambient temp rationality";
CM_ SG_ 869 SCS_a053_unexpectedThermalBehavi "SCS ECU: a053 unexpected thermal behavi";
CM_ SG_ 869 SCS_a054_pumpRegulation "SCS ECU: a054 pump regulation";
CM_ SG_ 869 SCS_a055_coolantLevelLow "SCS ECU: a055 coolant level low";
CM_ SG_ 869 SCS_a056_stateTransitionDenied "SCS ECU: a056 state transition denied";
CM_ SG_ 869 SCS_a057_watchdogReset "SCS ECU: a057 watchdog reset";
CM_ SG_ 869 SCS_a058_adcRef "SCS ECU: a058 adc ref";
CM_ SG_ 869 SCS_a059_memoryError "SCS ECU: a059 memory error";
CM_ SG_ 869 SCS_a060_swHVIL "SCS ECU: a060 sw HVIL";
CM_ SG_ 869 SCS_a061_postOutOfService "SCS ECU: a061 post out of service";
CM_ SG_ 869 SCS_a062_unused "SCS ECU: a062 unused";
CM_ SG_ 869 SCS_a063_canRationality "SCS ECU: a063 can rationality";
CM_ SG_ 869 SCS_a064_vehicleCommandTimeout "SCS ECU: a064 vehicle command timeout";
CM_ BO_ 880 "SCS ECU message: alert matrix2";
CM_ SG_ 880 SCS_a065_vBatRationalityStage1 "SCS ECU: a065 v bat rationality stage1";
CM_ SG_ 880 SCS_a066_vBatRationalityStage2 "SCS ECU: a066 v bat rationality stage2";
CM_ SG_ 880 SCS_a067_vBatRationalityStage3 "SCS ECU: a067 v bat rationality stage3";
CM_ SG_ 880 SCS_a068_vBatRationalityStage4 "SCS ECU: a068 v bat rationality stage4";
CM_ SG_ 880 SCS_a069_vStageRationalityV1 "SCS ECU: a069 v stage rationality V1";
CM_ SG_ 880 SCS_a070_vStageRationalityV2 "SCS ECU: a070 v stage rationality V2";
CM_ SG_ 880 SCS_a071_chargerMIA "SCS ECU: a071 charger MIA";
CM_ SG_ 880 SCS_a072_gtwMIA "SCS ECU: a072 gtw MIA";
CM_ SG_ 880 SCS_a073_lccMIA "SCS ECU: a073 lcc MIA";
CM_ SG_ 880 SCS_a074_isoVDiffHi "SCS ECU: a074 iso v diff hi";
CM_ SG_ 880 SCS_a075_unused75 "SCS ECU: a075 unused75";
CM_ SG_ 880 SCS_a076_bmsMIA "SCS ECU: a076 bms MIA";
CM_ SG_ 880 SCS_a077_unexpectedVbatBehavior "SCS ECU: a077 unexpected vbat behavior";
CM_ SG_ 880 SCS_a078_voltageMatchTimeout "SCS ECU: a078 voltage match timeout";
CM_ SG_ 880 SCS_a079_unexpectedVbat "SCS ECU: a079 unexpected vbat";
CM_ SG_ 880 SCS_a080_lccFaulted "SCS ECU: a080 lcc faulted";
CM_ SG_ 880 SCS_a081_rmsInputVoltageHigh "SCS ECU: a081 rms input voltage high";
CM_ SG_ 880 SCS_a082_VbatUV "SCS ECU: a082 vbat UV";
CM_ SG_ 880 SCS_a083_chargeCurrentLimited "SCS ECU: a083 charge current limited";
CM_ SG_ 880 SCS_a084_unused84 "SCS ECU: a084 unused84";
CM_ SG_ 880 SCS_a085_unused85 "SCS ECU: a085 unused85";
CM_ SG_ 880 SCS_a086_lccResetDetected "SCS ECU: a086 lcc reset detected";
CM_ SG_ 880 SCS_a087_posCordTempRationality "SCS ECU: a087 pos cord temp rationality";
CM_ SG_ 880 SCS_a088_negCordTempRationality "SCS ECU: a088 neg cord temp rationality";
CM_ SG_ 880 SCS_a089_posCordOT "SCS ECU: a089 pos cord OT";
CM_ SG_ 880 SCS_a090_negCordOT "SCS ECU: a090 neg cord OT";
CM_ SG_ 880 SCS_a091_voltageRiseDetection "SCS ECU: a091 voltage rise detection";
CM_ SG_ 880 SCS_a092_cabEnableDeasserted "SCS ECU: a092 cab enable deasserted";
CM_ SG_ 880 SCS_a093_unused93 "SCS ECU: a093 unused93";
CM_ SG_ 880 SCS_a094_unused94 "SCS ECU: a094 unused94";
CM_ SG_ 880 SCS_a095_unused95 "SCS ECU: a095 unused95";
CM_ SG_ 880 SCS_a096_unused96 "SCS ECU: a096 unused96";
CM_ SG_ 880 SCS_a097_unused97 "SCS ECU: a097 unused97";
CM_ SG_ 880 SCS_a098_unused98 "SCS ECU: a098 unused98";
CM_ SG_ 880 SCS_a099_unused99 "SCS ECU: a099 unused99";
CM_ SG_ 880 SCS_a100_unused100 "SCS ECU: a100 unused100";
CM_ SG_ 880 SCS_a101_unused101 "SCS ECU: a101 unused101";
CM_ SG_ 880 SCS_a102_unused102 "SCS ECU: a102 unused102";
CM_ SG_ 880 SCS_a103_unused103 "SCS ECU: a103 unused103";
CM_ SG_ 880 SCS_a104_unused104 "SCS ECU: a104 unused104";
CM_ SG_ 880 SCS_a105_unused105 "SCS ECU: a105 unused105";
CM_ SG_ 880 SCS_a106_unused106 "SCS ECU: a106 unused106";
CM_ SG_ 880 SCS_a107_unused107 "SCS ECU: a107 unused107";
CM_ SG_ 880 SCS_a108_unused108 "SCS ECU: a108 unused108";
CM_ SG_ 880 SCS_a109_unused109 "SCS ECU: a109 unused109";
CM_ SG_ 880 SCS_a110_unused110 "SCS ECU: a110 unused110";
CM_ SG_ 880 SCS_a111_unused111 "SCS ECU: a111 unused111";
CM_ SG_ 880 SCS_a112_unused112 "SCS ECU: a112 unused112";
CM_ SG_ 880 SCS_a113_unused113 "SCS ECU: a113 unused113";
CM_ SG_ 880 SCS_a114_unused114 "SCS ECU: a114 unused114";
CM_ SG_ 880 SCS_a115_unused115 "SCS ECU: a115 unused115";
CM_ SG_ 880 SCS_a116_unused116 "SCS ECU: a116 unused116";
CM_ SG_ 880 SCS_a117_unused117 "SCS ECU: a117 unused117";
CM_ SG_ 880 SCS_a118_unused118 "SCS ECU: a118 unused118";
CM_ SG_ 880 SCS_a119_unused119 "SCS ECU: a119 unused119";
CM_ SG_ 880 SCS_a120_unused120 "SCS ECU: a120 unused120";
CM_ SG_ 880 SCS_a121_unused121 "SCS ECU: a121 unused121";
CM_ SG_ 880 SCS_a122_unused122 "SCS ECU: a122 unused122";
CM_ SG_ 880 SCS_a123_unused123 "SCS ECU: a123 unused123";
CM_ SG_ 880 SCS_a124_unused124 "SCS ECU: a124 unused124";
CM_ SG_ 880 SCS_a125_unused125 "SCS ECU: a125 unused125";
CM_ SG_ 880 SCS_a126_unused126 "SCS ECU: a126 unused126";
CM_ SG_ 880 SCS_a127_unused127 "SCS ECU: a127 unused127";
CM_ SG_ 880 SCS_a128_unused128 "SCS ECU: a128 unused128";
CM_ BO_ 1531 "SDCR ECU message: alert log";
CM_ SG_ 1531 SDCR_alertID "SDCR ECU: alert ID";
CM_ SG_ 1531 SDCR_alertState "SDCR ECU: alert state";
CM_ SG_ 1531 SDCR_a001_pyroSenseV "SDCR ECU: a001 pyro sense v";
CM_ SG_ 1531 SDCR_a001_HVBackupSupplyV "SDCR ECU: a001 HV backup supply v";
CM_ SG_ 1531 SDCR_a001_boostRailV "SDCR ECU: a001 boost rail v";
CM_ SG_ 1531 SDCR_a001_expectedPyroV_max "SDCR ECU: a001 expected pyro v max";
CM_ SG_ 1531 SDCR_a001_expectedPyroV_min "SDCR ECU: a001 expected pyro v min";
CM_ SG_ 1531 SDCR_a001_fromState "SDCR ECU: a001 from state";
CM_ SG_ 1531 SDCR_a004_HVBackupSupplyV "SDCR ECU: a004 HV backup supply v";
CM_ SG_ 1531 SDCR_a004_boostRailV "SDCR ECU: a004 boost rail v";
CM_ SG_ 1531 SDCR_a004_diPresent "SDCR ECU: a004 di present";
CM_ SG_ 1531 SDCR_a004_pmRunningPin "SDCR ECU: a004 pm running pin";
CM_ SG_ 1531 SDCR_a006_pyroArmed "SDCR ECU: a006 pyro armed";
CM_ SG_ 1531 SDCR_a006_triggerReason_faultCur "SDCR ECU: a006 trigger reason fault currents";
CM_ SG_ 1531 SDCR_a006_triggerReason_hvBadAtS "SDCR ECU: a006 trigger reason hv bad at speed";
CM_ SG_ 1531 SDCR_a006_triggerReason_highBack "SDCR ECU: a006 trigger reason high back EMF";
CM_ SG_ 1531 SDCR_a006_faultCurrentsDetected "SDCR ECU: a006 fault currents detected";
CM_ SG_ 1531 SDCR_a006_diUartMIA "SDCR ECU: a006 di uart MIA";
CM_ SG_ 1531 SDCR_a006_pmRunningPin "SDCR ECU: a006 pm running pin";
CM_ SG_ 1531 SDCR_a006_hvPowerGood "SDCR ECU: a006 hv power good";
CM_ SG_ 1531 SDCR_a006_hvbkupPGoodPin "SDCR ECU: a006 hvbkup p good pin";
CM_ SG_ 1531 SDCR_a006_hvPowerNotGoodQualifie "SDCR ECU: a006 hv power not good qualified";
CM_ SG_ 1531 SDCR_a006_speedValid "SDCR ECU: a006 speed valid";
CM_ SG_ 1531 SDCR_a006_speedFromVoltage "SDCR ECU: a006 speed from voltage";
CM_ SG_ 1531 SDCR_a006_HVBackupSupplyV "SDCR ECU: a006 HV backup supply v";
CM_ SG_ 1531 SDCR_a006_boostRailV "SDCR ECU: a006 boost rail v";
CM_ SG_ 1531 SDCR_a006_maxAbsSpeed "SDCR ECU: a006 max abs speed";
CM_ SG_ 1531 SDCR_a006_vBat "SDCR ECU: a006 v bat";
CM_ SG_ 1531 SDCR_a007_faultReason_faultCurre "SDCR ECU: a007 fault reason fault currents at speed";
CM_ SG_ 1531 SDCR_a007_faultReason_unmitigate "SDCR ECU: a007 fault reason unmitigated UCR";
CM_ SG_ 1531 SDCR_a007_faultReason_propagatin "SDCR ECU: a007 fault reason propagating3 PS";
CM_ SG_ 1531 SDCR_a007_speedWasValid "SDCR ECU: a007 speed was valid";
CM_ SG_ 1531 SDCR_a007_imbalanceSeen "SDCR ECU: a007 imbalance seen";
CM_ SG_ 1531 SDCR_a007_ucrSeen "SDCR ECU: a007 ucr seen";
CM_ SG_ 1531 SDCR_a007_phaseVoltagePresent "SDCR ECU: a007 phase voltage present";
CM_ SG_ 1531 SDCR_a007_speedFromVoltage "SDCR ECU: a007 speed from voltage";
CM_ SG_ 1531 SDCR_a007_transientHandling "SDCR ECU: a007 transient handling";
CM_ SG_ 1531 SDCR_a007_maxAbsElcSpeed "SDCR ECU: a007 max abs elc speed";
CM_ SG_ 1531 SDCR_a007_avgIa "SDCR ECU: a007 avg ia";
CM_ SG_ 1531 SDCR_a007_avgIb "SDCR ECU: a007 avg ib";
CM_ SG_ 1531 SDCR_a007_maxAbsCurrents "SDCR ECU: a007 max abs currents";
CM_ SG_ 1531 SDCR_a008_dcLinkInfo "SDCR ECU: a008 dc link info";
CM_ SG_ 1531 SDCR_a009_diVersion "SDCR ECU: a009 di version";
CM_ SG_ 1531 SDCR_a009_sdcVersion "SDCR ECU: a009 sdc version";
CM_ SG_ 1531 SDCR_a010_pgood "SDCR ECU: a010 pgood";
CM_ SG_ 1531 SDCR_a010_boostRailV "SDCR ECU: a010 boost rail v";
CM_ SG_ 1531 SDCR_a010_Vref "SDCR ECU: a010 vref";
CM_ SG_ 1531 SDCR_a011_IaAvg "SDCR ECU: a011 ia avg";
CM_ SG_ 1531 SDCR_a011_IbAvg "SDCR ECU: a011 ib avg";
CM_ SG_ 1531 SDCR_a012_boostRailV "SDCR ECU: a012 boost rail v";
CM_ SG_ 1531 SDCR_a012_HVBackupSupplyV "SDCR ECU: a012 HV backup supply v";
CM_ SG_ 1531 SDCR_a012_vBat "SDCR ECU: a012 v bat";
CM_ SG_ 1531 SDCR_a012_vbkupGoodFdbk "SDCR ECU: a012 vbkup good fdbk";
CM_ SG_ 1531 SDCR_a013_boostRailV "SDCR ECU: a013 boost rail v";
CM_ SG_ 1531 SDCR_a013_HVBackupSupplyV "SDCR ECU: a013 HV backup supply v";
CM_ SG_ 1531 SDCR_a013_vBat "SDCR ECU: a013 v bat";
CM_ SG_ 1531 SDCR_a013_vbkupGoodFdbk "SDCR ECU: a013 vbkup good fdbk";
CM_ SG_ 1531 SDCR_a014_reason_vBusShortedLow "SDCR ECU: a014 reason v bus shorted low";
CM_ SG_ 1531 SDCR_a014_reason_vBusShortedHigh "SDCR ECU: a014 reason v bus shorted high";
CM_ SG_ 1531 SDCR_a014_boostRailV "SDCR ECU: a014 boost rail v";
CM_ SG_ 1531 SDCR_a014_HVBackupSupplyV "SDCR ECU: a014 HV backup supply v";
CM_ SG_ 1531 SDCR_a014_vBat "SDCR ECU: a014 v bat";
CM_ SG_ 1531 SDCR_a014_vbkupGoodFdbk "SDCR ECU: a014 vbkup good fdbk";
CM_ SG_ 1531 SDCR_a015_reason_vPhaseShortedLo "SDCR ECU: a015 reason v phase shorted low";
CM_ SG_ 1531 SDCR_a015_reason_vPhaseShortedHi "SDCR ECU: a015 reason v phase shorted high";
CM_ SG_ 1531 SDCR_a015_diSwitchingPin "SDCR ECU: a015 di switching pin";
CM_ SG_ 1531 SDCR_a015_vBat "SDCR ECU: a015 v bat";
CM_ SG_ 1531 SDCR_a015_va "SDCR ECU: a015 va";
CM_ SG_ 1531 SDCR_a015_vb "SDCR ECU: a015 vb";
CM_ SG_ 1531 SDCR_a015_vc "SDCR ECU: a015 vc";
CM_ SG_ 1531 SDCR_a017_expectedConfigWord "SDCR ECU: a017 expected config word";
CM_ SG_ 1531 SDCR_a017_receivedConfigWord "SDCR ECU: a017 received config word";
CM_ SG_ 1531 SDCR_a018_pyroArmed "SDCR ECU: a018 pyro armed";
CM_ SG_ 1531 SDCR_a018_triggerReason_faultCur "SDCR ECU: a018 trigger reason fault currents";
CM_ SG_ 1531 SDCR_a018_triggerReason_hvBadAtS "SDCR ECU: a018 trigger reason hv bad at speed";
CM_ SG_ 1531 SDCR_a018_triggerReason_highBack "SDCR ECU: a018 trigger reason high back EMF";
CM_ SG_ 1531 SDCR_a018_faultCurrentsDetected "SDCR ECU: a018 fault currents detected";
CM_ SG_ 1531 SDCR_a018_diUartMIA "SDCR ECU: a018 di uart MIA";
CM_ SG_ 1531 SDCR_a018_pmRunningPin "SDCR ECU: a018 pm running pin";
CM_ SG_ 1531 SDCR_a018_hvPowerGood "SDCR ECU: a018 hv power good";
CM_ SG_ 1531 SDCR_a018_hvbkupPGoodPin "SDCR ECU: a018 hvbkup p good pin";
CM_ SG_ 1531 SDCR_a018_hvPowerNotGoodQualifie "SDCR ECU: a018 hv power not good qualified";
CM_ SG_ 1531 SDCR_a018_speedValid "SDCR ECU: a018 speed valid";
CM_ SG_ 1531 SDCR_a018_speedFromVoltage "SDCR ECU: a018 speed from voltage";
CM_ SG_ 1531 SDCR_a018_HVBackupSupplyV "SDCR ECU: a018 HV backup supply v";
CM_ SG_ 1531 SDCR_a018_boostRailV "SDCR ECU: a018 boost rail v";
CM_ SG_ 1531 SDCR_a018_maxAbsSpeed "SDCR ECU: a018 max abs speed";
CM_ SG_ 1531 SDCR_a018_vBat "SDCR ECU: a018 v bat";
CM_ SG_ 1531 SDCR_a019_faultReason_faultCurre "SDCR ECU: a019 fault reason fault currents at speed";
CM_ SG_ 1531 SDCR_a019_faultReason_unmitigate "SDCR ECU: a019 fault reason unmitigated UCR";
CM_ SG_ 1531 SDCR_a019_faultReason_propagatin "SDCR ECU: a019 fault reason propagating3 PS";
CM_ SG_ 1531 SDCR_a019_speedWasValid "SDCR ECU: a019 speed was valid";
CM_ SG_ 1531 SDCR_a019_imbalanceSeen "SDCR ECU: a019 imbalance seen";
CM_ SG_ 1531 SDCR_a019_ucrSeen "SDCR ECU: a019 ucr seen";
CM_ SG_ 1531 SDCR_a019_phaseVoltagePresent "SDCR ECU: a019 phase voltage present";
CM_ SG_ 1531 SDCR_a019_speedFromVoltage "SDCR ECU: a019 speed from voltage";
CM_ SG_ 1531 SDCR_a019_transientHandling "SDCR ECU: a019 transient handling";
CM_ SG_ 1531 SDCR_a019_maxAbsElcSpeed "SDCR ECU: a019 max abs elc speed";
CM_ SG_ 1531 SDCR_a019_avgIa "SDCR ECU: a019 avg ia";
CM_ SG_ 1531 SDCR_a019_avgIb "SDCR ECU: a019 avg ib";
CM_ SG_ 1531 SDCR_a019_maxAbsCurrents "SDCR ECU: a019 max abs currents";
CM_ SG_ 1531 SDCR_a020_errorCode "SDCR ECU: a020 error code";
CM_ SG_ 1531 SDCR_a020_rxData0 "SDCR ECU: a020 rx data0";
CM_ SG_ 1531 SDCR_a020_rxData1 "SDCR ECU: a020 rx data1";
CM_ SG_ 1531 SDCR_a020_rxData2 "SDCR ECU: a020 rx data2";
CM_ SG_ 1531 SDCR_a020_rxData3 "SDCR ECU: a020 rx data3";
CM_ SG_ 1531 SDCR_a020_rxData4 "SDCR ECU: a020 rx data4";
CM_ SG_ 1531 SDCR_a021_busBarTempC "SDCR ECU: a021 bus bar temp c; raw 0 = signal not available (SNA)";
CM_ SG_ 1531 SDCR_a021_busBarTempA "SDCR ECU: a021 bus bar temp a; raw 0 = signal not available (SNA)";
CM_ SG_ 1531 SDCR_a021_tempCVoltage "SDCR ECU: a021 temp c voltage";
CM_ SG_ 1531 SDCR_a021_tempAVoltage "SDCR ECU: a021 temp a voltage";
CM_ SG_ 1531 SDCR_a024_time "SDCR ECU: a024 time";
CM_ SG_ 1531 SDCR_a025_diSwitchingFromUart "SDCR ECU: a025 di switching from uart";
CM_ SG_ 1531 SDCR_a025_diSwitchingPin "SDCR ECU: a025 di switching pin";
CM_ SG_ 1531 SDCR_a025_pmRunningPin "SDCR ECU: a025 pm running pin";
CM_ SG_ 1531 SDCR_a025_diUartMIA "SDCR ECU: a025 di uart MIA";
CM_ SG_ 1531 SDCR_a025_HVBackupSupplyV "SDCR ECU: a025 HV backup supply v";
CM_ SG_ 1531 SDCR_a025_boostRailV "SDCR ECU: a025 boost rail v";
CM_ SG_ 1531 SDCR_a028_LVPowerState "SDCR ECU: a028 LV power state";
CM_ SG_ 1531 SDCR_a029_uartCommsMissing "SDCR ECU: a029 uart comms missing";
CM_ SG_ 1531 SDCR_a029_canCommsMissing "SDCR ECU: a029 can comms missing";
CM_ SG_ 1531 SDCR_a029_lvState "SDCR ECU: a029 lv state";
CM_ SG_ 1531 SDCR_a034_Ia "SDCR ECU: a034 ia";
CM_ SG_ 1531 SDCR_a034_Ib "SDCR ECU: a034 ib";
CM_ BO_ 1467 "SDCR ECU message: alert matrix";
CM_ SG_ 1467 SDCR_matrixIndex "SDCR ECU: matrix index";
CM_ SG_ 1467 SDCR_a001_powerOnSelfTestFailed "SDCR ECU: a001 power on self test failed";
CM_ SG_ 1467 SDCR_a002_diPstSkipped "SDCR ECU: a002 di pst skipped";
CM_ SG_ 1467 SDCR_a003_diUartMIA "SDCR ECU: a003 di uart MIA";
CM_ SG_ 1467 SDCR_a004_pmRunningFdbkIrrationa "SDCR ECU: a004 pm running fdbk irrational";
CM_ SG_ 1467 SDCR_a005_motorSpeedIrrational "SDCR ECU: a005 motor speed irrational";
CM_ SG_ 1467 SDCR_a006_pyroTriggered "SDCR ECU: a006 pyro triggered";
CM_ SG_ 1467 SDCR_a007_faultCurrentsDetected "SDCR ECU: a007 fault currents detected";
CM_ SG_ 1467 SDCR_a008_hvlinkMIA "SDCR ECU: a008 hvlink MIA";
CM_ SG_ 1467 SDCR_a009_uartVersionMismatch "SDCR ECU: a009 uart version mismatch";
CM_ SG_ 1467 SDCR_a010_vrefIrrational "SDCR ECU: a010 vref irrational";
CM_ SG_ 1467 SDCR_a011_phaseCurrentOffset "SDCR ECU: a011 phase current offset";
CM_ SG_ 1467 SDCR_a012_vBoostSecIrrational "SDCR ECU: a012 v boost sec irrational";
CM_ SG_ 1467 SDCR_a013_vBkupIrrational "SDCR ECU: a013 v bkup irrational";
CM_ SG_ 1467 SDCR_a014_vBusIrrational "SDCR ECU: a014 v bus irrational";
CM_ SG_ 1467 SDCR_a015_phaseVIrrational "SDCR ECU: a015 phase v irrational";
CM_ SG_ 1467 SDCR_a016_systemReset "SDCR ECU: a016 system reset";
CM_ SG_ 1467 SDCR_a017_adcSPIError "SDCR ECU: a017 adc SPI error";
CM_ SG_ 1467 SDCR_a018_historicalPyroTrigger "SDCR ECU: a018 historical pyro trigger";
CM_ SG_ 1467 SDCR_a019_historicalFaultCurrent "SDCR ECU: a019 historical fault currents";
CM_ SG_ 1467 SDCR_a020_eepromSPIError "SDCR ECU: a020 eeprom SPI error";
CM_ SG_ 1467 SDCR_a021_busBarTempIrrational "SDCR ECU: a021 bus bar temp irrational";
CM_ SG_ 1467 SDCR_a022_TaskInitError "SDCR ECU: a022 task init error";
CM_ SG_ 1467 SDCR_a023_ecuLogAvailable "SDCR ECU: a023 ecu log available";
CM_ SG_ 1467 SDCR_a024_gtwMIA "SDCR ECU: a024 gtw MIA";
CM_ SG_ 1467 SDCR_a025_diSwitchingFdbkIrratio "SDCR ECU: a025 di switching fdbk irrational";
CM_ SG_ 1467 SDCR_a026_faultCurrentMonitoring "SDCR ECU: a026 fault current monitoring disabled";
CM_ SG_ 1467 SDCR_a027_diCanMIA "SDCR ECU: a027 di can MIA";
CM_ SG_ 1467 SDCR_a028_vcLVStateMIA "SDCR ECU: a028 vc LV state MIA";
CM_ SG_ 1467 SDCR_a029_diMIA "SDCR ECU: a029 di MIA";
CM_ SG_ 1467 SDCR_a030_placeholder30 "SDCR ECU: a030 placeholder30";
CM_ SG_ 1467 SDCR_a031_placeholder31 "SDCR ECU: a031 placeholder31";
CM_ SG_ 1467 SDCR_a032_placeholder32 "SDCR ECU: a032 placeholder32";
CM_ SG_ 1467 SDCR_a033_placeholder33 "SDCR ECU: a033 placeholder33";
CM_ SG_ 1467 SDCR_a034_phaseCurrentIrrational "SDCR ECU: a034 phase current irrational";
CM_ BO_ 1597 "SDCR ECU message: info";
CM_ SG_ 1597 SDCR_infoIndex "SDCR ECU: info index";
CM_ SG_ 1597 SDCR_infoBuildType "SDCR ECU: info build type";
CM_ SG_ 1597 SDCR_infoBuildConfigId "SDCR ECU: info build config id";
CM_ SG_ 1597 SDCR_infoHardwareId "SDCR ECU: info hardware id";
CM_ SG_ 1597 SDCR_infoComponentId "SDCR ECU: info component id";
CM_ SG_ 1597 SDCR_infoPcbaId "SDCR ECU: info pcba id";
CM_ SG_ 1597 SDCR_infoAssemblyId "SDCR ECU: info assembly id";
CM_ SG_ 1597 SDCR_infoUsageId "SDCR ECU: info usage id";
CM_ SG_ 1597 SDCR_infoSubUsageId "SDCR ECU: info sub usage id";
CM_ SG_ 1597 SDCR_infoAppCrc "SDCR ECU: info app crc";
CM_ SG_ 1597 SDCR_infoBootGitHash "SDCR ECU: info boot git hash";
BA_DEF_ BO_ "GenMsgCycleTime" INT 0 3600000;
BA_DEF_ BO_ "GenMsgSendType" ENUM "Cyclic","NotUsed","NotUsed","NotUsed","NotUsed","NotUsed","NotUsed","IfActive","NoMsgSendType","NotUsed";
BA_DEF_ BO_ "VFrameFormat" ENUM "StandardCAN","ExtendedCAN","reserved","J1939PG","reserved","reserved","reserved","reserved","reserved","reserved","reserved","reserved","reserved","reserved","StandardCAN_FD","ExtendedCAN_FD";
BA_DEF_ BO_ "CANFD_BRS" ENUM "0","1";
BA_DEF_ SG_ "GenSigSNA" STRING;
BA_DEF_ SG_ "SystemSignalLongSymbol" STRING;
BA_DEF_ SG_ "Confidence" ENUM "validated","plausible","layout-only","contradicted";
BA_DEF_DEF_ "GenMsgCycleTime" 0;
BA_DEF_DEF_ "GenMsgSendType" "NoMsgSendType";
BA_DEF_DEF_ "VFrameFormat" "StandardCAN";
BA_DEF_DEF_ "CANFD_BRS" "1";
BA_DEF_DEF_ "GenSigSNA" "";
BA_DEF_DEF_ "SystemSignalLongSymbol" "";
BA_DEF_DEF_ "Confidence" "layout-only";
BA_ "GenMsgCycleTime" BO_ 1551 1000;
BA_ "GenMsgSendType" BO_ 1551 0;
BA_ "GenMsgCycleTime" BO_ 837 1000;
BA_ "GenMsgSendType" BO_ 837 0;
BA_ "GenMsgCycleTime" BO_ 647 100;
BA_ "GenMsgSendType" BO_ 647 0;
BA_ "GenMsgCycleTime" BO_ 1359 100;
BA_ "GenMsgSendType" BO_ 1359 0;
BA_ "GenMsgCycleTime" BO_ 816 1000;
BA_ "GenMsgSendType" BO_ 816 0;
BA_ "GenMsgCycleTime" BO_ 585 50;
BA_ "GenMsgSendType" BO_ 585 0;
BA_ "GenMsgCycleTime" BO_ 553 100;
BA_ "GenMsgSendType" BO_ 553 0;
BA_ "GenMsgCycleTime" BO_ 297 10;
BA_ "GenMsgSendType" BO_ 297 0;
BA_ "GenMsgCycleTime" BO_ 815 1000;
BA_ "GenMsgSendType" BO_ 815 0;
BA_ "GenMsgCycleTime" BO_ 1355 1000;
BA_ "GenMsgSendType" BO_ 1355 0;
BA_ "GenMsgCycleTime" BO_ 869 1000;
BA_ "GenMsgSendType" BO_ 869 0;
BA_ "GenMsgCycleTime" BO_ 880 1000;
BA_ "GenMsgSendType" BO_ 880 0;
BA_ "GenMsgCycleTime" BO_ 1467 1000;
BA_ "GenMsgSendType" BO_ 1467 0;
BA_ "GenMsgCycleTime" BO_ 1597 1000;
BA_ "GenMsgSendType" BO_ 1597 0;
BA_ "Confidence" SG_ 1444 PM_alertID 1;
BA_ "Confidence" SG_ 1444 PM_alertState 1;
BA_ "Confidence" SG_ 1444 PM_a002_torqueMeasured 1;
BA_ "GenSigSNA" SG_ 1444 PM_a002_torqueMeasured "4096";
BA_ "Confidence" SG_ 1444 PM_a002_torqueAccelAverage 1;
BA_ "GenSigSNA" SG_ 1444 PM_a002_torqueAccelAverage "4096";
BA_ "Confidence" SG_ 1444 PM_a002_torqueAccelWindow 1;
BA_ "GenSigSNA" SG_ 1444 PM_a002_torqueAccelWindow "4096";
BA_ "Confidence" SG_ 1444 PM_a003_pedalPos 1;
BA_ "Confidence" SG_ 1444 PM_a003_zeroPointPedal 1;
BA_ "Confidence" SG_ 1444 PM_a004_torqueMeasured 1;
BA_ "GenSigSNA" SG_ 1444 PM_a004_torqueMeasured "4096";
BA_ "Confidence" SG_ 1444 PM_a004_torqueDecelAverage 1;
BA_ "GenSigSNA" SG_ 1444 PM_a004_torqueDecelAverage "4096";
BA_ "Confidence" SG_ 1444 PM_a004_torqueDecelWindow 1;
BA_ "GenSigSNA" SG_ 1444 PM_a004_torqueDecelWindow "4096";
BA_ "Confidence" SG_ 1444 PM_a005_torqueReason 1;
BA_ "Confidence" SG_ 1444 PM_a005_torqueMeasured 1;
BA_ "GenSigSNA" SG_ 1444 PM_a005_torqueMeasured "4096";
BA_ "Confidence" SG_ 1444 PM_a005_iDQmagnitude 1;
BA_ "Confidence" SG_ 1444 PM_a006_shiftState 1;
BA_ "GenSigSNA" SG_ 1444 PM_a006_shiftState "7";
BA_ "SystemSignalLongSymbol" SG_ 1444 PM_a006_requireAccelPedalCheckSp "PM_a006_requireAccelPedalCheckSpeed";
BA_ "Confidence" SG_ 1444 PM_a011_pmfHvilStatus 1;
BA_ "GenSigSNA" SG_ 1444 PM_a011_pmfHvilStatus "3";
BA_ "Confidence" SG_ 1444 PM_a011_pmrHvilStatus 1;
BA_ "GenSigSNA" SG_ 1444 PM_a011_pmrHvilStatus "3";
BA_ "Confidence" SG_ 1444 PM_a011_vehiclePowerState 1;
BA_ "Confidence" SG_ 1444 PM_a011_hvilSystemStatus 1;
BA_ "GenSigSNA" SG_ 1444 PM_a011_hvilSystemStatus "3";
BA_ "Confidence" SG_ 1444 PM_a012_errorType 1;
BA_ "Confidence" SG_ 1444 PM_a013_errorType 1;
BA_ "Confidence" SG_ 1444 PM_a014_track1Voltage 1;
BA_ "Confidence" SG_ 1444 PM_a014_track2Voltage 1;
BA_ "Confidence" SG_ 1444 PM_a014_accelErrorType 1;
BA_ "GenSigSNA" SG_ 1444 PM_a014_accelErrorType "0";
BA_ "Confidence" SG_ 1444 PM_a023_diCrsState 1;
BA_ "Confidence" SG_ 1444 PM_a023_pmCrsState 1;
BA_ "Confidence" SG_ 1444 PM_a023_crsFaultReason 1;
BA_ "Confidence" SG_ 1444 PM_a023_crsCancelReason 1;
BA_ "Confidence" SG_ 1444 PM_a023_cruiseTorquePed 1;
BA_ "Confidence" SG_ 1444 PM_a023_wheelSpdEstimateAbs 1;
BA_ "Confidence" SG_ 1444 PM_a023_accelEstimateDis 1;
BA_ "Confidence" SG_ 1444 PM_a026_reason 1;
BA_ "Confidence" SG_ 1444 PM_a030_diAebState 1;
BA_ "GenSigSNA" SG_ 1444 PM_a030_diAebState "7";
BA_ "Confidence" SG_ 1444 PM_a030_pmAebState 1;
BA_ "GenSigSNA" SG_ 1444 PM_a030_pmAebState "7";
BA_ "Confidence" SG_ 1444 PM_a030_dasAebEvent 1;
BA_ "GenSigSNA" SG_ 1444 PM_a030_dasAebEvent "3";
BA_ "Confidence" SG_ 1444 PM_a030_aebFaultReason 1;
BA_ "Confidence" SG_ 1444 PM_a030_aebUnavailableReason 1;
BA_ "Confidence" SG_ 1444 PM_a030_aebCancelReason 1;
BA_ "Confidence" SG_ 1444 PM_a030_diBrakeTorqueCommand 1;
BA_ "Confidence" SG_ 1444 PM_a036_timeSinceTxHWI 1;
BA_ "Confidence" SG_ 1444 PM_a036_timeSinceRxHWI 1;
BA_ "Confidence" SG_ 1444 PM_a036_timeSince100HzTxSWI 1;
BA_ "Confidence" SG_ 1444 PM_a036_timeSince1kHzCLK 1;
BA_ "Confidence" SG_ 1444 PM_a036_timeSince1kHzSWI 1;
BA_ "Confidence" SG_ 1444 PM_a036_timeSinceIdle 1;
BA_ "Confidence" SG_ 1444 PM_a036_ovfStackId 1;
BA_ "GenSigSNA" SG_ 1444 PM_a036_ovfStackId "15";
BA_ "Confidence" SG_ 1444 PM_a038_masterTorque 1;
BA_ "Confidence" SG_ 1444 PM_a038_slaveTorque 1;
BA_ "Confidence" SG_ 1444 PM_a038_pedalPos 1;
BA_ "SystemSignalLongSymbol" SG_ 1444 PM_a041_DAS_longControlTuningPar "PM_a041_DAS_longControlTuningParameters";
BA_ "Confidence" SG_ 1444 PM_a042_GTW_drivetrainType 1;
BA_ "Confidence" SG_ 1444 PM_a042_expectedPerformanceCfg 1;
BA_ "Confidence" SG_ 1444 PM_a044_pmCruiseState 1;
BA_ "Confidence" SG_ 1444 PM_a044_diCruiseState 1;
BA_ "Confidence" SG_ 1444 PM_a044_pmAebState 1;
BA_ "GenSigSNA" SG_ 1444 PM_a044_pmAebState "7";
BA_ "Confidence" SG_ 1444 PM_a044_diAebState 1;
BA_ "GenSigSNA" SG_ 1444 PM_a044_diAebState "7";
BA_ "Confidence" SG_ 1444 PM_a044_diBrakeTorqueCommand 1;
BA_ "Confidence" SG_ 1444 PM_a044_pmBfillTorqueAllowed 1;
BA_ "Confidence" SG_ 1444 PM_a044_pmVehicleHoldState 1;
BA_ "Confidence" SG_ 1444 PM_a044_diVehicleHoldState 1;
BA_ "Confidence" SG_ 1444 PM_a044_regenBackfillPmState 1;
BA_ "Confidence" SG_ 1444 PM_a045_regenBackfillPmState 1;
BA_ "Confidence" SG_ 1444 PM_a045_regenBackfillDiState 1;
BA_ "Confidence" SG_ 1444 PM_a045_unavailableReason 1;
BA_ "Confidence" SG_ 1444 PM_a045_diBrakeTorqueCommand 1;
BA_ "Confidence" SG_ 1444 PM_a045_pmBrakeTorqueAllowed 1;
BA_ "Confidence" SG_ 1444 PM_a046_diVhldState 1;
BA_ "Confidence" SG_ 1444 PM_a046_pmVhldState 1;
BA_ "Confidence" SG_ 1444 PM_a046_vhldFaultReason 1;
BA_ "Confidence" SG_ 1444 PM_a046_vhldUnavailableReason 1;
BA_ "Confidence" SG_ 1444 PM_a046_diBrakeTorqueCommand 1;
BA_ "Confidence" SG_ 1444 PM_a047_pmAutoparkState 1;
BA_ "GenSigSNA" SG_ 1444 PM_a047_pmAutoparkState "15";
BA_ "Confidence" SG_ 1444 PM_a047_diAutoparkState 1;
BA_ "GenSigSNA" SG_ 1444 PM_a047_diAutoparkState "15";
BA_ "Confidence" SG_ 1444 PM_a047_autoparkCancelReason 1;
BA_ "Confidence" SG_ 1444 PM_a048_vdcFaultReason 1;
BA_ "Confidence" SG_ 1444 PM_a056_errorType 1;
BA_ "Confidence" SG_ 1444 PM_a057_errorType 1;
BA_ "Confidence" SG_ 1444 PM_a060_TorqueAccelWindow 1;
BA_ "Confidence" SG_ 1444 PM_a060_TorqueDecelWindow 1;
BA_ "Confidence" SG_ 1444 PM_a060_TorqueReversalWindow 1;
BA_ "Confidence" SG_ 1444 PM_a062_errorType 1;
BA_ "Confidence" SG_ 1444 PM_a063_totalSystemTorqueCommand 1;
BA_ "Confidence" SG_ 1444 PM_a063_totalSystemTorqueMeasure 1;
BA_ "SystemSignalLongSymbol" SG_ 1444 PM_a063_totalSystemTorqueMeasure "PM_a063_totalSystemTorqueMeasured";
BA_ "Confidence" SG_ 1444 PM_a064_interventionType 1;
BA_ "Confidence" SG_ 1444 PM_a064_torqueCmdState 1;
BA_ "GenSigSNA" SG_ 1444 PM_a064_torqueCmdState "0";
BA_ "Confidence" SG_ 1444 PM_a064_UI_stoppingMode 1;
BA_ "Confidence" SG_ 1444 PM_a064_diCrsState 1;
BA_ "Confidence" SG_ 1444 PM_a064_pmCrsState 1;
BA_ "Confidence" SG_ 1444 PM_a073_errorType 1;
BA_ "Confidence" SG_ 1444 PM_a074_errorType 1;
BA_ "Confidence" SG_ 1444 PM_a075_errorType 1;
BA_ "Confidence" SG_ 1444 PM_a076_errorType 1;
BA_ "Confidence" SG_ 1444 PM_a077_errorType 1;
BA_ "Confidence" SG_ 1444 PM_a078_errorType 1;
BA_ "Confidence" SG_ 1444 PM_a084_firewallId 1;
BA_ "Confidence" SG_ 1444 PM_a084_privId 1;
BA_ "Confidence" SG_ 1444 PM_a084_faultType 1;
BA_ "Confidence" SG_ 1444 PM_a087_errorType 1;
BA_ "Confidence" SG_ 1444 PM_a092_pllClockSource 1;
BA_ "Confidence" SG_ 1551 PM_infoIndex 1;
BA_ "Confidence" SG_ 1551 PM_buildType 0;
BA_ "Confidence" SG_ 1551 PM_buildConfigurationId 0;
BA_ "Confidence" SG_ 1551 PM_hardwareId 0;
BA_ "Confidence" SG_ 1551 PM_deviceFused 0;
BA_ "Confidence" SG_ 1551 PM_componentId 0;
BA_ "Confidence" SG_ 1551 PM_pcbaId 0;
BA_ "Confidence" SG_ 1551 PM_assemblyId 0;
BA_ "Confidence" SG_ 1551 PM_usageId 0;
BA_ "Confidence" SG_ 1551 PM_subUsageId 0;
BA_ "Confidence" SG_ 1551 PM_applicationCrc 0;
BA_ "Confidence" SG_ 1551 PM_bootGitHash 0;
BA_ "Confidence" SG_ 837 PTC_infoIndex 1;
BA_ "Confidence" SG_ 837 PTC_infoBuildType 0;
BA_ "Confidence" SG_ 837 PTC_infoBuildConfigId 0;
BA_ "Confidence" SG_ 837 PTC_infoHardwareId 0;
BA_ "Confidence" SG_ 837 PTC_infoComponentId 0;
BA_ "Confidence" SG_ 837 PTC_infoPcbaId 0;
BA_ "Confidence" SG_ 837 PTC_infoAssemblyId 0;
BA_ "GenSigSNA" SG_ 837 PTC_infoAssemblyId "255";
BA_ "Confidence" SG_ 837 PTC_infoUsageId 0;
BA_ "Confidence" SG_ 837 PTC_infoSubUsageId 0;
BA_ "Confidence" SG_ 837 PTC_infoPlatformType 0;
BA_ "Confidence" SG_ 837 PTC_infoAppCrc 0;
BA_ "Confidence" SG_ 837 PTC_infoBootUdsProtoVersion 0;
BA_ "Confidence" SG_ 837 PTC_infoBootCrc 0;
BA_ "Confidence" SG_ 647 PTC_leftTempIGBT 0;
BA_ "Confidence" SG_ 647 PTC_tempOCP 0;
BA_ "Confidence" SG_ 647 PTC_rightTempIGBT 0;
BA_ "Confidence" SG_ 647 PTC_tempPCB 0;
BA_ "Confidence" SG_ 647 PTC_voltageHV 0;
BA_ "Confidence" SG_ 647 PTC_leftCurrentHV 0;
BA_ "Confidence" SG_ 647 PTC_rightCurrentHV 0;
BA_ "Confidence" SG_ 1344 SCCM_alertID 1;
BA_ "Confidence" SG_ 1344 SCCM_alertState 1;
BA_ "Confidence" SG_ 1344 SCCM_a003_debouncePosition 1;
BA_ "Confidence" SG_ 1344 SCCM_a003_rawPosition 1;
BA_ "Confidence" SG_ 1344 SCCM_a003_errorPosition 1;
BA_ "Confidence" SG_ 1344 SCCM_a003_adcValue 1;
BA_ "Confidence" SG_ 1344 SCCM_a004_debouncePosition 1;
BA_ "Confidence" SG_ 1344 SCCM_a004_rawPosition 1;
BA_ "Confidence" SG_ 1344 SCCM_a004_errorPosition 1;
BA_ "Confidence" SG_ 1344 SCCM_a004_adcValue 1;
BA_ "Confidence" SG_ 1344 SCCM_a005_debouncePosition 1;
BA_ "Confidence" SG_ 1344 SCCM_a005_rawPosition 1;
BA_ "Confidence" SG_ 1344 SCCM_a005_errorPosition 1;
BA_ "Confidence" SG_ 1344 SCCM_a005_adcValue 1;
BA_ "Confidence" SG_ 1344 SCCM_a006_debouncePosition 1;
BA_ "Confidence" SG_ 1344 SCCM_a006_rawPosition 1;
BA_ "Confidence" SG_ 1344 SCCM_a006_errorPosition 1;
BA_ "Confidence" SG_ 1344 SCCM_a006_adcValue 1;
BA_ "Confidence" SG_ 1344 SCCM_a007_debouncePosition 1;
BA_ "Confidence" SG_ 1344 SCCM_a007_rawPosition 1;
BA_ "Confidence" SG_ 1344 SCCM_a007_errorPosition 1;
BA_ "Confidence" SG_ 1344 SCCM_a007_adcValue1 1;
BA_ "Confidence" SG_ 1344 SCCM_a007_adcValue2 1;
BA_ "Confidence" SG_ 1344 SCCM_a008_debouncePosition 1;
BA_ "Confidence" SG_ 1344 SCCM_a008_rawPosition 1;
BA_ "Confidence" SG_ 1344 SCCM_a008_errorPosition 1;
BA_ "Confidence" SG_ 1344 SCCM_a008_adcValue1 1;
BA_ "Confidence" SG_ 1344 SCCM_a008_adcValue2 1;
BA_ "Confidence" SG_ 1344 SCCM_a009_debouncePosition 1;
BA_ "Confidence" SG_ 1344 SCCM_a009_rawPosition 1;
BA_ "Confidence" SG_ 1344 SCCM_a009_errorPosition 1;
BA_ "Confidence" SG_ 1344 SCCM_a009_adcValue1 1;
BA_ "Confidence" SG_ 1344 SCCM_a009_adcValue2 1;
BA_ "Confidence" SG_ 1344 SCCM_a010_debouncePosition 1;
BA_ "Confidence" SG_ 1344 SCCM_a010_rawPosition 1;
BA_ "Confidence" SG_ 1344 SCCM_a010_errorPosition 1;
BA_ "Confidence" SG_ 1344 SCCM_a010_adcValue1 1;
BA_ "Confidence" SG_ 1344 SCCM_a010_adcValue2 1;
BA_ "Confidence" SG_ 1344 SCCM_a011_debouncePosition 1;
BA_ "Confidence" SG_ 1344 SCCM_a011_rawPosition 1;
BA_ "Confidence" SG_ 1344 SCCM_a011_errorPosition 1;
BA_ "Confidence" SG_ 1344 SCCM_a011_adcValue1 1;
BA_ "Confidence" SG_ 1344 SCCM_a011_adcValue2 1;
BA_ "Confidence" SG_ 1344 SCCM_a012_debouncePosition 1;
BA_ "Confidence" SG_ 1344 SCCM_a012_rawPosition 1;
BA_ "Confidence" SG_ 1344 SCCM_a012_errorPosition 1;
BA_ "Confidence" SG_ 1344 SCCM_a012_adcValue1 1;
BA_ "Confidence" SG_ 1344 SCCM_a012_adcValue2 1;
BA_ "Confidence" SG_ 1344 SCCM_a013_voltage 1;
BA_ "Confidence" SG_ 1344 SCCM_a014_voltage 1;
BA_ "Confidence" SG_ 1344 SCCM_a015_intMainIndex 1;
BA_ "Confidence" SG_ 1344 SCCM_a015_intSubIndex 1;
BA_ "Confidence" SG_ 1344 SCCM_a015_intMemIndex 1;
BA_ "Confidence" SG_ 1344 SCCM_a016_mainAdcTest 1;
BA_ "Confidence" SG_ 1344 SCCM_a016_mainCpuTest 1;
BA_ "Confidence" SG_ 1344 SCCM_a016_wdtTest 1;
BA_ "Confidence" SG_ 1344 SCCM_a016_subCpuTest 1;
BA_ "Confidence" SG_ 1344 SCCM_a016_subAdcTest 1;
BA_ "Confidence" SG_ 1344 SCCM_a017_mainRamTest 1;
BA_ "Confidence" SG_ 1344 SCCM_a017_mainRomTest 1;
BA_ "Confidence" SG_ 1344 SCCM_a017_stackHardLimitTest 1;
BA_ "Confidence" SG_ 1344 SCCM_a017_mainDataFlashTest 1;
BA_ "Confidence" SG_ 1344 SCCM_a017_subRamTest 1;
BA_ "Confidence" SG_ 1344 SCCM_a017_subRomTest 1;
BA_ "Confidence" SG_ 1344 SCCM_a017_subStackHardLimitTest 1;
BA_ "Confidence" SG_ 1344 SCCM_a017_svError 1;
BA_ "Confidence" SG_ 1344 SCCM_a018_internalSASState 1;
BA_ "Confidence" SG_ 1344 SCCM_a019_internalSASState 1;
BA_ "Confidence" SG_ 1344 SCCM_a020_internalSASState 1;
BA_ "Confidence" SG_ 1344 SCCM_a021_adcValue1 1;
BA_ "Confidence" SG_ 1344 SCCM_a021_adcValue2 1;
BA_ "Confidence" SG_ 1344 SCCM_a021_adcValue3 1;
BA_ "Confidence" SG_ 1344 SCCM_a021_adcValue4 1;
BA_ "Confidence" SG_ 1344 SCCM_a021_adcValue5 1;
BA_ "Confidence" SG_ 1344 SCCM_a021_adcValue6 1;
BA_ "Confidence" SG_ 1344 SCCM_a022_adcValue1 1;
BA_ "Confidence" SG_ 1344 SCCM_a022_adcValue2 1;
BA_ "Confidence" SG_ 1344 SCCM_a022_adcValue3 1;
BA_ "Confidence" SG_ 1344 SCCM_a022_adcValue4 1;
BA_ "Confidence" SG_ 1344 SCCM_a022_adcValue5 1;
BA_ "Confidence" SG_ 1344 SCCM_a022_adcValue6 1;
BA_ "Confidence" SG_ 1344 SCCM_a023_adcValue1 1;
BA_ "Confidence" SG_ 1344 SCCM_a023_adcValue2 1;
BA_ "Confidence" SG_ 1344 SCCM_a023_adcValue3 1;
BA_ "Confidence" SG_ 1344 SCCM_a023_adcValue4 1;
BA_ "Confidence" SG_ 1344 SCCM_a023_adcValue5 1;
BA_ "Confidence" SG_ 1344 SCCM_a023_adcValue6 1;
BA_ "Confidence" SG_ 1344 SCCM_a024_adcValue1 1;
BA_ "Confidence" SG_ 1344 SCCM_a024_adcValue2 1;
BA_ "Confidence" SG_ 1344 SCCM_a024_adcValue3 1;
BA_ "Confidence" SG_ 1344 SCCM_a024_adcValue4 1;
BA_ "Confidence" SG_ 1344 SCCM_a024_adcValue5 1;
BA_ "Confidence" SG_ 1344 SCCM_a024_adcValue6 1;
BA_ "Confidence" SG_ 1344 SCCM_a025_taskState 1;
BA_ "Confidence" SG_ 1344 SCCM_a026_debouncePosition 1;
BA_ "Confidence" SG_ 1344 SCCM_a026_rawPosition 1;
BA_ "Confidence" SG_ 1344 SCCM_a026_errorPosition 1;
BA_ "Confidence" SG_ 1344 SCCM_a026_adcValue1 1;
BA_ "Confidence" SG_ 1344 SCCM_a026_adcValue2 1;
BA_ "Confidence" SG_ 1344 SCCM_a027_debouncePosition 1;
BA_ "Confidence" SG_ 1344 SCCM_a027_rawPosition 1;
BA_ "Confidence" SG_ 1344 SCCM_a027_errorPosition 1;
BA_ "Confidence" SG_ 1344 SCCM_a027_adcValue1 1;
BA_ "Confidence" SG_ 1344 SCCM_a027_adcValue2 1;
BA_ "Confidence" SG_ 1344 SCCM_a028_debouncePosition 1;
BA_ "Confidence" SG_ 1344 SCCM_a028_rawPosition 1;
BA_ "Confidence" SG_ 1344 SCCM_a028_errorPosition 1;
BA_ "Confidence" SG_ 1344 SCCM_a028_adcValue1 1;
BA_ "Confidence" SG_ 1344 SCCM_a028_adcValue2 1;
BA_ "Confidence" SG_ 1344 SCCM_a029_debouncePosition 1;
BA_ "Confidence" SG_ 1344 SCCM_a029_rawPosition 1;
BA_ "Confidence" SG_ 1344 SCCM_a029_errorPosition 1;
BA_ "Confidence" SG_ 1344 SCCM_a029_adcValue1 1;
BA_ "Confidence" SG_ 1344 SCCM_a029_adcValue2 1;
BA_ "Confidence" SG_ 1344 SCCM_a061_voltage 1;
BA_ "Confidence" SG_ 1344 SCCM_a062_voltage 1;
BA_ "Confidence" SG_ 1344 SCCM_a063_UntrimmedAngle 1;
BA_ "GenSigSNA" SG_ 1344 SCCM_a063_UntrimmedAngle "16383";
BA_ "Confidence" SG_ 1344 SCCM_a064_Speed 1;
BA_ "GenSigSNA" SG_ 1344 SCCM_a064_Speed "16383";
BA_ "Confidence" SG_ 1344 SCCM_a065_M1RawAngleCurrent 1;
BA_ "Confidence" SG_ 1344 SCCM_a065_M1RawAnglePrevious 1;
BA_ "Confidence" SG_ 1344 SCCM_a065_M2RawAngleCurrent 1;
BA_ "Confidence" SG_ 1344 SCCM_a065_M2RawAnglePrevious 1;
BA_ "Confidence" SG_ 1344 SCCM_a066_M1RawAngleCurrent 1;
BA_ "Confidence" SG_ 1344 SCCM_a066_M1RawAnglePrevious 1;
BA_ "Confidence" SG_ 1344 SCCM_a066_M2RawAngleCurrent 1;
BA_ "Confidence" SG_ 1344 SCCM_a066_M2RawAnglePrevious 1;
BA_ "Confidence" SG_ 1344 SCCM_a077_M1ExpectAngleCurrent 1;
BA_ "Confidence" SG_ 1344 SCCM_a077_M1ExpectAnglePrevious 1;
BA_ "Confidence" SG_ 1344 SCCM_a077_M1AngleCurrent 1;
BA_ "Confidence" SG_ 1344 SCCM_a077_M1AnglePrevious 1;
BA_ "Confidence" SG_ 1344 SCCM_a079_ChipTemperature 1;
BA_ "Confidence" SG_ 1344 SCCM_a121_turnIndicatorStalkAngl 1;
BA_ "SystemSignalLongSymbol" SG_ 1344 SCCM_a121_turnIndicatorStalkAngl "SCCM_a121_turnIndicatorStalkAngle";
BA_ "Confidence" SG_ 1344 SCCM_a121_turnIndicatorHallAngle 1;
BA_ "Confidence" SG_ 1344 SCCM_a122_turnIndicatorSpeed 1;
BA_ "Confidence" SG_ 1344 SCCM_a123_turnIndicatorStalkAngl 1;
BA_ "SystemSignalLongSymbol" SG_ 1344 SCCM_a123_turnIndicatorStalkAngl "SCCM_a123_turnIndicatorStalkAngle";
BA_ "Confidence" SG_ 1344 SCCM_a124_turnIndicatorStalkAngl 1;
BA_ "SystemSignalLongSymbol" SG_ 1344 SCCM_a124_turnIndicatorStalkAngl "SCCM_a124_turnIndicatorStalkAngle";
BA_ "Confidence" SG_ 1344 SCCM_a125_turnIndicatorHallAngle 1;
BA_ "Confidence" SG_ 1344 SCCM_a125_turnIndicatorVectorAng 1;
BA_ "SystemSignalLongSymbol" SG_ 1344 SCCM_a125_turnIndicatorVectorAng "SCCM_a125_turnIndicatorVectorAngle";
BA_ "SystemSignalLongSymbol" SG_ 1344 SCCM_a126_turnIndicatorXVectorOu "SCCM_a126_turnIndicatorXVectorOutOfRange";
BA_ "SystemSignalLongSymbol" SG_ 1344 SCCM_a126_turnIndicatorYVectorOu "SCCM_a126_turnIndicatorYVectorOutOfRange";
BA_ "SystemSignalLongSymbol" SG_ 1344 SCCM_a126_turnIndicatorZVectorOu "SCCM_a126_turnIndicatorZVectorOutOfRange";
BA_ "SystemSignalLongSymbol" SG_ 1344 SCCM_a126_turnIndicatorResu_0001 "SCCM_a126_turnIndicatorResultantOutOfRange";
BA_ "Confidence" SG_ 1344 SCCM_a126_turnIndicatorXMagnitud 1;
BA_ "SystemSignalLongSymbol" SG_ 1344 SCCM_a126_turnIndicatorXMagnitud "SCCM_a126_turnIndicatorXMagnitude";
BA_ "Confidence" SG_ 1344 SCCM_a126_turnIndicatorYMagnitud 1;
BA_ "SystemSignalLongSymbol" SG_ 1344 SCCM_a126_turnIndicatorYMagnitud "SCCM_a126_turnIndicatorYMagnitude";
BA_ "Confidence" SG_ 1344 SCCM_a126_turnIndicatorZMagnitud 1;
BA_ "SystemSignalLongSymbol" SG_ 1344 SCCM_a126_turnIndicatorZMagnitud "SCCM_a126_turnIndicatorZMagnitude";
BA_ "Confidence" SG_ 1344 SCCM_a126_turnIndicatorResultant 1;
BA_ "SystemSignalLongSymbol" SG_ 1344 SCCM_a126_turnIndicatorResultant "SCCM_a126_turnIndicatorResultantMagnitude";
BA_ "Confidence" SG_ 1359 SCCM_matrixIndex 1;
BA_ "SystemSignalLongSymbol" SG_ 1359 SCCM_a026_parkButtonInvalidSigna "SCCM_a026_parkButtonInvalidSignal";
BA_ "SystemSignalLongSymbol" SG_ 1359 SCCM_a028_parkButtonShortToGroun "SCCM_a028_parkButtonShortToGround";
BA_ "SystemSignalLongSymbol" SG_ 1359 SCCM_a121_turnIndicatorAngleInva "SCCM_a121_turnIndicatorAngleInvalid";
BA_ "SystemSignalLongSymbol" SG_ 1359 SCCM_a122_turnIndicatorSpeedInva "SCCM_a122_turnIndicatorSpeedInvalid";
BA_ "SystemSignalLongSymbol" SG_ 1359 SCCM_a123_turnIndicatorStuckActi "SCCM_a123_turnIndicatorStuckActive";
BA_ "SystemSignalLongSymbol" SG_ 1359 SCCM_a124_turnIndicatorIdleInval "SCCM_a124_turnIndicatorIdleInvalid";
BA_ "SystemSignalLongSymbol" SG_ 1359 SCCM_a125_turnIndicatorHallAngle "SCCM_a125_turnIndicatorHallAngleMismatch";
BA_ "SystemSignalLongSymbol" SG_ 1359 SCCM_a126_turnIndicatorHallMagOu "SCCM_a126_turnIndicatorHallMagOutOfRange";
BA_ "Confidence" SG_ 816 SCCM_infoIndex 1;
BA_ "Confidence" SG_ 816 SCCM_infoBuildType 0;
BA_ "Confidence" SG_ 816 SCCM_infoBuildConfigId 0;
BA_ "Confidence" SG_ 816 SCCM_infoHardwareId 0;
BA_ "Confidence" SG_ 816 SCCM_infoComponentId 0;
BA_ "Confidence" SG_ 816 SCCM_infoPcbaId 0;
BA_ "Confidence" SG_ 816 SCCM_infoAssemblyId 0;
BA_ "Confidence" SG_ 816 SCCM_infoUsageId 0;
BA_ "Confidence" SG_ 816 SCCM_infoSubUsageId 0;
BA_ "Confidence" SG_ 816 SCCM_infoPlatformType 0;
BA_ "Confidence" SG_ 816 SCCM_infoBootSvnRev 0;
BA_ "Confidence" SG_ 816 SCCM_infoBootSvnUrlHash 0;
BA_ "Confidence" SG_ 816 SCCM_infoSubcomponent1Version 0;
BA_ "Confidence" SG_ 816 SCCM_infoAppSvnHash 0;
BA_ "Confidence" SG_ 816 SCCM_infoBootSvnHash 0;
BA_ "Confidence" SG_ 816 SCCM_infoUdsProtoVersion 0;
BA_ "Confidence" SG_ 816 SCCM_infoBootCrc 0;
BA_ "Confidence" SG_ 585 SCCM_leftStalkCrc 0;
BA_ "Confidence" SG_ 585 SCCM_leftStalkCounter 0;
BA_ "Confidence" SG_ 585 SCCM_highBeamStalkStatus 0;
BA_ "GenSigSNA" SG_ 585 SCCM_highBeamStalkStatus "3";
BA_ "Confidence" SG_ 585 SCCM_washWipeButtonStatus 0;
BA_ "GenSigSNA" SG_ 585 SCCM_washWipeButtonStatus "3";
BA_ "Confidence" SG_ 585 SCCM_turnIndicatorStalkStatus 0;
BA_ "GenSigSNA" SG_ 585 SCCM_turnIndicatorStalkStatus "9";
BA_ "Confidence" SG_ 585 SCCM_turnIndicatorStalkAngle 0;
BA_ "GenSigSNA" SG_ 585 SCCM_turnIndicatorStalkAngle "4095";
BA_ "Confidence" SG_ 553 SCCM_rightStalkCrc 0;
BA_ "Confidence" SG_ 553 SCCM_rightStalkCounter 0;
BA_ "Confidence" SG_ 553 SCCM_rightStalkStatus 0;
BA_ "GenSigSNA" SG_ 553 SCCM_rightStalkStatus "6";
BA_ "Confidence" SG_ 553 SCCM_rightStalkReserved1 0;
BA_ "Confidence" SG_ 553 SCCM_parkButtonStatus 0;
BA_ "GenSigSNA" SG_ 553 SCCM_parkButtonStatus "3";
BA_ "Confidence" SG_ 553 SCCM_rightStalkReserved2 0;
BA_ "Confidence" SG_ 297 SCCM_steeringAngleCrc 0;
BA_ "Confidence" SG_ 297 SCCM_steeringAngleCounter 0;
BA_ "Confidence" SG_ 297 SCCM_supplierID 0;
BA_ "Confidence" SG_ 297 SCCM_steeringAngleSensorStatus 0;
BA_ "Confidence" SG_ 297 SCCM_steeringAngle 0;
BA_ "GenSigSNA" SG_ 297 SCCM_steeringAngle "16383";
BA_ "Confidence" SG_ 297 SCCM_steeringAngleValidity 0;
BA_ "GenSigSNA" SG_ 297 SCCM_steeringAngleValidity "3";
BA_ "Confidence" SG_ 297 SCCM_steeringAngleSpeed 0;
BA_ "Confidence" SG_ 297 SCCM_steeringAngleSensorReservd1 0;
BA_ "Confidence" SG_ 297 SCCM_steeringAngleSensorReservd2 0;
BA_ "Confidence" SG_ 297 SCCM_steeringAngleSensorReservd3 0;
BA_ "Confidence" SG_ 1356 SCM_alertID 1;
BA_ "Confidence" SG_ 1356 SCM_alertType 1;
BA_ "Confidence" SG_ 1354 SCS_alertID 1;
BA_ "Confidence" SG_ 1354 SCS_alertType 1;
BA_ "Confidence" SG_ 1354 SCS_a044_proximityV 1;
BA_ "Confidence" SG_ 1354 SCS_a074_voltageWithRo 1;
BA_ "Confidence" SG_ 1354 SCS_a074_voltageWithoutRo 1;
BA_ "Confidence" SG_ 1531 SDCR_alertID 1;
BA_ "Confidence" SG_ 1531 SDCR_alertState 1;
BA_ "Confidence" SG_ 1531 SDCR_a001_pyroSenseV 1;
BA_ "Confidence" SG_ 1531 SDCR_a001_HVBackupSupplyV 1;
BA_ "Confidence" SG_ 1531 SDCR_a001_boostRailV 1;
BA_ "Confidence" SG_ 1531 SDCR_a001_expectedPyroV_max 1;
BA_ "Confidence" SG_ 1531 SDCR_a001_expectedPyroV_min 1;
BA_ "Confidence" SG_ 1531 SDCR_a001_fromState 1;
BA_ "Confidence" SG_ 1531 SDCR_a004_HVBackupSupplyV 1;
BA_ "Confidence" SG_ 1531 SDCR_a004_boostRailV 1;
BA_ "SystemSignalLongSymbol" SG_ 1531 SDCR_a006_triggerReason_faultCur "SDCR_a006_triggerReason_faultCurrents";
BA_ "SystemSignalLongSymbol" SG_ 1531 SDCR_a006_triggerReason_hvBadAtS "SDCR_a006_triggerReason_hvBadAtSpeed";
BA_ "SystemSignalLongSymbol" SG_ 1531 SDCR_a006_triggerReason_highBack "SDCR_a006_triggerReason_highBackEMF";
BA_ "SystemSignalLongSymbol" SG_ 1531 SDCR_a006_hvPowerNotGoodQualifie "SDCR_a006_hvPowerNotGoodQualified";
BA_ "Confidence" SG_ 1531 SDCR_a006_HVBackupSupplyV 1;
BA_ "Confidence" SG_ 1531 SDCR_a006_boostRailV 1;
BA_ "Confidence" SG_ 1531 SDCR_a006_maxAbsSpeed 1;
BA_ "Confidence" SG_ 1531 SDCR_a006_vBat 1;
BA_ "SystemSignalLongSymbol" SG_ 1531 SDCR_a007_faultReason_faultCurre "SDCR_a007_faultReason_faultCurrentsAtSpeed";
BA_ "SystemSignalLongSymbol" SG_ 1531 SDCR_a007_faultReason_unmitigate "SDCR_a007_faultReason_unmitigatedUCR";
BA_ "SystemSignalLongSymbol" SG_ 1531 SDCR_a007_faultReason_propagatin "SDCR_a007_faultReason_propagating3PS";
BA_ "Confidence" SG_ 1531 SDCR_a007_transientHandling 1;
BA_ "Confidence" SG_ 1531 SDCR_a007_maxAbsElcSpeed 1;
BA_ "Confidence" SG_ 1531 SDCR_a007_avgIa 1;
BA_ "Confidence" SG_ 1531 SDCR_a007_avgIb 1;
BA_ "Confidence" SG_ 1531 SDCR_a007_maxAbsCurrents 1;
BA_ "Confidence" SG_ 1531 SDCR_a010_boostRailV 1;
BA_ "Confidence" SG_ 1531 SDCR_a010_Vref 1;
BA_ "Confidence" SG_ 1531 SDCR_a011_IaAvg 1;
BA_ "Confidence" SG_ 1531 SDCR_a011_IbAvg 1;
BA_ "Confidence" SG_ 1531 SDCR_a012_boostRailV 1;
BA_ "Confidence" SG_ 1531 SDCR_a012_HVBackupSupplyV 1;
BA_ "Confidence" SG_ 1531 SDCR_a012_vBat 1;
BA_ "Confidence" SG_ 1531 SDCR_a013_boostRailV 1;
BA_ "Confidence" SG_ 1531 SDCR_a013_HVBackupSupplyV 1;
BA_ "Confidence" SG_ 1531 SDCR_a013_vBat 1;
BA_ "Confidence" SG_ 1531 SDCR_a014_boostRailV 1;
BA_ "Confidence" SG_ 1531 SDCR_a014_HVBackupSupplyV 1;
BA_ "Confidence" SG_ 1531 SDCR_a014_vBat 1;
BA_ "SystemSignalLongSymbol" SG_ 1531 SDCR_a015_reason_vPhaseShortedLo "SDCR_a015_reason_vPhaseShortedLow";
BA_ "SystemSignalLongSymbol" SG_ 1531 SDCR_a015_reason_vPhaseShortedHi "SDCR_a015_reason_vPhaseShortedHigh";
BA_ "Confidence" SG_ 1531 SDCR_a015_vBat 1;
BA_ "Confidence" SG_ 1531 SDCR_a015_va 1;
BA_ "Confidence" SG_ 1531 SDCR_a015_vb 1;
BA_ "Confidence" SG_ 1531 SDCR_a015_vc 1;
BA_ "SystemSignalLongSymbol" SG_ 1531 SDCR_a018_triggerReason_faultCur "SDCR_a018_triggerReason_faultCurrents";
BA_ "SystemSignalLongSymbol" SG_ 1531 SDCR_a018_triggerReason_hvBadAtS "SDCR_a018_triggerReason_hvBadAtSpeed";
BA_ "SystemSignalLongSymbol" SG_ 1531 SDCR_a018_triggerReason_highBack "SDCR_a018_triggerReason_highBackEMF";
BA_ "SystemSignalLongSymbol" SG_ 1531 SDCR_a018_hvPowerNotGoodQualifie "SDCR_a018_hvPowerNotGoodQualified";
BA_ "Confidence" SG_ 1531 SDCR_a018_HVBackupSupplyV 1;
BA_ "Confidence" SG_ 1531 SDCR_a018_boostRailV 1;
BA_ "Confidence" SG_ 1531 SDCR_a018_maxAbsSpeed 1;
BA_ "Confidence" SG_ 1531 SDCR_a018_vBat 1;
BA_ "SystemSignalLongSymbol" SG_ 1531 SDCR_a019_faultReason_faultCurre "SDCR_a019_faultReason_faultCurrentsAtSpeed";
BA_ "SystemSignalLongSymbol" SG_ 1531 SDCR_a019_faultReason_unmitigate "SDCR_a019_faultReason_unmitigatedUCR";
BA_ "SystemSignalLongSymbol" SG_ 1531 SDCR_a019_faultReason_propagatin "SDCR_a019_faultReason_propagating3PS";
BA_ "Confidence" SG_ 1531 SDCR_a019_transientHandling 1;
BA_ "Confidence" SG_ 1531 SDCR_a019_maxAbsElcSpeed 1;
BA_ "Confidence" SG_ 1531 SDCR_a019_avgIa 1;
BA_ "Confidence" SG_ 1531 SDCR_a019_avgIb 1;
BA_ "Confidence" SG_ 1531 SDCR_a019_maxAbsCurrents 1;
BA_ "Confidence" SG_ 1531 SDCR_a020_errorCode 1;
BA_ "Confidence" SG_ 1531 SDCR_a021_busBarTempC 1;
BA_ "GenSigSNA" SG_ 1531 SDCR_a021_busBarTempC "0";
BA_ "Confidence" SG_ 1531 SDCR_a021_busBarTempA 1;
BA_ "GenSigSNA" SG_ 1531 SDCR_a021_busBarTempA "0";
BA_ "Confidence" SG_ 1531 SDCR_a021_tempCVoltage 1;
BA_ "Confidence" SG_ 1531 SDCR_a021_tempAVoltage 1;
BA_ "Confidence" SG_ 1531 SDCR_a025_HVBackupSupplyV 1;
BA_ "Confidence" SG_ 1531 SDCR_a025_boostRailV 1;
BA_ "Confidence" SG_ 1531 SDCR_a029_lvState 1;
BA_ "Confidence" SG_ 1531 SDCR_a034_Ia 1;
BA_ "Confidence" SG_ 1531 SDCR_a034_Ib 1;
BA_ "Confidence" SG_ 1467 SDCR_matrixIndex 1;
BA_ "SystemSignalLongSymbol" SG_ 1467 SDCR_a004_pmRunningFdbkIrrationa "SDCR_a004_pmRunningFdbkIrrational";
BA_ "SystemSignalLongSymbol" SG_ 1467 SDCR_a019_historicalFaultCurrent "SDCR_a019_historicalFaultCurrents";
BA_ "SystemSignalLongSymbol" SG_ 1467 SDCR_a025_diSwitchingFdbkIrratio "SDCR_a025_diSwitchingFdbkIrrational";
BA_ "SystemSignalLongSymbol" SG_ 1467 SDCR_a026_faultCurrentMonitoring "SDCR_a026_faultCurrentMonitoringDisabled";
BA_ "Confidence" SG_ 1597 SDCR_infoIndex 1;
BA_ "Confidence" SG_ 1597 SDCR_infoBuildType 1;
BA_ "Confidence" SG_ 1597 SDCR_infoBuildConfigId 0;
BA_ "Confidence" SG_ 1597 SDCR_infoHardwareId 0;
BA_ "Confidence" SG_ 1597 SDCR_infoSubUsageId 0;
BA_ "Confidence" SG_ 1597 SDCR_infoBootGitHash 0;
VAL_ 1444 PM_alertID 121 "a121_unintendedReset2" 120 "a120_indirectTPMSFaulted" 117 "a117_indirectTPMSHardWarningRearRight" 116 "a116_indirectTPMSHardWarningRearLeft" 115 "a115_indirectTPMSHardWarningFrontRight" 114 "a114_indirectTPMSHardWarningFrontLeft" 113 "a113_indirectTPMSSoftWarningRearRight" 112 "a112_indirectTPMSSoftWarningRearLeft" 111 "a111_indirectTPMSSoftWarningFrontRight" 110 "a110_indirectTPMSSoftWarningFrontLeft" 100 "a100_diTraceInfo1" 99 "a099_ITPMSCalibrated" 98 "a098_ITPMSTriggerDebug" 96 "a096_ITPMSConvergedGNSSAbsRadiusTimes" 95 "a095_ITPMSTimeoutGNSSConvergence" 93 "a093_accelPedalSupply" 92 "a092_xtalOscillator" 87 "a087_canHardwareBusLIPC" 86 "a086_exceptionUndefinedInstruction" 85 "a085_dpbMIA" 84 "a084_exceptionMpuFirewall" 83 "a083_ahbWriteError" 82 "a082_exceptionDataAbort2" 81 "a081_exceptionDataAbort" 80 "a080_exceptionPrefetchAbort" 79 "a079_rcuMIA" 78 "a078_canHardwareBusE" 77 "a077_canDataBusE" 76 "a076_canHardwareBusD" 75 "a075_canDataBusD" 74 "a074_canHardwareBusC" 73 "a073_canDataBusC" 72 "a072_brakeTorqueCommandInterface" 71 "a071_baseBrakingMonitor" 70 "a070_brakeTorqueSplitMonitorTrip" 69 "a069_brakeMonitorsUnhealthy" 68 "a068_brakePedalMonitor" 67 "a067_pmrMIA" 66 "a066_pmfMIA" 64 "a064_torqueIntervention" 63 "a063_torqueCommandInhibit" 62 "a062_eccError" 61 "a061_DIPMVersionMismatch" 60 "a060_onePedalDrivingInhibit" 59 "a059_ptcMIA" 58 "a058_cmpMIA" 57 "a057_canDataBusB" 56 "a056_canHardwareBusB" 55 "a055_accelPedalSyncWarn" 54 "a054_uiMIA" 53 "a053_vcfrontMIA" 52 "a052_stbCtrlDrvrDecelCflct" 51 "a051_unintDecelStbCtrl" 50 "a050_excessiveStbCtrlTrq" 49 "a049_stbCtrlInWrongDir" 48 "a048_stabilityControlInhibit" 47 "a047_inconsAutoparkState" 46 "a046_inconsVehicleHoldState" 45 "a045_regenBackfillIntervention" 44 "a044_ebrIntervention" 43 "a043_inconsistentConfig" 42 "a042_gtwMIA" 41 "a041_dasMIA" 40 "a040_latLinkLooseBoltDetectedDebug" 39 "a039_disMIA" 38 "a038_inconsistentTorqueSign" 36 "a036_preWatchdog" 35 "a035_udsTransactionInitiated" 34 "a034_trqCrossCheck" 33 "a033_appMIA" 32 "a032_registerConfigError" 31 "a031_highStackUsage" 30 "a030_inconsistentAebState" 29 "a029_cruiseRollback" 28 "a028_torqueCmdError" 26 "a026_diHeartBeatMIA" 25 "a025_unintendedReset" 24 "a024_brakeIrrational" 23 "a023_cruiseInhibit" 22 "a022_dirMIA" 21 "a021_difMIA" 19 "a019_vehicleSpeedQFDiagnostic" 17 "a017_brakeMIA" 16 "a016_bbMIA" 15 "a015_shifterMIA" 14 "a014_accelPedalError" 13 "a013_canHardwareBusA" 12 "a012_canDataBusA" 11 "a011_systemHvilNotClosed" 10 "a010_diMIA" 9 "a009_espMIA" 8 "a008_memoryError" 7 "a007_ibstMIA" 6 "a006_inconsistentDIGear" 5 "a005_torqueInNeutralOrPark" 4 "a004_excessiveDecelTorque" 3 "a003_excessiveReversalTorque" 2 "a002_excessiveAccelTorque" 1 "a001_absoluteTorque" 0 "ALERT_DO_NOT_USE_ZERO" ;
VAL_ 1444 PM_alertState 1 "SET" 0 "CLEARED" ;
VAL_ 1444 PM_a002_torqueMeasured -4096 "SNA" ;
VAL_ 1444 PM_a002_torqueAccelAverage -4096 "SNA" ;
VAL_ 1444 PM_a002_torqueAccelWindow -4096 "SNA" ;
VAL_ 1444 PM_a004_torqueMeasured -4096 "SNA" ;
VAL_ 1444 PM_a004_torqueDecelAverage -4096 "SNA" ;
VAL_ 1444 PM_a004_torqueDecelWindow -4096 "SNA" ;
VAL_ 1444 PM_a005_torqueReason 2 "SLAVE_ENABLE_IN_NEUTRAL" 1 "CURRENT_IN_NEUTRAL" 0 "TORQUE_IN_NEUTRAL" ;
VAL_ 1444 PM_a005_torqueMeasured -4096 "SNA" ;
VAL_ 1444 PM_a006_shiftState 7 "SNA" 4 "D" 3 "N" 2 "R" 1 "P" 0 "INVALID" ;
VAL_ 1444 PM_a011_pmfHvilStatus 3 "SNA" 2 "CLOSED" 1 "OPEN" 0 "DISABLED" ;
VAL_ 1444 PM_a011_pmrHvilStatus 3 "SNA" 2 "CLOSED" 1 "OPEN" 0 "DISABLED" ;
VAL_ 1444 PM_a011_vehiclePowerState 3 "DRIVE" 2 "ACCESSORY" 1 "CONDITIONING" 0 "OFF" ;
VAL_ 1444 PM_a011_hvilSystemStatus 3 "SNA" 2 "CLOSED" 1 "OPEN" 0 "DISABLED" ;
VAL_ 1444 PM_a012_errorType 6 "UNKNOWN_ID" 5 "DATA_INVALID" 4 "SEQUENCE" 3 "CHECKSUM" 2 "LENGTH_LONG" 1 "LENGTH_SHORT" 0 "NONE" ;
VAL_ 1444 PM_a013_errorType 5 "IPC_TX_OVERRUN" 4 "IPC_RX_OVERRUN" 3 "TX_OVERRUN" 2 "RX_OVERRUN" 1 "TX" 0 "RX" ;
VAL_ 1444 PM_a014_accelErrorType 3 "AccelTracksOutOfSync" 2 "Accel2RangeError" 1 "Accel1RangeError" 0 "SNA" ;
VAL_ 1444 PM_a023_diCrsState 7 "PRE_CANCEL" 6 "PRE_FAULT" 5 "FAULT" 4 "OVERRIDE" 3 "STANDSTILL" 2 "ENABLED" 1 "STANDBY" 0 "UNAVAILABLE" ;
VAL_ 1444 PM_a023_pmCrsState 7 "PRE_CANCEL" 6 "PRE_FAULT" 5 "FAULT" 4 "OVERRIDE" 3 "STANDSTILL" 2 "ENABLED" 1 "STANDBY" 0 "UNAVAILABLE" ;
VAL_ 1444 PM_a023_crsFaultReason 18 "VDC_FAULT" 17 "APC_FAULT" 16 "DECEL" 15 "ACCEL" 14 "TORQUE" 13 "DI_MIA" 12 "JERK_RQ" 11 "ACCEL_RQ" 10 "TC_FAULT" 9 "EPB_FAULT" 7 "CONFIG" 6 "WHEEL_SPDS_INVAL" 5 "EPB_MIA" 4 "SCCM_MIA" 3 "ESP_MIA" 2 "ESP_FAULT" 1 "EBR_FAULT" 0 "NONE" ;
VAL_ 1444 PM_a023_crsCancelReason 10 "SKID" 9 "STALK_CMD" 8 "BRAKE" 7 "EPB" 6 "DAS" 5 "TC" 4 "ESP" 3 "GEAR" 2 "AEB_ACTIVE" 1 "OFF_BTN" 0 "NONE" ;
VAL_ 1444 PM_a026_reason 1 "TooFast" 0 "TooSlow" ;
VAL_ 1444 PM_a030_diAebState 7 "SNA" 5 "UNAVAILABLE_ALERT" 4 "FAULT" 3 "STANDSTILL" 2 "ENABLED" 1 "STANDBY" 0 "UNAVAILABLE" ;
VAL_ 1444 PM_a030_pmAebState 7 "SNA" 5 "UNAVAILABLE_ALERT" 4 "FAULT" 3 "STANDSTILL" 2 "ENABLED" 1 "STANDBY" 0 "UNAVAILABLE" ;
VAL_ 1444 PM_a030_dasAebEvent 3 "SNA" 2 "FAULT" 1 "ACTIVE" 0 "NOT_ACTIVE" ;
VAL_ 1444 PM_a030_aebFaultReason 6 "SPEED_DELTA" 5 "ESP_FAULT" 4 "EBR_FAULT" 3 "WHEEL_SPEEDS_INVALID" 2 "ESP_MIA" 0 "NONE" ;
VAL_ 1444 PM_a030_aebUnavailableReason 9 "UNAVAILABLE_DAS_CONTROL_MIA" 8 "UNAVAILABLE_REVERSE_SPEED" 7 "UNAVAILABLE_EBR" 6 "UNAVAILABLE_NEGATIVE_SPEED" 5 "UNAVAILABLE_GEAR" 4 "UNAVAILABLE_SKID" 3 "UNAVAILABLE_ESP_UNAVAILABLE" 2 "UNAVAILABLE_DI_STATE" 1 "UNAVAILBLE_EPB_PARK" 0 "UNAVAILABLE_NONE" ;
VAL_ 1444 PM_a030_aebCancelReason 2 "EPB_FAULT" 1 "DAS" 0 "NONE" ;
VAL_ 1444 PM_a036_ovfStackId 15 "SNA" ;
VAL_ 1444 PM_a042_GTW_drivetrainType 1 "AWD" 0 "RWD" ;
VAL_ 1444 PM_a042_expectedPerformanceCfg 1 "AWD" 0 "RWD" ;
VAL_ 1444 PM_a044_pmCruiseState 7 "PRE_CANCEL" 6 "PRE_FAULT" 5 "FAULT" 4 "OVERRIDE" 3 "STANDSTILL" 2 "ENABLED" 1 "STANDBY" 0 "UNAVAILABLE" ;
VAL_ 1444 PM_a044_diCruiseState 7 "PRE_CANCEL" 6 "PRE_FAULT" 5 "FAULT" 4 "OVERRIDE" 3 "STANDSTILL" 2 "ENABLED" 1 "STANDBY" 0 "UNAVAILABLE" ;
VAL_ 1444 PM_a044_pmAebState 7 "SNA" 5 "UNAVAILABLE_ALERT" 4 "FAULT" 3 "STANDSTILL" 2 "ENABLED" 1 "STANDBY" 0 "UNAVAILABLE" ;
VAL_ 1444 PM_a044_diAebState 7 "SNA" 5 "UNAVAILABLE_ALERT" 4 "FAULT" 3 "STANDSTILL" 2 "ENABLED" 1 "STANDBY" 0 "UNAVAILABLE" ;
VAL_ 1444 PM_a044_pmVehicleHoldState 7 "INIT" 6 "FAULT" 5 "PARK" 4 "BLEND_OUT" 3 "STANDSTILL" 2 "BLEND_IN" 1 "STANDBY" 0 "UNAVAILABLE" ;
VAL_ 1444 PM_a044_diVehicleHoldState 7 "INIT" 6 "FAULT" 5 "PARK" 4 "BLEND_OUT" 3 "STANDSTILL" 2 "BLEND_IN" 1 "STANDBY" 0 "UNAVAILABLE" ;
VAL_ 1444 PM_a044_regenBackfillPmState 2 "ACTIVE" 1 "STANDBY" 0 "UNAVAILABLE" ;
VAL_ 1444 PM_a045_regenBackfillPmState 2 "ACTIVE" 1 "STANDBY" 0 "UNAVAILABLE" ;
VAL_ 1444 PM_a045_regenBackfillDiState 2 "ACTIVE" 1 "STANDBY" 0 "UNAVAILABLE" ;
VAL_ 1444 PM_a045_unavailableReason 18 "DI_LATENT_FAULT_TRIP" 17 "EBR_FULL_FAULT" 16 "PM_DISABLE_REQUEST_BPED" 15 "PM_DISABLE_REQUEST_BLEND" 14 "CARBON_CERAMIC_BRAKES" 13 "BRAKE_TEMP" 12 "EBR_FAULT" 11 "PM_DISABLE_REQUEST" 10 "TRACK_MODE_ACTIVE" 9 "VELOCITY_ESTIMATOR_UNAVAILABLE" 8 "TRACTION_CONTROL_UNAVAILABLE" 7 "ACTIVE_DAMPING_UNAVAILABLE" 6 "UI_COASTDOWN_MODE" 5 "SYSTEM_STATE" 4 "NON_DRIVE_GEAR" 3 "EBR_UNAVAILABLE" 2 "UI_DISABLE" 1 "GTW_DISABLE" 0 "NONE" ;
VAL_ 1444 PM_a046_diVhldState 7 "INIT" 6 "FAULT" 5 "PARK" 4 "BLEND_OUT" 3 "STANDSTILL" 2 "BLEND_IN" 1 "STANDBY" 0 "UNAVAILABLE" ;
VAL_ 1444 PM_a046_pmVhldState 7 "INIT" 6 "FAULT" 5 "PARK" 4 "BLEND_OUT" 3 "STANDSTILL" 2 "BLEND_IN" 1 "STANDBY" 0 "UNAVAILABLE" ;
VAL_ 1444 PM_a046_vhldFaultReason 7 "REQUESTED" 6 "WHEEL_SPDS_INVAL" 5 "EPB_MIA" 4 "ESP_MIA" 3 "ESP_FAULT" 2 "BRAKE_INVALID" 1 "EBR_FAULT" 0 "NONE" ;
VAL_ 1444 PM_a046_vhldUnavailableReason 9 "EBR" 8 "AEB_ACTIVE" 7 "CRUISE_ACTIVE" 6 "SPEED" 5 "GEAR" 4 "SKID" 3 "DI_FAULT" 2 "EPB_FAULT" 1 "EPB" 0 "NONE" ;
VAL_ 1444 PM_a047_pmAutoparkState 15 "SNA" 9 "SELFPARK_STARTED" 8 "UNPARK_COMPLETE" 7 "RESUMED" 6 "ABORTED" 5 "PAUSED" 4 "COMPLETE" 3 "ACTIVE" 2 "STARTED" 1 "STANDBY" 0 "UNAVAILABLE" ;
VAL_ 1444 PM_a047_diAutoparkState 15 "SNA" 9 "SELFPARK_STARTED" 8 "UNPARK_COMPLETE" 7 "RESUMED" 6 "ABORTED" 5 "PAUSED" 4 "COMPLETE" 3 "ACTIVE" 2 "STARTED" 1 "STANDBY" 0 "UNAVAILABLE" ;
VAL_ 1444 PM_a047_autoparkCancelReason 3 "CANCEL_SPEED_VIOLATION" 2 "CRUISE_CANCEL_TIMEOUT" 1 "CANCEL_BRAKE_APPLY" 0 "CANCEL_NONE" ;
VAL_ 1444 PM_a048_vdcFaultReason 8 "CP_ESTIMATE_MISMATCH" 7 "FAULT_EXCESSIVE_TSC_ACTIVITY" 6 "FAULT_INVALID_REQUEST" 5 "FAULT_INVALID_GEAR" 4 "FAULT_EXCESSIVE_YAW_TORQUE" 3 "FAULT_REVERSAL_YAW_TORQUE" 2 "FAULT_DECEL_UNINTENDED" 1 "FAULT_DECEL_INABILITY" 0 "FAULT_NONE" ;
VAL_ 1444 PM_a056_errorType 5 "IPC_TX_OVERRUN" 4 "IPC_RX_OVERRUN" 3 "TX_OVERRUN" 2 "RX_OVERRUN" 1 "TX" 0 "RX" ;
VAL_ 1444 PM_a057_errorType 6 "UNKNOWN_ID" 5 "DATA_INVALID" 4 "SEQUENCE" 3 "CHECKSUM" 2 "LENGTH_LONG" 1 "LENGTH_SHORT" 0 "NONE" ;
VAL_ 1444 PM_a062_errorType 12 "RAM_CORRECTABLE_DMA" 11 "RAM_CORRECTABLE_CLA" 10 "RAM_CORRECTABLE_CPU" 9 "RAM_UNCORRECTABLE_DMA" 8 "RAM_UNCORRECTABLE_CLA" 7 "RAM_UNCORRECTABLE_CPU" 6 "FLASH_FAIL1_HIGH" 5 "FLASH_FAIL1_LOW" 4 "FLASH_FAIL0_HIGH" 3 "FLASH_FAIL0_LOW" 2 "FLASH_UNCORRECTABLE_HIGH" 1 "FLASH_UNCORRECTABLE_LOW" 0 "UNKNOWN" ;
VAL_ 1444 PM_a064_interventionType 15 "excessiveMotorMz" 14 "inconsistentAxleTorque" 13 "diHeartbeat" 12 "currentAfterIntervention" 11 "switchingAfterIntervention" 10 "switchOffPathTestFail" 9 "inconsistentTorqueSign" 8 "torqueInNeutral" 7 "excessiveRegenTorque" 6 "torqueReversal" 5 "accumulatedTorque" 4 "motorMovementDetected" 3 "cruiseFault" 2 "torqueCmdInvalid" 1 "resolver" 0 "masterTorqueMonitorShutoff" ;
VAL_ 1444 PM_a064_torqueCmdState 8 "Invalid" 6 "Valid" 0 "SNA" ;
VAL_ 1444 PM_a064_UI_stoppingMode 2 "HOLD" 1 "CREEP" 0 "STANDARD" ;
VAL_ 1444 PM_a064_diCrsState 7 "PRE_CANCEL" 6 "PRE_FAULT" 5 "FAULT" 4 "OVERRIDE" 3 "STANDSTILL" 2 "ENABLED" 1 "STANDBY" 0 "UNAVAILABLE" ;
VAL_ 1444 PM_a064_pmCrsState 7 "PRE_CANCEL" 6 "PRE_FAULT" 5 "FAULT" 4 "OVERRIDE" 3 "STANDSTILL" 2 "ENABLED" 1 "STANDBY" 0 "UNAVAILABLE" ;
VAL_ 1444 PM_a073_errorType 6 "UNKNOWN_ID" 5 "DATA_INVALID" 4 "SEQUENCE" 3 "CHECKSUM" 2 "LENGTH_LONG" 1 "LENGTH_SHORT" 0 "NONE" ;
VAL_ 1444 PM_a074_errorType 5 "IPC_TX_OVERRUN" 4 "IPC_RX_OVERRUN" 3 "TX_OVERRUN" 2 "RX_OVERRUN" 1 "TX" 0 "RX" ;
VAL_ 1444 PM_a075_errorType 6 "UNKNOWN_ID" 5 "DATA_INVALID" 4 "SEQUENCE" 3 "CHECKSUM" 2 "LENGTH_LONG" 1 "LENGTH_SHORT" 0 "NONE" ;
VAL_ 1444 PM_a076_errorType 5 "IPC_TX_OVERRUN" 4 "IPC_RX_OVERRUN" 3 "TX_OVERRUN" 2 "RX_OVERRUN" 1 "TX" 0 "RX" ;
VAL_ 1444 PM_a077_errorType 6 "UNKNOWN_ID" 5 "DATA_INVALID" 4 "SEQUENCE" 3 "CHECKSUM" 2 "LENGTH_LONG" 1 "LENGTH_SHORT" 0 "NONE" ;
VAL_ 1444 PM_a078_errorType 5 "IPC_TX_OVERRUN" 4 "IPC_RX_OVERRUN" 3 "TX_OVERRUN" 2 "RX_OVERRUN" 1 "TX" 0 "RX" ;
VAL_ 1444 PM_a084_firewallId 17 "HSM_SLV" 16 "R5SS1_CORE1_AHB_MST" 15 "R5SS1_CORE0_AHB_MST" 14 "R5SS0_CORE1_AHB_MST" 13 "R5SS0_CORE0_AHB_MST" 12 "SCRM2SCRP1_SLV" 11 "SCRM2SCRP0_SLV" 10 "QSPI0_SLV" 9 "MBOX_RAM_SLV" 8 "DTHE_SLV" 7 "R5SS1_CORE1_AXIS_SLV" 6 "R5SS1_CORE0_AXIS_SLV" 5 "R5SS0_CORE1_AXIS_SLV" 4 "R5SS0_CORE0_AXIS_SLV" 3 "L2OCRAM_BANK3_SLV" 2 "L2OCRAM_BANK2_SLV" 1 "L2OCRAM_BANK1_SLV" 0 "L2OCRAM_BANK0_SLV" ;
VAL_ 1444 PM_a084_privId 10 "CPSW" 9 "ICSSM" 7 "R5FSS1_1" 6 "R5FSS1_0" 5 "R5FSS0_1" 4 "R5FSS0_0" 1 "M4FSS0_0" ;
VAL_ 1444 PM_a084_faultType 6 "SUPER_READ" 5 "SUPER_WRITE" 4 "SUPER_EXE" 3 "USER_READ" 2 "USER_WRITE" 1 "USER_EXE" 0 "NO_FAULT" ;
VAL_ 1444 PM_a087_errorType 5 "IPC_TX_OVERRUN" 4 "IPC_RX_OVERRUN" 3 "TX_OVERRUN" 2 "RX_OVERRUN" 1 "TX" 0 "RX" ;
VAL_ 1444 PM_a092_pllClockSource 2 "INTOSC1" 1 "XTAL" 0 "INTOSC2" ;
VAL_ 1551 PM_infoIndex 255 "END" 21 "DI_BUILD_DATA" 20 "UDS_PROTOCOL_BOOTCRC" 19 "VERSION_DEPRECATED" 18 "BOOTLOADER_GITHASH" 17 "APP_GITHASH" 16 "SUBCOMPONENT" 15 "BOOTLOADER_CRC" 14 "BOOTLOADER_SVN" 13 "APP_CRC" 11 "PCBAID_ASSYID_USAGEID" 10 "BUILD_HWID_COMPONENTID" 9 "DEPRECATED_9" 8 "DEPRECATED_8" 7 "DEPRECATED_7" 6 "DEPRECATED_6" 5 "DEPRECATED_5" 4 "DEPRECATED_4" 3 "DEPRECATED_3" 2 "DEPRECATED_2" 1 "DEPRECATED_1" 0 "DEPRECATED_0" ;
VAL_ 1551 PM_buildType 4 "INFO_MFG_BUILD" 3 "INFO_TRACEABLE_CI_BUILD" 2 "INFO_LOCAL_BUILD" 1 "INFO_PLATFORM_BUILD" 0 "INFO_UNKNOWN_BUILD" ;
VAL_ 1551 PM_hardwareId 252 "CONFIGURABLE_HWID_PLACEHOLDER" ;
VAL_ 837 PTC_infoIndex 255 "END" 31 "SUBCOMPONENT_GITHASH" 30 "PACKAGE_SN_8_14" 29 "PACKAGE_SN_1_7" 27 "PACKAGE_PN_15_20" 26 "PACKAGE_PN_8_14" 25 "PACKAGE_PN_1_7" 23 "SUBCOMPONENT2" 22 "VARIANTCRC" 20 "UDS_PROTOCOL_BOOTCRC" 19 "VERSION_DEPRECATED" 18 "BOOTLOADER_GITHASH" 17 "APP_GITHASH" 16 "SUBCOMPONENT" 15 "BOOTLOADER_CRC" 14 "BOOTLOADER_SVN" 13 "APP_CRC" 11 "PCBAID_ASSYID_USAGEID" 10 "BUILD_HWID_COMPONENTID" 9 "DEPRECATED_9" 8 "DEPRECATED_8" 7 "DEPRECATED_7" 6 "DEPRECATED_6" 5 "DEPRECATED_5" 4 "DEPRECATED_4" 3 "DEPRECATED_3" 2 "DEPRECATED_2" 1 "DEPRECATED_1" 0 "DEPRECATED_0" ;
VAL_ 837 PTC_infoBuildType 4 "INFO_MFG_BUILD" 3 "INFO_TRACEABLE_CI_BUILD" 2 "INFO_LOCAL_BUILD" 1 "INFO_PLATFORM_BUILD" 0 "INFO_UNKNOWN_BUILD" ;
VAL_ 837 PTC_infoAssemblyId 255 "ASSEMBLY_SNA" 1 "ASSEMBLY1" ;
VAL_ 1344 SCCM_alertID 126 "a126_turnIndicatorHallMagOutOfRange" 125 "a125_turnIndicatorHallAngleMismatch" 124 "a124_turnIndicatorIdleInvalid" 123 "a123_turnIndicatorStuckActive" 122 "a122_turnIndicatorSpeedInvalid" 121 "a121_turnIndicatorAngleInvalid" 82 "a082_runtimeTestFailed" 81 "a081_startupTestFailed" 80 "a080_ADCSelfTestFailed" 79 "a079_chipTempOutOfRange" 78 "a078_ADCCalibrationError" 77 "a077_gearAngleNotPlausible" 76 "a076_memoryError_2" 75 "a075_hardwareError_2" 74 "a074_PLLLossOfLock" 73 "a073_watchdogReset" 72 "a072_spiBitErrors" 71 "a071_angleHallSensorError" 70 "a070_angleTrimMismatch" 69 "a069_calibrationMismatch" 68 "a068_CANLVPowerState_LOC" 67 "a067_CANBusOff_2" 66 "a066_angleSpeedNotPlausible" 65 "a065_angleNotPlausible" 64 "a064_angleSpeedOutOfRange_2" 63 "a063_angleOutOfRange_2" 62 "a062_voltageLow_2" 61 "a061_voltageHigh_2" 29 "a029_parkButtonMalfunction" 28 "a028_parkButtonShortToGround" 27 "a027_parkButtonOpenCircuit" 26 "a026_parkButtonInvalidSignal" 25 "a025_runTimeError" 24 "a024_gearStalkGenErr" 23 "a023_gearStalkShortCircuit" 22 "a022_gearStalkOpenCircuit" 21 "a021_gearStalkSignalInvalid" 20 "a020_angleInternalError" 19 "a019_angleOutOfRange" 18 "a018_angleSpeedOutOfRange" 17 "a017_memoryError" 16 "a016_hardwareError" 15 "a015_softwareError" 14 "a014_voltageLow" 13 "a013_voltageHigh" 12 "a012_turnGenErr" 11 "a011_turnIndHWErr" 10 "a010_turnIndShortToGnd" 9 "a009_turnIndOpen" 8 "a008_turnIndInvalidTrans" 7 "a007_turnIndComInfo" 6 "a006_tipWipeShortToGND" 5 "a005_tipWipeOpen" 4 "a004_highBeamShortToGND" 3 "a003_highBeamOpen" 2 "a002_CANTOut" 1 "a001_CANBusOff" 0 "ALERT_DO_NOT_USE_ZERO" ;
VAL_ 1344 SCCM_alertState 1 "SET" 0 "CLEARED" ;
VAL_ 1344 SCCM_a063_UntrimmedAngle 16383 "SNA" ;
VAL_ 1344 SCCM_a064_Speed 16383 "SNA" ;
VAL_ 1359 SCCM_matrixIndex 2 "AlertMatrix2" 1 "AlertMatrix1" 0 "AlertMatrix0" ;
VAL_ 816 SCCM_infoIndex 255 "END" 20 "UDS_PROTOCOL_BOOTCRC" 18 "BOOTLOADER_SVNHASH" 17 "APP_SVNHASH" 16 "SUBCOMPONENT1" 14 "BOOTLOADER_SVN" 13 "APP_CRC" 11 "PCBAID_ASSYID_USAGEID" 10 "BUILD_HWID_COMPONENTID" ;
VAL_ 816 SCCM_infoBuildType 4 "INFO_MFG_BUILD" 3 "INFO_TRACEABLE_CI_BUILD" 2 "INFO_LOCAL_BUILD" 1 "INFO_PLATFORM_BUILD" 0 "INFO_UNKNOWN_BUILD" ;
VAL_ 585 SCCM_highBeamStalkStatus 3 "SNA" 2 "PUSH" 1 "PULL" 0 "IDLE" ;
VAL_ 585 SCCM_washWipeButtonStatus 3 "SNA" 2 "2ND_DETENT" 1 "1ST_DETENT" 0 "NOT_PRESSED" ;
VAL_ 585 SCCM_turnIndicatorStalkStatus 9 "SNA" 8 "DOWN_2" 7 "DOWN_1_5" 6 "DOWN_1" 5 "DOWN_0_5" 4 "UP_2" 3 "UP_1_5" 2 "UP_1" 1 "UP_0_5" 0 "IDLE" ;
VAL_ 585 SCCM_turnIndicatorStalkAngle 4095 "SNA" ;
VAL_ 553 SCCM_rightStalkStatus 6 "SNA" 5 "INIT" 4 "DOWN_2" 3 "DOWN_1" 2 "UP_2" 1 "UP_1" 0 "IDLE" ;
VAL_ 553 SCCM_parkButtonStatus 3 "SNA" 2 "INIT" 1 "PRESSED" 0 "NOT_PRESSED" ;
VAL_ 297 SCCM_steeringAngleSensorStatus 3 "ERROR_INIT" 2 "ERROR" 1 "INIT" 0 "OK" ;
VAL_ 297 SCCM_steeringAngle 16383 "SNA" ;
VAL_ 297 SCCM_steeringAngleValidity 3 "SNA" 2 "INIT" 1 "VALID" 0 "INVALID" ;
VAL_ 1356 SCM_alertID 91 "a091_voltageRiseDetection" 78 "a078_voltageMatchTimeout" 76 "a076_bmsMIA" 74 "a074_isoVDiffHi" 44 "a044_proximityRationality" 27 "a027_externalIsolationLow" 0 "ALERT_DO_NOT_USE_ZERO" ;
VAL_ 1356 SCM_alertType 1 "SET" 0 "CLEARED" ;
VAL_ 1354 SCS_alertID 128 "a128_unused128" 127 "a127_unused127" 126 "a126_unused126" 125 "a125_unused125" 124 "a124_unused124" 123 "a123_unused123" 122 "a122_unused122" 121 "a121_unused121" 120 "a120_unused120" 119 "a119_unused119" 118 "a118_unused118" 117 "a117_unused117" 116 "a116_unused116" 115 "a115_unused115" 114 "a114_unused114" 113 "a113_unused113" 112 "a112_unused112" 111 "a111_unused111" 110 "a110_unused110" 109 "a109_unused109" 108 "a108_unused108" 107 "a107_unused107" 106 "a106_unused106" 105 "a105_unused105" 104 "a104_unused104" 103 "a103_unused103" 102 "a102_unused102" 101 "a101_unused101" 100 "a100_unused100" 99 "a099_unused99" 98 "a098_unused98" 97 "a097_unused97" 96 "a096_unused96" 95 "a095_unused95" 94 "a094_unused94" 93 "a093_unused93" 92 "a092_cabEnableDeasserted" 91 "a091_voltageRiseDetection" 90 "a090_negCordOT" 89 "a089_posCordOT" 88 "a088_negCordTempRationality" 87 "a087_posCordTempRationality" 86 "a086_lccResetDetected" 85 "a085_unused85" 84 "a084_unused84" 83 "a083_chargeCurrentLimited" 82 "a082_VbatUV" 81 "a081_rmsInputVoltageHigh" 80 "a080_lccFaulted" 79 "a079_unexpectedVbat" 78 "a078_voltageMatchTimeout" 77 "a077_unexpectedVbatBehavior" 76 "a076_bmsMIA" 75 "a075_unused75" 74 "a074_isoVDiffHi" 73 "a073_lccMIA" 72 "a072_gtwMIA" 71 "a071_chargerMIA" 70 "a070_vStageRationalityV2" 69 "a069_vStageRationalityV1" 68 "a068_vBatRationalityStage4" 67 "a067_vBatRationalityStage3" 66 "a066_vBatRationalityStage2" 65 "a065_vBatRationalityStage1" 64 "a064_vehicleCommandTimeout" 63 "a063_canRationality" 62 "a062_unused" 61 "a061_postOutOfService" 60 "a060_swHVIL" 59 "a059_memoryError" 58 "a058_adcRef" 57 "a057_watchdogReset" 56 "a056_stateTransitionDenied" 55 "a055_coolantLevelLow" 54 "a054_pumpRegulation" 53 "a053_unexpectedThermalBehavi" 52 "a052_ambientTempRationality" 51 "a051_cordTempRationality" 50 "a050_coolantTempRationality" 49 "a049_pcbaTempRationality" 48 "a048_ambientOT" 47 "a047_cordOT" 46 "a046_coolantOT" 45 "a045_pcbaOT" 44 "a044_proximityRationality" 43 "a043_pilotRationality" 42 "a042_pilotOutOfRange" 41 "a041_minus12VOutOfRange" 40 "a040_plus12VOutOfRange" 39 "a039_ibatRegulation" 38 "a038_contactorFailedOpen" 37 "a037_outputContactorWelded" 36 "a036_internalContactorWelded" 35 "a035_unexpectedVbusBehavior" 34 "a034_IBatRationality" 33 "a033_VBusRationality" 32 "a032_VBatRationality" 31 "a031_IbatOC" 30 "a030_VbusOV" 29 "a029_VbatOV" 28 "a028_isolationRationality" 27 "a027_externalIsolationLow" 26 "a026_internalIsolationLow" 25 "a025_internalIsolationFault" 24 "a024_emergencyShutdown" 21 "a021_unusedHW21" 20 "a020_unusedHW20" 19 "a019_unusedHW19" 18 "a018_unusedHW18" 17 "a017_unusedHW17" 16 "a016_unusedHW16" 15 "a015_cpldRationality" 14 "a014_coolantTempHiFoldBk" 13 "a013_cordTempHiFoldBk" 12 "a012_hwIllegalCntrCmdV2" 11 "a011_hwIllegalCntrCmdV1" 10 "a010_hwOpen_V2" 9 "a009_hwOpen_V1" 8 "a008_hwIllegalCntrShoot" 7 "a007_hwWeld_V2" 6 "a006_hwWeld_V1" 5 "a005_hwHVIL" 4 "a004_hwVbusOV" 3 "a003_hwCordOT" 2 "a002_hwIbatOC" 1 "a001_hwDSPfault" 0 "ALERT_DO_NOT_USE_ZERO" ;
VAL_ 1354 SCS_alertType 1 "SET" 0 "CLEARED" ;
VAL_ 1531 SDCR_alertID 34 "a034_phaseCurrentIrrational" 33 "a033_placeholder33" 32 "a032_placeholder32" 31 "a031_placeholder31" 30 "a030_placeholder30" 29 "a029_diMIA" 28 "a028_vcLVStateMIA" 27 "a027_diCanMIA" 26 "a026_faultCurrentMonitoringDisabled" 25 "a025_diSwitchingFdbkIrrational" 24 "a024_gtwMIA" 23 "a023_ecuLogAvailable" 22 "a022_TaskInitError" 21 "a021_busBarTempIrrational" 20 "a020_eepromSPIError" 19 "a019_historicalFaultCurrents" 18 "a018_historicalPyroTrigger" 17 "a017_adcSPIError" 16 "a016_systemReset" 15 "a015_phaseVIrrational" 14 "a014_vBusIrrational" 13 "a013_vBkupIrrational" 12 "a012_vBoostSecIrrational" 11 "a011_phaseCurrentOffset" 10 "a010_vrefIrrational" 9 "a009_uartVersionMismatch" 8 "a008_hvlinkMIA" 7 "a007_faultCurrentsDetected" 6 "a006_pyroTriggered" 5 "a005_motorSpeedIrrational" 4 "a004_pmRunningFdbkIrrational" 3 "a003_diUartMIA" 2 "a002_diPstSkipped" 1 "a001_powerOnSelfTestFailed" 0 "ALERT_DO_NOT_USE_ZERO" ;
VAL_ 1531 SDCR_alertState 1 "SET" 0 "CLEARED" ;
VAL_ 1531 SDCR_a001_fromState 7 "SKIPPED" 6 "FAILED" 5 "PASSED" 4 "TEST_PYRO_L_ON" 3 "TEST_PYRO_BOTH_OFF2" 2 "TEST_PYRO_H_ON" 1 "TEST_PYRO_BOTH_OFF1" 0 "PENDING" ;
VAL_ 1531 SDCR_a007_transientHandling 3 "3PS_WAITED" 2 "3PS_EARLY_EXIT" 1 "SKIPPED_3PS" 0 "ALL_SKIPPED" ;
VAL_ 1531 SDCR_a019_transientHandling 3 "3PS_WAITED" 2 "3PS_EARLY_EXIT" 1 "SKIPPED_3PS" 0 "ALL_SKIPPED" ;
VAL_ 1531 SDCR_a020_errorCode 201 "FAILED_WRITE_SANITY_CHECK" 200 "FAILED_READ_SANITY_CHECK" 4 "GENERIC_SPI_ERROR" 3 "MUTEX_ERROR" 2 "PAGE_ROLLOVER" 1 "ADDRESS_OUT_OF_BOUNDS" ;
VAL_ 1531 SDCR_a021_busBarTempC 0 "SNA" ;
VAL_ 1531 SDCR_a021_busBarTempA 0 "SNA" ;
VAL_ 1531 SDCR_a029_lvState 3 "FAULT" 2 "GOING_DOWN" 1 "ON" 0 "OFF" ;
VAL_ 1467 SDCR_matrixIndex 0 "SDCR_AlertMatrix0" ;
VAL_ 1597 SDCR_infoIndex 255 "END" 41 "SUBCOMPONENT14" 40 "SUBCOMPONENT13" 39 "SUBCOMPONENT12" 38 "SUBCOMPONENT11" 37 "SUBCOMPONENT10" 36 "SUBCOMPONENT9" 35 "SUBCOMPONENT8" 34 "SUBCOMPONENT7" 33 "SUBCOMPONENT6" 32 "SUBCOMPONENT5" 31 "SUBCOMPONENT4" 24 "SUBCOMPONENT3" 23 "SUBCOMPONENT2" 20 "UDS_PROTOCOL_BOOTCRC" 19 "VERSION_DEPRECATED" 18 "BOOTLOADER_GITHASH" 17 "APP_GITHASH" 16 "SUBCOMPONENT1" 15 "BOOTLOADER_CRC" 14 "BOOTLOADER_SVN" 13 "APP_CRC" 11 "PCBAID_ASSYID_USAGEID" 10 "BUILD_HWID_COMPONENTID" 9 "DEPRECATED_9" 8 "DEPRECATED_8" 7 "DEPRECATED_7" 6 "DEPRECATED_6" 5 "DEPRECATED_5" 4 "DEPRECATED_4" 3 "DEPRECATED_3" 2 "DEPRECATED_2" 1 "DEPRECATED_1" 0 "DEPRECATED_0" ;
VAL_ 1597 SDCR_infoBuildType 4 "INFO_MFG_BUILD" 3 "INFO_TRACEABLE_CI_BUILD" 2 "INFO_LOCAL_BUILD" 1 "INFO_PLATFORM_BUILD" 0 "INFO_UNKNOWN_BUILD" ;
